VERSION ""

NS_ :

BS_:

BU_: Turbocharger OnBoardDataLogger OffBoardDiagnosticTool2 OffBoardDiagnosticTool1 FileServer ParkingBrakeController SeatControl2 FanDriveController SteeringColumnUnit CommunicationUnitRadio CommunicationUnitSatellite CommunicationUnitCellular PropulsionBatteryCharger ChassisController2 ChassisController1 EngineValveControl AuxiliaryHeater2 AuxiliaryHeater1 ClutchUnit RampControl InformationSystem1 SuspensionSystemController2 OilSensor VehicleDynamicStability ExhaustEmissionController TransmissionDisplay2 TransmissionDisplay1 ClimateControl2 WaterPumpController RearAxleSteeringController LightingOperatorControl SeatController1 IgnitionController2 IgnitionController1 TirePressureController CabController2 CabController1 PneumaticSystemController SuspensionSystemController1 HydraulicPumpController EnduranceBrakingSystem RetarderExhaustEngine2 OnBoardDiagnosticUnit HeadwayController RetarderExhaustEngine1 CabDisplay1 ManagementComputer VirtualTerminal OffVehicleGateway PowerTakeOffFront HitchControl AuxiliaryValveControl BodyController TractorTrailerBridge1 StarterSystem ElectricalSystem VehicleSecurity VehicleNavigation AerodynamicControl ElectricalChargingSystem ClimateControl1 TripRecorder InstrumentCluster SuspensionDriveAxle2 SuspensionDriveAxle1 SuspensionSteerAxle SteeringController FuelSystem CruiseControl RetarderDriveline RetarderEngine BrakesDriveAxle2 BrakesDriveAxle1 BrakesSystemController BrakesSteerAxle AxleDrive2 AxleDrive1 AxleSteering PowerTakeOff ShiftConsoleSecondary ShiftConsolePrimary Transmission2 Transmission1 Engine2 Engine1

BO_ 3221225472 VECTOR__INDEPENDENT_SIG_MSG: 0 Vector__XXX
 SG_ AuxI_O62 : 0|2@1+ (1,0) [0|3] "" Vector__XXX
 SG_ AuxI_O63 : 0|2@1+ (1,0) [0|3] "" Vector__XXX
 SG_ AuxI_O64 : 0|2@1+ (1,0) [0|3] "" Vector__XXX
 SG_ AuxI_O57 : 0|2@1+ (1,0) [0|3] "" Vector__XXX
 SG_ AuxI_O58 : 0|2@1+ (1,0) [0|3] "" Vector__XXX
 SG_ AuxI_O59 : 0|2@1+ (1,0) [0|3] "" Vector__XXX
 SG_ AuxI_O60 : 0|2@1+ (1,0) [0|3] "" Vector__XXX
 SG_ AuxI_O53 : 0|2@1+ (1,0) [0|3] "" Vector__XXX
 SG_ AuxI_O54 : 0|2@1+ (1,0) [0|3] "" Vector__XXX
 SG_ AuxI_O55 : 0|2@1+ (1,0) [0|3] "" Vector__XXX
 SG_ AuxI_O56 : 0|2@1+ (1,0) [0|3] "" Vector__XXX
 SG_ AuxI_O49 : 0|2@1+ (1,0) [0|3] "" Vector__XXX
 SG_ AuxI_O50 : 0|2@1+ (1,0) [0|3] "" Vector__XXX
 SG_ AuxI_O51 : 0|2@1+ (1,0) [0|3] "" Vector__XXX
 SG_ AuxI_O52 : 0|2@1+ (1,0) [0|3] "" Vector__XXX
 SG_ AuxI_O109 : 0|2@1+ (1,0) [0|3] "" Vector__XXX
 SG_ AuxI_O110 : 0|2@1+ (1,0) [0|3] "" Vector__XXX
 SG_ AuxI_O111 : 0|2@1+ (1,0) [0|3] "" Vector__XXX
 SG_ AuxI_O112 : 0|2@1+ (1,0) [0|3] "" Vector__XXX
 SG_ AuxI_O105 : 0|2@1+ (1,0) [0|3] "" Vector__XXX
 SG_ AuxI_O106 : 0|2@1+ (1,0) [0|3] "" Vector__XXX
 SG_ AuxI_O107 : 0|2@1+ (1,0) [0|3] "" Vector__XXX
 SG_ AuxI_O108 : 0|2@1+ (1,0) [0|3] "" Vector__XXX
 SG_ AuxI_O101 : 0|2@1+ (1,0) [0|3] "" Vector__XXX
 SG_ AuxI_O102 : 0|2@1+ (1,0) [0|3] "" Vector__XXX
 SG_ AuxI_O103 : 0|2@1+ (1,0) [0|3] "" Vector__XXX
 SG_ AuxI_O104 : 0|2@1+ (1,0) [0|3] "" Vector__XXX
 SG_ AuxI_O97 : 0|2@1+ (1,0) [0|3] "" Vector__XXX
 SG_ AuxI_O98 : 0|2@1+ (1,0) [0|3] "" Vector__XXX
 SG_ AuxI_O99 : 0|2@1+ (1,0) [0|3] "" Vector__XXX
 SG_ AuxI_O100 : 0|2@1+ (1,0) [0|3] "" Vector__XXX
 SG_ AuxI_O93 : 0|2@1+ (1,0) [0|3] "" Vector__XXX
 SG_ AuxI_O94 : 0|2@1+ (1,0) [0|3] "" Vector__XXX
 SG_ AuxI_O95 : 0|2@1+ (1,0) [0|3] "" Vector__XXX
 SG_ AuxI_O96 : 0|2@1+ (1,0) [0|3] "" Vector__XXX
 SG_ AuxI_O89 : 0|2@1+ (1,0) [0|3] "" Vector__XXX
 SG_ AuxI_O90 : 0|2@1+ (1,0) [0|3] "" Vector__XXX
 SG_ AuxI_O91 : 0|2@1+ (1,0) [0|3] "" Vector__XXX
 SG_ AuxI_O92 : 0|2@1+ (1,0) [0|3] "" Vector__XXX
 SG_ AuxI_O85 : 0|2@1+ (1,0) [0|3] "" Vector__XXX
 SG_ AuxI_O86 : 0|2@1+ (1,0) [0|3] "" Vector__XXX
 SG_ AuxI_O87 : 0|2@1+ (1,0) [0|3] "" Vector__XXX
 SG_ AuxI_O88 : 0|2@1+ (1,0) [0|3] "" Vector__XXX
 SG_ AuxI_O81 : 0|2@1+ (1,0) [0|3] "" Vector__XXX
 SG_ AuxI_O82 : 0|2@1+ (1,0) [0|3] "" Vector__XXX
 SG_ AuxI_O83 : 0|2@1+ (1,0) [0|3] "" Vector__XXX
 SG_ AuxI_O84 : 0|2@1+ (1,0) [0|3] "" Vector__XXX
 SG_ TrailerBrakeStrokeAxle5Right : 0|3@1+ (1,0) [0|7] "" Vector__XXX
 SG_ TrailerBrakeStrokeAxle5Left : 0|3@1+ (1,0) [0|7] "" Vector__XXX
 SG_ TrailerBrakeStrokeAxle4Right : 0|3@1+ (1,0) [0|7] "" Vector__XXX
 SG_ TrailerBrakeStrokeAxle4Left : 0|3@1+ (1,0) [0|7] "" Vector__XXX
 SG_ TrailerBrakeStrokeAxle3Right : 0|3@1+ (1,0) [0|7] "" Vector__XXX
 SG_ TrailerBrakeStrokeAxle3Left : 0|3@1+ (1,0) [0|7] "" Vector__XXX
 SG_ TrailerBrakeStrokeAxle2Right : 0|3@1+ (1,0) [0|7] "" Vector__XXX
 SG_ TrailerBrakeStrokeAxle2Left : 0|3@1+ (1,0) [0|7] "" Vector__XXX
 SG_ TrailerBrakeStrokeAxle1Right : 0|3@1+ (1,0) [0|7] "" Vector__XXX
 SG_ TrailerBrakeStrokeAxle1Left : 0|3@1+ (1,0) [0|7] "" Vector__XXX
 SG_ TractorBrakeStrokeAxle5Right : 0|3@1+ (1,0) [0|7] "" Vector__XXX
 SG_ TractorBrakeStrokeAxle5Left : 0|3@1+ (1,0) [0|7] "" Vector__XXX
 SG_ TractorBrakeStrokeAxle4Right : 0|3@1+ (1,0) [0|7] "" Vector__XXX
 SG_ TractorBrakeStrokeAxle4Left : 0|3@1+ (1,0) [0|7] "" Vector__XXX
 SG_ TractorBrakeStrokeAxle3Right : 0|3@1+ (1,0) [0|7] "" Vector__XXX
 SG_ TractorBrakeStrokeAxle3Left : 0|3@1+ (1,0) [0|7] "" Vector__XXX
 SG_ TractorBrakeStrokeAxle2Right : 0|3@1+ (1,0) [0|7] "" Vector__XXX
 SG_ TractorBrakeStrokeAxle2Left : 0|3@1+ (1,0) [0|7] "" Vector__XXX
 SG_ TractorBrakeStrokeAxle1Right : 0|3@1+ (1,0) [0|7] "" Vector__XXX
 SG_ TractorBrakeStrokeAxle1Left : 0|3@1+ (1,0) [0|7] "" Vector__XXX
 SG_ RoadSurfaceTemp : 0|16@1+ (0.03125,-273) [-273|1734.96875] "deg C" Vector__XXX
 SG_ EngAirIntakeTemp : 0|8@1+ (1,-40) [-40|210] "deg C" Vector__XXX
 SG_ AmbientAirTemp : 0|16@1+ (0.03125,-273) [-273|1734.96875] "deg C" Vector__XXX
 SG_ CabInteriorTemp : 0|16@1+ (0.03125,-273) [-273|1734.96875] "deg C" Vector__XXX
 SG_ BarometricPress : 0|8@1+ (0.5,0) [0|125] "kPa" Vector__XXX
 SG_ EngAirStartPress : 0|8@1+ (4,0) [0|1000] "kPa" Vector__XXX
 SG_ AirCompressorStatus : 0|2@1+ (1,0) [0|3] "" Vector__XXX
 SG_ AirSuspensionSupplyPress : 0|8@1+ (8,0) [0|2000] "kPa" Vector__XXX
 SG_ AuxEquipmentSupplyPress : 0|8@1+ (8,0) [0|2000] "kPa" Vector__XXX
 SG_ ServiceBrakeCircuit2AirPress : 0|8@1+ (8,0) [0|2000] "kPa" Vector__XXX
 SG_ ServiceBrakeCircuit1AirPress : 0|8@1+ (8,0) [0|2000] "kPa" Vector__XXX
 SG_ ParkingAnd_orTrailerAirPress : 0|8@1+ (8,0) [0|2000] "kPa" Vector__XXX
 SG_ PneumaticSupplyPress : 0|8@1+ (8,0) [0|2000] "kPa" Vector__XXX
 SG_ SteerAxleLubePress : 0|8@1+ (4,0) [0|1000] "kPa" Vector__XXX
 SG_ SteerAxleTemp : 0|8@1+ (1,-40) [-40|210] "deg C" Vector__XXX
 SG_ DriveAxleLubePress : 0|8@1+ (4,0) [0|1000] "kPa" Vector__XXX
 SG_ DriveAxleTemp : 0|8@1+ (1,-40) [-40|210] "deg C" Vector__XXX
 SG_ DriveAxleLiftAirPress : 0|8@1+ (4,0) [0|1000] "kPa" Vector__XXX
 SG_ DriveAxleLocation : 0|8@1+ (1.02,0) [0|255] "" Vector__XXX
 SG_ EngGsMssFlwSnsrFuelingCorrection : 0|8@1+ (1,-125) [-125|125] "%" Vector__XXX
 SG_ EngTurboWastegateValvePos : 0|8@1+ (0.4,0) [0|100] "%" Vector__XXX
 SG_ EngDesiredAbsIntakeManifoldPress : 0|16@1+ (1,0) [0|6425.5] "kPa" Vector__XXX
 SG_ EngGasFuelCorrectionFactor : 0|8@1+ (1,0) [0|250] "%" Vector__XXX
 SG_ RequestedACCDistanceMode : 0|3@1+ (1,0) [0|7] "" Vector__XXX
 SG_ ACCUsageDemand : 0|2@1+ (1,0) [0|3] "" Vector__XXX
 SG_ ForwardCollisionWarning : 0|2@1+ (1,0) [0|3] "" Vector__XXX
 SG_ ACCDistanceAlertSignal : 0|2@1+ (1,0) [0|3] "" Vector__XXX
 SG_ ACCSystemShutoffWarning : 0|2@1+ (1,0) [0|3] "" Vector__XXX
 SG_ ACCTargetDetected : 0|2@1+ (1,0) [0|3] "" Vector__XXX
 SG_ AdptiveCruiseCtrlSetDistanceMode : 0|3@1+ (1,0) [0|7] "" Vector__XXX
 SG_ AdaptiveCruiseCtrlMode : 0|3@1+ (1,0) [0|7] "" Vector__XXX
 SG_ AdaptiveCruiseCtrlSetSpeed : 0|8@1+ (1,0) [0|250] "km/h" Vector__XXX
 SG_ DistanceToForwardVehicle : 0|8@1+ (1,0) [0|250] "m" Vector__XXX
 SG_ SpeedOfForwardVehicle : 0|8@1+ (1,0) [0|250] "km/h" Vector__XXX
 SG_ ArticulationAngle : 0|8@1+ (1,-125) [-125|125] "deg" Vector__XXX
 SG_ RelativeHumidity : 0|8@1+ (0.4,0) [0|100] "%" Vector__XXX
 SG_ AuxLevel : 0|16@1+ (0.1,0) [0|6425.5] "mm" Vector__XXX
 SG_ AuxPress2 : 0|8@1+ (16,0) [0|4000] "kPa" Vector__XXX
 SG_ AuxPress1 : 0|8@1+ (16,0) [0|4000] "kPa" Vector__XXX
 SG_ AuxTemp2 : 0|8@1+ (1,-40) [-40|210] "deg C" Vector__XXX
 SG_ AuxTemp1 : 0|8@1+ (1,-40) [-40|210] "deg C" Vector__XXX
 SG_ EngBlowerBypassValvePos : 0|8@1+ (0.4,0) [0|100] "%" Vector__XXX
 SG_ EngGasSupplyPress : 0|16@1+ (0.5,0) [0|32127.5] "kPa" Vector__XXX
 SG_ AddressBusy : 0|8@1+ (1,0) [0|255] "" Vector__XXX
 SG_ GroupFunctionValue : 0|8@1+ (1,0) [0|255] "" Vector__XXX
 SG_ AddressAccessDenied : 0|8@1+ (1,0) [0|255] "" Vector__XXX
 SG_ AddressNegativeAcknowledgement : 0|8@1+ (1,0) [0|255] "" Vector__XXX
 SG_ AddressAcknowledged : 0|8@1+ (1,0) [0|255] "" Vector__XXX
 SG_ Status2OfDoors : 0|2@1+ (1,0) [0|3] "" Vector__XXX
 SG_ Ramp_WheelChairLiftPos : 0|2@1+ (1,0) [0|3] "" Vector__XXX
 SG_ PosOfDoors : 0|4@1+ (1,0) [0|15] "" Vector__XXX
 SG_ FifthWheelRollWarningIndicator : 0|2@1+ (1,0) [0|3] "" Vector__XXX
 SG_ FifthWheelRollMoment : 0|16@1+ (10,-320000) [-320000|322550] "N" Vector__XXX
 SG_ FifthWheelDrawbarForce : 0|16@1+ (10,-320000) [-320000|322550] "N" Vector__XXX
 SG_ FifthWheelVerticalForce : 0|16@1+ (5,0) [0|321275] "N" Vector__XXX
 SG_ FifthWheelSliderLockIndicator : 0|2@1+ (1,0) [0|3] "" Vector__XXX
 SG_ FifthWheelSliderPos : 0|8@1+ (10,0) [0|2500] "mm" Vector__XXX
 SG_ FfthWhlLockCoupleStatusIndicator : 0|2@1+ (1,0) [0|3] "" Vector__XXX
 SG_ FfthWhlLckReadyToCoupleIndicator : 0|2@1+ (1,0) [0|3] "" Vector__XXX
 SG_ FifthWheelErrorStatus : 0|4@1+ (1,0) [0|15] "" Vector__XXX
 SG_ RollAndPitchMeasurementLatency : 0|8@1+ (0.5,0) [0|125] "ms" Vector__XXX
 SG_ PitchAndRollCompensated : 0|2@1+ (1,0) [0|3] "" Vector__XXX
 SG_ PitchRateFigureOfMerit : 0|2@1+ (1,0) [0|3] "" Vector__XXX
 SG_ RollAngleFigureOfMerit : 0|2@1+ (1,0) [0|3] "" Vector__XXX
 SG_ PitchAngleFigureOfMerit : 0|2@1+ (1,0) [0|3] "" Vector__XXX
 SG_ PitchRate : 0|16@1+ (0.002,-64) [-64|64.51] "deg/sec" Vector__XXX
 SG_ RollAngle : 0|16@1+ (0.002,-64) [-64|64.51] "deg" Vector__XXX
 SG_ PitchAngle : 0|16@1+ (0.002,-64) [-64|64.51] "deg" Vector__XXX
 SG_ TransOilLevelMeasurementStatus : 0|4@1+ (1,0) [0|15] "" Vector__XXX
 SG_ TransOilLevelCountdownTimer : 0|4@1+ (1,0) [0|15] "" Vector__XXX
 SG_ TransOilLevelHigh_Low : 0|8@1+ (0.5,-62.5) [-62.5|62.5] "L" Vector__XXX
 SG_ TransOilTemp : 0|16@1+ (0.03125,-273) [-273|1734.96875] "deg C" Vector__XXX
 SG_ TransOilPress : 0|8@1+ (16,0) [0|4000] "kPa" Vector__XXX
 SG_ TransFilterDiffPress : 0|8@1+ (2,0) [0|500] "kPa" Vector__XXX
 SG_ TransOilLevel : 0|8@1+ (0.4,0) [0|100] "%" Vector__XXX
 SG_ ClutchPress : 0|8@1+ (16,0) [0|4000] "kPa" Vector__XXX
 SG_ ChargingSystemPotential : 0|16@1+ (0.05,0) [0|3212.75] "V" Vector__XXX
 SG_ KeyswitchBatteryPotential : 0|16@1+ (0.05,0) [0|3212.75] "V" Vector__XXX
 SG_ BatteryPotential_PowerInput1 : 0|16@1+ (0.05,0) [0|3212.75] "V" Vector__XXX
 SG_ WrelessCommunicationNetworkType2 : 0|8@1+ (1,0) [0|255] "" Vector__XXX
 SG_ NetworkSignalStrength2 : 0|8@1+ (1,0) [0|100] "%" Vector__XXX
 SG_ NetworkAntennaStatus2 : 0|8@1+ (1,0) [0|255] "" Vector__XXX
 SG_ NetworkServiceStatus2 : 0|8@1+ (1,0) [0|255] "" Vector__XXX
 SG_ NetworkTransceiverStatus2 : 0|8@1+ (1,0) [0|255] "" Vector__XXX
 SG_ WrelessCommunicationNetworkType1 : 0|8@1+ (1,0) [0|255] "" Vector__XXX
 SG_ NetworkSignalStrength1 : 0|8@1+ (1,0) [0|100] "%" Vector__XXX
 SG_ NetworkAntennaStatus1 : 0|8@1+ (1,0) [0|255] "" Vector__XXX
 SG_ NetworkServiceStatus1 : 0|8@1+ (1,0) [0|255] "" Vector__XXX
 SG_ NetworkTransceiverStatus1 : 0|8@1+ (1,0) [0|255] "" Vector__XXX
 SG_ VoltageRegulatorEnabled : 0|2@1+ (1,0) [0|3] "" Vector__XXX
 SG_ VoltageRegulatorSoftStartState : 0|2@1+ (1,0) [0|3] "" Vector__XXX
 SG_ VltgRgltrUndrfrqncyCmpnstnEnbld : 0|2@1+ (1,0) [0|3] "" Vector__XXX
 SG_ VltgRgltrVAr_PwrFctrOprtingMode : 0|3@1+ (1,0) [0|7] "" Vector__XXX
 SG_ VltgRglatorLoadCompensationMode : 0|3@1+ (1,0) [0|7] "" Vector__XXX
 SG_ GnrtrOtputVoltageBiasPercentage : 0|16@1+ (0.1,-100) [-100|100] "%" Vector__XXX
 SG_ GeneratorExcitationFieldCurrent : 0|16@1+ (0.05,0) [0|3217.5] "A" Vector__XXX
 SG_ GeneratorExcitationFieldVoltage : 0|16@1+ (0.05,-1605.625) [-1605.625|1606.375] "V" Vector__XXX
 SG_ RunningLightCmd : 0|2@1+ (1,0) [0|3] "" Vector__XXX
 SG_ AltBeamHeadLightCmd : 0|2@1+ (1,0) [0|3] "" Vector__XXX
 SG_ LowBeamHeadLightCmd : 0|2@1+ (1,0) [0|3] "" Vector__XXX
 SG_ HighBeamHeadLightCmd : 0|2@1+ (1,0) [0|3] "" Vector__XXX
 SG_ TractorFrontFogLightsCmd : 0|2@1+ (1,0) [0|3] "" Vector__XXX
 SG_ RotatingBeaconLightCmd : 0|2@1+ (1,0) [0|3] "" Vector__XXX
 SG_ RightTurnSignalLightsCmd : 0|2@1+ (1,0) [0|3] "" Vector__XXX
 SG_ LeftTurnSignalLightsCmd : 0|2@1+ (1,0) [0|3] "" Vector__XXX
 SG_ BackUpLightAndAlarmHornCmd : 0|2@1+ (1,0) [0|3] "" Vector__XXX
 SG_ CenterStopLightCmd : 0|2@1+ (1,0) [0|3] "" Vector__XXX
 SG_ RightStopLightCmd : 0|2@1+ (1,0) [0|3] "" Vector__XXX
 SG_ LeftStopLightCmd : 0|2@1+ (1,0) [0|3] "" Vector__XXX
 SG_ ImplementClearanceLightCmd : 0|2@1+ (1,0) [0|3] "" Vector__XXX
 SG_ TractorClearanceLightCmd : 0|2@1+ (1,0) [0|3] "" Vector__XXX
 SG_ ImplementMarkerLightCmd : 0|2@1+ (1,0) [0|3] "" Vector__XXX
 SG_ TractorMarkerLightCmd : 0|2@1+ (1,0) [0|3] "" Vector__XXX
 SG_ RearFogLightCmd : 0|2@1+ (1,0) [0|3] "" Vector__XXX
 SG_ TrctrUndrsdeMountedWorkLightsCmd : 0|2@1+ (1,0) [0|3] "" Vector__XXX
 SG_ TrctrRearLowMountedWorkLightsCmd : 0|2@1+ (1,0) [0|3] "" Vector__XXX
 SG_ TrctrRarHighMountedWorkLightsCmd : 0|2@1+ (1,0) [0|3] "" Vector__XXX
 SG_ TrctrSideLowMountedWorkLightsCmd : 0|2@1+ (1,0) [0|3] "" Vector__XXX
 SG_ TrctrSdeHighMountedWorkLightsCmd : 0|2@1+ (1,0) [0|3] "" Vector__XXX
 SG_ TrctrFrntLowMountedWorkLightsCmd : 0|2@1+ (1,0) [0|3] "" Vector__XXX
 SG_ TrctrFrntHghMountedWorkLightsCmd : 0|2@1+ (1,0) [0|3] "" Vector__XXX
 SG_ ImplementOEMOption2LightCmd : 0|2@1+ (1,0) [0|3] "" Vector__XXX
 SG_ ImplementOEMOption1LightCmd : 0|2@1+ (1,0) [0|3] "" Vector__XXX
 SG_ ImplementRightFacingWorkLightCmd : 0|2@1+ (1,0) [0|3] "" Vector__XXX
 SG_ ImplementLeftFacingWorkLightCmd : 0|2@1+ (1,0) [0|3] "" Vector__XXX
 SG_ LightingDataRqCmd : 0|2@1+ (1,0) [0|3] "" Vector__XXX
 SG_ ImplmentRightForwardWorkLightCmd : 0|2@1+ (1,0) [0|3] "" Vector__XXX
 SG_ ImplementLeftForwardWorkLightCmd : 0|2@1+ (1,0) [0|3] "" Vector__XXX
 SG_ ImplementRearWorkLightCmd : 0|2@1+ (1,0) [0|3] "" Vector__XXX
 SG_ ActualInnerWheelSteerAngle : 0|16@1+ (0.0038907478017275,-125) [-125|125] "deg" Vector__XXX
 SG_ StatusOfSteerAxle : 0|4@1+ (1,0) [0|15] "" Vector__XXX
 SG_ SteerableLiftAxleLoweringInhibit : 0|2@1+ (1,0) [0|3] "" Vector__XXX
 SG_ SteerType : 0|4@1+ (1,0) [0|15] "" Vector__XXX
 SG_ TypeOfSteerForces : 0|4@1+ (1,0) [0|15] "" Vector__XXX
 SG_ TypeOfSteerTrans : 0|4@1+ (1,0) [0|15] "" Vector__XXX
 SG_ ASREngCtrlActive : 0|2@1+ (1,0) [0|3] "" Vector__XXX
 SG_ ASRBrakeCtrlActive : 0|2@1+ (1,0) [0|3] "" Vector__XXX
 SG_ AntiLockBrakingActive : 0|2@1+ (1,0) [0|3] "" Vector__XXX
 SG_ ABSOffroadSwitch : 0|2@1+ (1,0) [0|3] "" Vector__XXX
 SG_ ASROffroadSwitch : 0|2@1+ (1,0) [0|3] "" Vector__XXX
 SG_ ASRHillHolderSwitch : 0|2@1+ (1,0) [0|3] "" Vector__XXX
 SG_ TractionCtrlOverrideSwitch : 0|2@1+ (1,0) [0|3] "" Vector__XXX
 SG_ AccelInterlockSwitch : 0|2@1+ (1,0) [0|3] "" Vector__XXX
 SG_ EngDerateSwitch : 0|2@1+ (1,0) [0|3] "" Vector__XXX
 SG_ EngAuxShutdownSwitch : 0|2@1+ (1,0) [0|3] "" Vector__XXX
 SG_ RemoteAccelEnableSwitch : 0|2@1+ (1,0) [0|3] "" Vector__XXX
 SG_ EngRetarderSelection : 0|8@1+ (0.4,0) [0|100] "%" Vector__XXX
 SG_ ABSFullyOperational : 0|2@1+ (1,0) [0|3] "" Vector__XXX
 SG_ EBSRedWarningSignal : 0|2@1+ (1,0) [0|3] "" Vector__XXX
 SG_ ABS_EBSAmberWarningSignal : 0|2@1+ (1,0) [0|3] "" Vector__XXX
 SG_ ATC_ASRInformationSignal : 0|2@1+ (1,0) [0|3] "" Vector__XXX
 SG_ SrcAddrssOfCntrllngDvcFrBrkeCtrl : 0|8@1+ (1,0) [0|255] "" Vector__XXX
 SG_ HaltBrakeSwitch : 0|2@1+ (1,0) [0|3] "" Vector__XXX
 SG_ TrailerABSStatus : 0|2@1+ (1,0) [0|3] "" Vector__XXX
 SG_ TrctrMntdTrailerABSWarningSignal : 0|2@1+ (1,0) [0|3] "" Vector__XXX
 SG_ RelativeSpeedFrontAxleLeftWheel : 0|8@1+ (0.0625,-7.8125) [-7.8125|7.8125] "km/h" Vector__XXX
 SG_ RelativeSpeedFrontAxleRightWheel : 0|8@1+ (0.0625,-7.8125) [-7.8125|7.8125] "km/h" Vector__XXX
 SG_ RelativeSpeedRearAxle1LeftWheel : 0|8@1+ (0.0625,-7.8125) [-7.8125|7.8125] "km/h" Vector__XXX
 SG_ RelativeSpeedRearAxle1RightWheel : 0|8@1+ (0.0625,-7.8125) [-7.8125|7.8125] "km/h" Vector__XXX
 SG_ RelativeSpeedRearAxle2LeftWheel : 0|8@1+ (0.0625,-7.8125) [-7.8125|7.8125] "km/h" Vector__XXX
 SG_ RelativeSpeedRearAxle2RightWheel : 0|8@1+ (0.0625,-7.8125) [-7.8125|7.8125] "km/h" Vector__XXX
 SG_ ImplementRearWorkLight : 0|2@1+ (1,0) [0|3] "" Vector__XXX
 SG_ ImplementLeftForwardWorkLight : 0|2@1+ (1,0) [0|3] "" Vector__XXX
 SG_ ImplementRightForwardWorkLight : 0|2@1+ (1,0) [0|3] "" Vector__XXX
 SG_ ImplementLeftFacingWorkLight : 0|2@1+ (1,0) [0|3] "" Vector__XXX
 SG_ ImplementRightFacingWorkLight : 0|2@1+ (1,0) [0|3] "" Vector__XXX
 SG_ ImplementOEMOption1Light : 0|2@1+ (1,0) [0|3] "" Vector__XXX
 SG_ ImplementOEMOption2Light : 0|2@1+ (1,0) [0|3] "" Vector__XXX
 SG_ TrctorFrontHighMountedWorkLights : 0|2@1+ (1,0) [0|3] "" Vector__XXX
 SG_ TractorFrontLowMountedWorkLights : 0|2@1+ (1,0) [0|3] "" Vector__XXX
 SG_ TractorSideHighMountedWorkLights : 0|2@1+ (1,0) [0|3] "" Vector__XXX
 SG_ TractorSideLowMountedWorkLights : 0|2@1+ (1,0) [0|3] "" Vector__XXX
 SG_ TractorRearHighMountedWorkLights : 0|2@1+ (1,0) [0|3] "" Vector__XXX
 SG_ TractorRearLowMountedWorkLights : 0|2@1+ (1,0) [0|3] "" Vector__XXX
 SG_ TrctorUndersideMountedWorkLights : 0|2@1+ (1,0) [0|3] "" Vector__XXX
 SG_ RearFogLights : 0|2@1+ (1,0) [0|3] "" Vector__XXX
 SG_ TractorMarkerLight : 0|2@1+ (1,0) [0|3] "" Vector__XXX
 SG_ ImplementMarkerLight : 0|2@1+ (1,0) [0|3] "" Vector__XXX
 SG_ TractorClearanceLight : 0|2@1+ (1,0) [0|3] "" Vector__XXX
 SG_ ImplementClearanceLight : 0|2@1+ (1,0) [0|3] "" Vector__XXX
 SG_ LeftStopLight : 0|2@1+ (1,0) [0|3] "" Vector__XXX
 SG_ RightStopLight : 0|2@1+ (1,0) [0|3] "" Vector__XXX
 SG_ CenterStopLight : 0|2@1+ (1,0) [0|3] "" Vector__XXX
 SG_ BackUpLightAndAlarmHorn : 0|2@1+ (1,0) [0|3] "" Vector__XXX
 SG_ RotatingBeaconLight : 0|2@1+ (1,0) [0|3] "" Vector__XXX
 SG_ TractorFrontFogLights : 0|2@1+ (1,0) [0|3] "" Vector__XXX
 SG_ HighBeamHeadLightData : 0|2@1+ (1,0) [0|3] "" Vector__XXX
 SG_ LowBeamHeadLightData : 0|2@1+ (1,0) [0|3] "" Vector__XXX
 SG_ AltBeamHeadLightData : 0|2@1+ (1,0) [0|3] "" Vector__XXX
 SG_ RunningLight : 0|2@1+ (1,0) [0|3] "" Vector__XXX
 SG_ VehicleOverspeed : 0|2@1+ (1,0) [0|3] "" Vector__XXX
 SG_ VehicleMotion : 0|2@1+ (1,0) [0|3] "" Vector__XXX
 SG_ TachographOutputShaftSpeed : 0|16@1+ (0.125,0) [0|8031.875] "rpm" Vector__XXX
 SG_ DirectionIndicator : 0|2@1+ (1,0) [0|3] "" Vector__XXX
 SG_ TachographPerformance : 0|2@1+ (1,0) [0|3] "" Vector__XXX
 SG_ HandlingInformation : 0|2@1+ (1,0) [0|3] "" Vector__XXX
 SG_ SystemEvent : 0|2@1+ (1,0) [0|3] "" Vector__XXX
 SG_ DriverCardDriver2 : 0|2@1+ (1,0) [0|3] "" Vector__XXX
 SG_ Driver2TimeRelatedStates : 0|4@1+ (1,0) [0|15] "" Vector__XXX
 SG_ DriverCardDriver1 : 0|2@1+ (1,0) [0|3] "" Vector__XXX
 SG_ Driver1TimeRelatedStates : 0|4@1+ (1,0) [0|15] "" Vector__XXX
 SG_ Driver2WorkingState : 0|3@1+ (1,0) [0|7] "" Vector__XXX
 SG_ Driver1WorkingState : 0|3@1+ (1,0) [0|7] "" Vector__XXX
 SG_ RearWasherFunction : 0|3@1+ (1,0) [0|7] "" Vector__XXX
 SG_ FrontOperatorWasherSwitch : 0|3@1+ (1,0) [0|7] "" Vector__XXX
 SG_ FrontNonoperatorWasherSwitch : 0|3@1+ (1,0) [0|7] "" Vector__XXX
 SG_ RearWiperDelayCtrl : 0|8@1+ (0.4,0) [0|100] "%" Vector__XXX
 SG_ FrontNonoperatorWiperDelayCtrl : 0|8@1+ (0.4,0) [0|100] "%" Vector__XXX
 SG_ FrontOperatorWiperDelayCtrl : 0|8@1+ (0.4,0) [0|100] "%" Vector__XXX
 SG_ RearWiperSwitch : 0|4@1+ (1,0) [0|15] "" Vector__XXX
 SG_ FrontOperatorWiperSwitch : 0|4@1+ (1,0) [0|15] "" Vector__XXX
 SG_ FrontNonoperatorWiperSwitch : 0|4@1+ (1,0) [0|15] "" Vector__XXX
 SG_ OprtorsDesiredDelayedLampOffTime : 0|16@1+ (1,0) [0|64255] "s" Vector__XXX
 SG_ OperatorsDesiredBacklight : 0|8@1+ (0.4,0) [0|100] "%" Vector__XXX
 SG_ HighLowBeamSwitch : 0|2@1+ (1,0) [0|3] "" Vector__XXX
 SG_ HazardLightSwitch : 0|2@1+ (1,0) [0|3] "" Vector__XXX
 SG_ TurnSignalSwitch : 0|4@1+ (1,0) [0|15] "" Vector__XXX
 SG_ MainLightSwitch : 0|4@1+ (1,0) [0|15] "" Vector__XXX
 SG_ WorkLightSwitch : 0|4@1+ (1,0) [0|15] "" Vector__XXX
 SG_ LaneDepartureImminentLeftSide : 0|2@1+ (1,0) [0|3] "" Vector__XXX
 SG_ LaneDepartureImminentRightSide : 0|2@1+ (1,0) [0|3] "" Vector__XXX
 SG_ LaneDepartureRight : 0|2@1+ (1,0) [0|3] "" Vector__XXX
 SG_ LaneDepartureLeft : 0|2@1+ (1,0) [0|3] "" Vector__XXX
 SG_ TransCurrentRange : 0|16@1+ (1,0) [0|255] "per byte" Vector__XXX
 SG_ TransRequestedRange : 0|16@1+ (1,0) [0|255] "per byte" Vector__XXX
 SG_ TransCurrentGear : 0|8@1+ (1,-125) [-125|125] "" Vector__XXX
 SG_ TransActualGearRatio : 0|16@1+ (0.001,0) [0|64.255] "" Vector__XXX
 SG_ TransSelectedGear : 0|8@1+ (1,-125) [-125|125] "" Vector__XXX
 SG_ ActlMxAvlblRetarderPercentTorque : 0|8@1+ (1,-125) [-125|125] "%" Vector__XXX
 SG_ RetarderSelectionNonengine : 0|8@1+ (0.4,0) [0|100] "%" Vector__XXX
 SG_ DrvrsDemandRetarderPercentTorque : 0|8@1+ (1,-125) [-125|125] "%" Vector__XXX
 SG_ SrcAddrssOfCntrllngDvcFrRtrdrCtr : 0|8@1+ (1,0) [0|255] "" Vector__XXX
 SG_ RetarderRoadSpeedExceededStatus : 0|2@1+ (1,0) [0|3] "" Vector__XXX
 SG_ RetarderRoadSpeedLimitSwitch : 0|2@1+ (1,0) [0|3] "" Vector__XXX
 SG_ RetarderRequestingBrakeLight : 0|2@1+ (1,0) [0|3] "" Vector__XXX
 SG_ EngCoolantLoadIncrease : 0|2@1+ (1,0) [0|3] "" Vector__XXX
 SG_ IntendedRetarderPercentTorque : 0|8@1+ (1,-125) [-125|125] "%" Vector__XXX
 SG_ ActualRetarderPercentTorque : 0|8@1+ (1,-125) [-125|125] "%" Vector__XXX
 SG_ RetarderEnableShiftAssistSwitch : 0|2@1+ (1,0) [0|3] "" Vector__XXX
 SG_ RetarderEnableBrakeAssistSwitch : 0|2@1+ (1,0) [0|3] "" Vector__XXX
 SG_ RetarderTorqueMode : 0|4@1+ (1,0) [0|15] "" Vector__XXX
 SG_ EstPumpingPercentTorque : 0|8@1+ (1,-125) [-125|125] "%" Vector__XXX
 SG_ ActlMaxAvailableEngPercentTorque : 0|8@1+ (0.4,0) [0|100] "%" Vector__XXX
 SG_ SCRThermalManagementActive : 0|2@1+ (1,0) [0|3] "" Vector__XXX
 SG_ DPFThermalManagementActive : 0|2@1+ (1,0) [0|3] "" Vector__XXX
 SG_ MmntaryEngMaxPowerEnableFeedback : 0|2@1+ (1,0) [0|3] "" Vector__XXX
 SG_ VhcleAccelerationRateLimitStatus : 0|2@1+ (1,0) [0|3] "" Vector__XXX
 SG_ AccelPedalPos2 : 0|8@1+ (0.4,0) [0|100] "%" Vector__XXX
 SG_ RemoteAccelPedalPos : 0|8@1+ (0.4,0) [0|100] "%" Vector__XXX
 SG_ AccelPedal2LowIdleSwitch : 0|2@1+ (1,0) [0|3] "" Vector__XXX
 SG_ RoadSpeedLimitStatus : 0|2@1+ (1,0) [0|3] "" Vector__XXX
 SG_ AccelPedalKickdownSwitch : 0|2@1+ (1,0) [0|3] "" Vector__XXX
 SG_ AccelPedal1LowIdleSwitch : 0|2@1+ (1,0) [0|3] "" Vector__XXX
 SG_ EngShutdownOverrideSwitch : 0|2@1+ (1,0) [0|3] "" Vector__XXX
 SG_ EngTestModeSwitch : 0|2@1+ (1,0) [0|3] "" Vector__XXX
 SG_ EngIdleDecrementSwitch : 0|2@1+ (1,0) [0|3] "" Vector__XXX
 SG_ EngIdleIncrementSwitch : 0|2@1+ (1,0) [0|3] "" Vector__XXX
 SG_ CruiseCtrlStates : 0|3@1+ (1,0) [0|7] "" Vector__XXX
 SG_ PTOGovernorState : 0|5@1+ (1,0) [0|31] "" Vector__XXX
 SG_ CruiseCtrlSetSpeed : 0|8@1+ (1,0) [0|250] "km/h" Vector__XXX
 SG_ CruiseCtrlAccelerateSwitch : 0|2@1+ (1,0) [0|3] "" Vector__XXX
 SG_ CruiseCtrlResumeSwitch : 0|2@1+ (1,0) [0|3] "" Vector__XXX
 SG_ CruiseCtrlCoastSwitch : 0|2@1+ (1,0) [0|3] "" Vector__XXX
 SG_ CruiseCtrlSetSwitch : 0|2@1+ (1,0) [0|3] "" Vector__XXX
 SG_ ClutchSwitch : 0|2@1+ (1,0) [0|3] "" Vector__XXX
 SG_ BrakeSwitch : 0|2@1+ (1,0) [0|3] "" Vector__XXX
 SG_ CruiseCtrlEnableSwitch : 0|2@1+ (1,0) [0|3] "" Vector__XXX
 SG_ CruiseCtrlActive : 0|2@1+ (1,0) [0|3] "" Vector__XXX
 SG_ ParkBrakeReleaseInhibitRq : 0|2@1+ (1,0) [0|3] "" Vector__XXX
 SG_ CruiseCtrlPauseSwitch : 0|2@1+ (1,0) [0|3] "" Vector__XXX
 SG_ ParkingBrakeSwitch : 0|2@1+ (1,0) [0|3] "" Vector__XXX
 SG_ TwoSpeedAxleSwitch : 0|2@1+ (1,0) [0|3] "" Vector__XXX

BO_ 2566799614 LD: 8 Vector__XXX
 SG_ LeftTurnSignalLights : 14|2@1+ (1,0) [0|3] "" Vector__XXX
 SG_ RightTurnSignalLights : 12|2@1+ (1,0) [0|3] "" Vector__XXX

BO_ 2566844926 CCVS: 8 Vector__XXX
 SG_ WheelBasedVehicleSpeed : 8|16@1+ (0.0039062485409696,0) [0|250.996] "km/h" Vector__XXX

BO_ 2565865739 EBC1: 2 Vector__XXX
 SG_ BrakePedalPos : 8|8@1+ (0.4,0) [0|100] "%" Vector__XXX
 SG_ EBSBrakeSwitch : 6|2@1+ (1,0) [0|3] "" Vector__XXX

BO_ 2364539687 EEC2: 8 Vector__XXX
 SG_ AccelPedalPos1 : 8|8@1+ (0.4,0) [0|100] "%" Vector__XXX

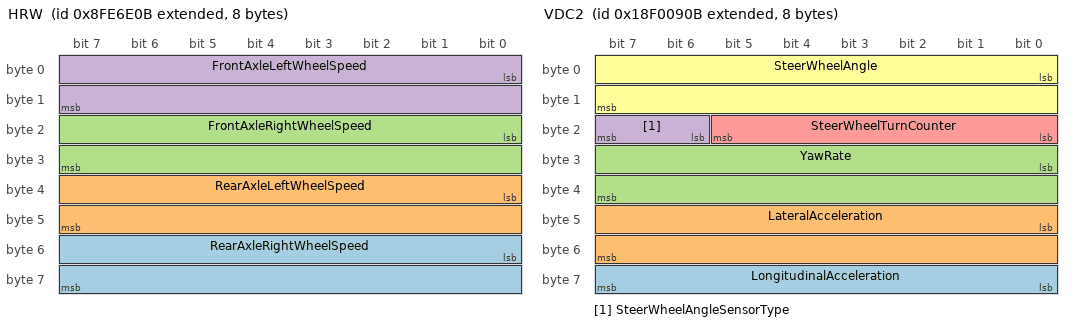
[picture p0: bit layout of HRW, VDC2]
BO_ 2298375691 HRW: 8 Vector__XXX
 SG_ RearAxleRightWheelSpeed : 48|16@1+ (0.0039062485409696,0) [0|250.996] "km/h" Vector__XXX
 SG_ RearAxleLeftWheelSpeed : 32|16@1+ (0.0039062485409696,0) [0|250.996] "km/h" Vector__XXX
 SG_ FrontAxleRightWheelSpeed : 16|16@1+ (0.0039062485409696,0) [0|250.996] "km/h" Vector__XXX
 SG_ FrontAxleLeftWheelSpeed : 0|16@1+ (0.0039062485409696,0) [0|250.996] "km/h" Vector__XXX

BO_ 2566831883 EBC2: 2 Vector__XXX
 SG_ FrontAxleSpeed : 0|16@1+ (0.0039062485409696,0) [0|250.996] "km/h" Vector__XXX

BO_ 2565867787 VDC2: 8 Vector__XXX
 SG_ LongitudinalAcceleration : 56|8@1+ (0.1,-12.5) [-12.5|12.5] "m/s²" Vector__XXX
 SG_ LateralAcceleration : 40|16@1+ (0.00048827328612559,-15.687) [-15.687|15.687] "m/s²" Vector__XXX
 SG_ YawRate : 24|16@1+ (0.00012201385106217,-3.92) [-3.92|3.92] "rad/s" Vector__XXX
 SG_ SteerWheelAngleSensorType : 22|2@1+ (1,0) [0|3] "" Vector__XXX
 SG_ SteerWheelTurnCounter : 16|6@1+ (1,-32) [-32|29] "turns" Vector__XXX
 SG_ SteerWheelAngle : 0|16@1+ (0.00097654657225119,-31.374) [-31.374|31.374] "rad" Vector__XXX

BO_ 2365484055 TCO1: 8 Vector__XXX
 SG_ TachographVehicleSpeed : 48|16@1+ (0.0039062485409696,0) [0|250.996] "km/h" Vector__XXX

CM_ SG_ 3221225472 AuxI_O62 "Identifies the current status of auxiliary input/output functions that are configured uniquely per application.";
CM_ SG_ 3221225472 AuxI_O63 "Identifies the current status of auxiliary input/output functions that are configured uniquely per application.";
CM_ SG_ 3221225472 AuxI_O64 "Identifies the current status of auxiliary input/output functions that are configured uniquely per application.";
CM_ SG_ 3221225472 AuxI_O57 "Identifies the current status of auxiliary input/output functions that are configured uniquely per application.";
CM_ SG_ 3221225472 AuxI_O58 "Identifies the current status of auxiliary input/output functions that are configured uniquely per application.";
CM_ SG_ 3221225472 AuxI_O59 "Identifies the current status of auxiliary input/output functions that are configured uniquely per application.";
CM_ SG_ 3221225472 AuxI_O60 "Identifies the current status of auxiliary input/output functions that are configured uniquely per application.";
CM_ SG_ 3221225472 AuxI_O53 "Identifies the current status of auxiliary input/output functions that are configured uniquely per application.";
CM_ SG_ 3221225472 AuxI_O54 "Identifies the current status of auxiliary input/output functions that are configured uniquely per application.";
CM_ SG_ 3221225472 AuxI_O55 "Identifies the current status of auxiliary input/output functions that are configured uniquely per application.";
CM_ SG_ 3221225472 AuxI_O56 "Identifies the current status of auxiliary input/output functions that are configured uniquely per application.";
CM_ SG_ 3221225472 AuxI_O49 "Identifies the current status of auxiliary input/output functions that are configured uniquely per application.";
CM_ SG_ 3221225472 AuxI_O50 "Identifies the current status of auxiliary input/output functions that are configured uniquely per application.";
CM_ SG_ 3221225472 AuxI_O51 "Identifies the current status of auxiliary input/output functions that are configured uniquely per application.";
CM_ SG_ 3221225472 AuxI_O52 "Identifies the current status of auxiliary input/output functions that are configured uniquely per application.";
CM_ SG_ 3221225472 AuxI_O109 "Identifies the current status of auxiliary input/output functions that are configured uniquely per application.";
CM_ SG_ 3221225472 AuxI_O110 "Identifies the current status of auxiliary input/output functions that are configured uniquely per application.";
CM_ SG_ 3221225472 AuxI_O111 "Identifies the current status of auxiliary input/output functions that are configured uniquely per application.";
CM_ SG_ 3221225472 AuxI_O112 "Identifies the current status of auxiliary input/output functions that are configured uniquely per application.";
CM_ SG_ 3221225472 AuxI_O105 "Identifies the current status of auxiliary input/output functions that are configured uniquely per application.";
CM_ SG_ 3221225472 AuxI_O106 "Identifies the current status of auxiliary input/output functions that are configured uniquely per application.";
CM_ SG_ 3221225472 AuxI_O107 "Identifies the current status of auxiliary input/output functions that are configured uniquely per application.";
CM_ SG_ 3221225472 AuxI_O108 "Identifies the current status of auxiliary input/output functions that are configured uniquely per application.";
CM_ SG_ 3221225472 AuxI_O101 "Identifies the current status of auxiliary input/output functions that are configured uniquely per application.";
CM_ SG_ 3221225472 AuxI_O102 "Identifies the current status of auxiliary input/output functions that are configured uniquely per application.";
CM_ SG_ 3221225472 AuxI_O103 "Identifies the current status of auxiliary input/output functions that are configured uniquely per application.";
CM_ SG_ 3221225472 AuxI_O104 "Identifies the current status of auxiliary input/output functions that are configured uniquely per application.";
CM_ SG_ 3221225472 AuxI_O97 "Identifies the current status of auxiliary input/output functions that are configured uniquely per application.";
CM_ SG_ 3221225472 AuxI_O98 "Identifies the current status of auxiliary input/output functions that are configured uniquely per application.";
CM_ SG_ 3221225472 AuxI_O99 "Identifies the current status of auxiliary input/output functions that are configured uniquely per application.";
CM_ SG_ 3221225472 AuxI_O100 "Identifies the current status of auxiliary input/output functions that are configured uniquely per application.";
CM_ SG_ 3221225472 AuxI_O93 "Identifies the current status of auxiliary input/output functions that are configured uniquely per application.";
CM_ SG_ 3221225472 AuxI_O94 "Identifies the current status of auxiliary input/output functions that are configured uniquely per application.";
CM_ SG_ 3221225472 AuxI_O95 "Identifies the current status of auxiliary input/output functions that are configured uniquely per application.";
CM_ SG_ 3221225472 AuxI_O96 "Identifies the current status of auxiliary input/output functions that are configured uniquely per application.";
CM_ SG_ 3221225472 AuxI_O89 "Identifies the current status of auxiliary input/output functions that are configured uniquely per application.";
CM_ SG_ 3221225472 AuxI_O90 "Identifies the current status of auxiliary input/output functions that are configured uniquely per application.";
CM_ SG_ 3221225472 AuxI_O91 "Identifies the current status of auxiliary input/output functions that are configured uniquely per application.";
CM_ SG_ 3221225472 AuxI_O92 "Identifies the current status of auxiliary input/output functions that are configured uniquely per application.";
CM_ SG_ 3221225472 AuxI_O85 "Identifies the current status of auxiliary input/output functions that are configured uniquely per application.";
CM_ SG_ 3221225472 AuxI_O86 "Identifies the current status of auxiliary input/output functions that are configured uniquely per application.";
CM_ SG_ 3221225472 AuxI_O87 "Identifies the current status of auxiliary input/output functions that are configured uniquely per application.";
CM_ SG_ 3221225472 AuxI_O88 "Identifies the current status of auxiliary input/output functions that are configured uniquely per application.";
CM_ SG_ 3221225472 AuxI_O81 "Identifies the current status of auxiliary input/output functions that are configured uniquely per application.";
CM_ SG_ 3221225472 AuxI_O82 "Identifies the current status of auxiliary input/output functions that are configured uniquely per application.";
CM_ SG_ 3221225472 AuxI_O83 "Identifies the current status of auxiliary input/output functions that are configured uniquely per application.";
CM_ SG_ 3221225472 AuxI_O84 "Identifies the current status of auxiliary input/output functions that are configured uniquely per application.";
CM_ SG_ 3221225472 TrailerBrakeStrokeAxle5Right "Brake stroke status for right brake actuator on trailer axle 5.";
CM_ SG_ 3221225472 TrailerBrakeStrokeAxle5Left "Brake stroke status for left brake actuator on trailer axle 5.";
CM_ SG_ 3221225472 TrailerBrakeStrokeAxle4Right "Brake stroke status for right brake actuator on trailer axle 4.";
CM_ SG_ 3221225472 TrailerBrakeStrokeAxle4Left "Brake stroke status for left brake actuator on trailer axle 4.";
CM_ SG_ 3221225472 TrailerBrakeStrokeAxle3Right "Brake stroke status for right brake actuator on trailer axle 3.";
CM_ SG_ 3221225472 TrailerBrakeStrokeAxle3Left "Brake stroke status for left brake actuator on trailer axle 3.";
CM_ SG_ 3221225472 TrailerBrakeStrokeAxle2Right "Brake stroke status for right brake actuator on trailer axle 2.";
CM_ SG_ 3221225472 TrailerBrakeStrokeAxle2Left "Brake stroke status for left brake actuator on trailer axle 2.";
CM_ SG_ 3221225472 TrailerBrakeStrokeAxle1Right "Brake stroke status for right brake actuator on trailer axle 1.";
CM_ SG_ 3221225472 TrailerBrakeStrokeAxle1Left "Brake stroke status for left brake actuator on trailerr axle 1.";
CM_ SG_ 3221225472 TractorBrakeStrokeAxle5Right "Brake stroke status for right brake actuator on tractor axle 5.";
CM_ SG_ 3221225472 TractorBrakeStrokeAxle5Left "Brake stroke status for left brake actuator on tractor axle 5.";
CM_ SG_ 3221225472 TractorBrakeStrokeAxle4Right "Brake stroke status for right brake actuator on tractor axle 4.";
CM_ SG_ 3221225472 TractorBrakeStrokeAxle4Left "Brake stroke status for left brake actuator on tractor axle 4.";
CM_ SG_ 3221225472 TractorBrakeStrokeAxle3Right "Brake stroke status for right brake actuator on tractor axle 3.";
CM_ SG_ 3221225472 TractorBrakeStrokeAxle3Left "Brake stroke status for left brake actuator on tractor axle 3.";
CM_ SG_ 3221225472 TractorBrakeStrokeAxle2Right "Brake stroke status for right brake actuator on tractor axle 2.";
CM_ SG_ 3221225472 TractorBrakeStrokeAxle2Left "Brake stroke status for left brake actuator on tractor axle 2.";
CM_ SG_ 3221225472 TractorBrakeStrokeAxle1Right "Brake stroke status for right brake actuator on tractor axle 1.";
CM_ SG_ 3221225472 TractorBrakeStrokeAxle1Left "Brake stroke status for left brake actuator on tractor axle 1.";
CM_ SG_ 3221225472 RoadSurfaceTemp "Indicated temperature of road surface over which vehicle is operating.";
CM_ SG_ 3221225472 EngAirIntakeTemp "Temperature of air entering vehicle air induction system.";
CM_ SG_ 3221225472 AmbientAirTemp "Temperature of air surrounding vehicle.";
CM_ SG_ 3221225472 CabInteriorTemp "Temperature of air inside the part of the vehicle that encloses the driver and vehicle operating controls.";
CM_ SG_ 3221225472 BarometricPress "Absolute air pressure of the atmosphere. See Figures SPN16_A & SPN16_B.";
CM_ SG_ 3221225472 EngAirStartPress "Gage pressure of air in an engine starting system that utilizes compressed air to provide the force required to rotate the";
CM_ SG_ 3221225472 AirCompressorStatus "Indicates whether the air compressor is actively compressing air.";
CM_ SG_ 3221225472 AirSuspensionSupplyPress "The pneumatic pressure in the circuit for the electronically controlled air suspension system.";
CM_ SG_ 3221225472 AuxEquipmentSupplyPress "The pneumatic pressure in the auxiliary circuit.";
CM_ SG_ 3221225472 ServiceBrakeCircuit2AirPress "The pneumatic pressure in the secondary service brake circuit or reservoir, supplying the front axle.";
CM_ SG_ 3221225472 ServiceBrakeCircuit1AirPress "The pneumatic pressure in the primary service brake circuit or reservoir, supplying the rear axle.";
CM_ SG_ 3221225472 ParkingAnd_orTrailerAirPress "The pneumatic pressure in the circuit or reservoir for the parking brake and/or the trailer supply.";
CM_ SG_ 3221225472 PneumaticSupplyPress "The pneumatic pressure in the main reservoir, sometimes referred to as the wet tank.";
CM_ SG_ 3221225472 SteerAxleLubePress "The steering axle lubricant pressure.";
CM_ SG_ 3221225472 SteerAxleTemp "Temperature of lubricant in steering axle.";
CM_ SG_ 3221225472 DriveAxleLubePress "The drive axle lubricant pressure with location determined by Drive Axle Location (SPN 930).";
CM_ SG_ 3221225472 DriveAxleTemp "Temperature of axle lubricant in drive axle.";
CM_ SG_ 3221225472 DriveAxleLiftAirPress "Gage pressure of air in system that utilizes compressed air to provide force between axle and frame.";
CM_ SG_ 3221225472 DriveAxleLocation "To identify to which of several similar devices (such as tires or fuel tanks) the information applies.";
CM_ SG_ 3221225472 EngGsMssFlwSnsrFuelingCorrection "The amount of fuel the Gas Mass Flow Sensor is sensing should be added or subtracted compared to the maximum";
CM_ SG_ 3221225472 EngTurboWastegateValvePos "The position of the turbocharger wastegate valve (not the electronic wastegate control valve).";
CM_ SG_ 3221225472 EngDesiredAbsIntakeManifoldPress "The desired absolute intake manifold pressure of the engine.";
CM_ SG_ 3221225472 EngGasFuelCorrectionFactor "A correction to a predefined gaseous fuel energy (expressed in energy per unit volume) represented as a percentage.";
CM_ SG_ 3221225472 RequestedACCDistanceMode "The Requested Distance Control Mode to the ACC system from the operators interface.";
CM_ SG_ 3221225472 ACCUsageDemand "This parameter indicates the drivers demand to activate or deactivate ACC keeping distance control.";
CM_ SG_ 3221225472 ForwardCollisionWarning "This parameter indicates if a collision is imminent and strong driver reaction either by braking hard or by an avoidance";
CM_ SG_ 3221225472 ACCDistanceAlertSignal "Signal to indicate to the operator that the ACC system is not able to maintain the distance to the target. Example: Target";
CM_ SG_ 3221225472 ACCSystemShutoffWarning "Signal to warn the driver of system deactivation due to non-driver actions. Example: Attempting to control vehicle speed";
CM_ SG_ 3221225472 ACCTargetDetected "Signal to indicate to the driver that the ACC system has detected a target.";
CM_ SG_ 3221225472 AdptiveCruiseCtrlSetDistanceMode "Selected distance mode for adaptive cruise control.";
CM_ SG_ 3221225472 AdaptiveCruiseCtrlMode "This parameter is used to indicate the current state, or mode, of operation by the Adaptive Cruise Control (ACC) device.";
CM_ SG_ 3221225472 AdaptiveCruiseCtrlSetSpeed "Value of the desired (chosen) velocity of the adaptive cruise control system.";
CM_ SG_ 3221225472 DistanceToForwardVehicle "Distance to the preceding vehicle situated within 250 m in the same lane and moving in the same direction.";
CM_ SG_ 3221225472 SpeedOfForwardVehicle "Absolute velocity of the preceding vehicle situated within 250 m in the same lane and moving in the same direction.";
CM_ SG_ 3221225472 ArticulationAngle "Angle of deflection of an articulated transit vehicle. A right turn is indicated with a positive angle and a left turn is";
CM_ SG_ 3221225472 RelativeHumidity "Measures humidity of combustion air prior to entry into turbocharger";
CM_ SG_ 3221225472 AuxLevel "Level measured by a sensor.";
CM_ SG_ 3221225472 AuxPress2 "Pressure measured by auxiliary pressure sensor #2. Not to be used in place of existing SPNs.";
CM_ SG_ 3221225472 AuxPress1 "Pressure measured by auxiliary pressure sensor #1. Not to be used in place of existing SPNs.";
CM_ SG_ 3221225472 AuxTemp2 "Temperature measured by auxiliary temperature sensor #2. Not to be used in place of existing SPNs.";
CM_ SG_ 3221225472 AuxTemp1 "Temperature measured by auxiliary temperature sensor #1. Not to be used in place of existing SPNs.";
CM_ SG_ 3221225472 EngBlowerBypassValvePos "Relative position of the blower bypass valve.";
CM_ SG_ 3221225472 EngGasSupplyPress "Gage pressure of gas supply to fuel metering device.";
CM_ SG_ 3221225472 GroupFunctionValue "Group Function of PGN being acknowledged. This field identifies for a device the specific group function of a PGN being acknowledged or declined.  This field is not used if the PGN being acknowledged or declined is not a group function PGN.";
CM_ SG_ 3221225472 Status2OfDoors "Composite indication of all bus door statuses. Enabled means the bus doors are able to be automatically opened or";
CM_ SG_ 3221225472 Ramp_WheelChairLiftPos "Signal which indicates the actual position of the ramp / wheel chair lift.";
CM_ SG_ 3221225472 PosOfDoors "Signal which indicates the actual position of the doors.";
CM_ SG_ 3221225472 FifthWheelRollWarningIndicator "Indicates to the vehicle operator that the roll moment has exceeded a preset limit.";
CM_ SG_ 3221225472 FifthWheelRollMoment "Fifth wheel roll moment force - If the moment is positive, the trailer is rolling clockwise relative to the normal vehicle";
CM_ SG_ 3221225472 FifthWheelDrawbarForce "Fifth wheel drawbar force, with the trailer held stationary a positive force is generated by the vehicle pulling forward.";
CM_ SG_ 3221225472 FifthWheelVerticalForce "The amount of load being applied to the fifth wheel by the trailer. Zero load is indicated without a trailer.";
CM_ SG_ 3221225472 FifthWheelSliderLockIndicator "Indicates to vehicle operator that the fifth wheel slider is in position and locked.";
CM_ SG_ 3221225472 FifthWheelSliderPos "Slider position measurement. Zero equals fully back position, that is, the farthest to the rear of the vehicle.";
CM_ SG_ 3221225472 FfthWhlLockCoupleStatusIndicator "Indicates results of coupling operation to the vehicle operator. For incomplete couples further information can be obtained";
CM_ SG_ 3221225472 FfthWhlLckReadyToCoupleIndicator "Indicates to the vehicle operator that the fifth wheel lock is open and ready to couple.";
CM_ SG_ 3221225472 FifthWheelErrorStatus "Fifth wheel error state which conveys information when coupling status is incomplete or bad.";
CM_ SG_ 3221225472 RollAndPitchMeasurementLatency "The estimated measurement latency of the measurement. NOTE: This is only the sensor latency and does not include";
CM_ SG_ 3221225472 PitchAndRollCompensated "Compensated mode for the pitch and roll measurements. Compensation is the use of multiple sensors together to";
CM_ SG_ 3221225472 PitchRateFigureOfMerit "Figure of merit for the pitch rate measurement.";
CM_ SG_ 3221225472 RollAngleFigureOfMerit "Figure of merit for roll angle measurement.";
CM_ SG_ 3221225472 PitchAngleFigureOfMerit "Figure of merit for pitch angle measurement.";
CM_ SG_ 3221225472 PitchRate "Pitch rate is the rate-of-change of the pitch angle over time, where the pitch angle vector is in the direction of travel of the";
CM_ SG_ 3221225472 RollAngle "The angle between the vehicle y-axis and the ground plane.";
CM_ SG_ 3221225472 PitchAngle "The angle between the vehicle x-axis and the ground plane.";
CM_ SG_ 3221225472 TransOilLevelMeasurementStatus "Indicates if conditions are acceptable to obtain a valid transmission oil level measurement as conveyed in SPN 124";
CM_ SG_ 3221225472 TransOilLevelCountdownTimer "Once all vehicle conditions (such as vehicle stopped, etc) are met, some transmissions may require a ‘settling time’ to";
CM_ SG_ 3221225472 TransOilLevelHigh_Low "Amount of current volume of transmission sump oil compared to recommended volume. Positive values indicate overfill.";
CM_ SG_ 3221225472 TransOilTemp "Temperature of the transmission lubricant.";
CM_ SG_ 3221225472 TransOilPress "Gage pressure of lubrication fluid in transmission, measured after pump.";
CM_ SG_ 3221225472 TransFilterDiffPress "Change in transmission fluid pressure, measured after the filter, due to accumulation of solid or semisolid material on or in";
CM_ SG_ 3221225472 TransOilLevel "Ratio of volume of transmission sump oil to recommended volume.";
CM_ SG_ 3221225472 ClutchPress "Gage pressure of oil within a wet clutch.";
CM_ SG_ 3221225472 ChargingSystemPotential "Electrical potential measured at the charging system output. The charging system may be any device charging the";
CM_ SG_ 3221225472 KeyswitchBatteryPotential "Battery potential measured at the input of the electronic control unit supplied through a keyswitch or similar switching";
CM_ SG_ 3221225472 BatteryPotential_PowerInput1 "This parameter measures the first source of battery potential as measured at the input of the ECM/actuator etc. coming";
CM_ SG_ 3221225472 WrelessCommunicationNetworkType2 "Type of Wireless Communication Network";
CM_ SG_ 3221225472 NetworkSignalStrength2 "Indicates the signal strength for the wireless communications network type.";
CM_ SG_ 3221225472 NetworkAntennaStatus2 "Indicates the status of the antenna for the wireless communications network type";
CM_ SG_ 3221225472 NetworkServiceStatus2 "Indicates the status of the Service for the wireless communications network type";
CM_ SG_ 3221225472 NetworkTransceiverStatus2 "Indicates the status of the transceiver for the wireless communications network type";
CM_ SG_ 3221225472 WrelessCommunicationNetworkType1 "Type of Wireless Communication Network";
CM_ SG_ 3221225472 NetworkSignalStrength1 "Indicates the signal strength for the wireless communications network type.";
CM_ SG_ 3221225472 NetworkAntennaStatus1 "Indicates the status of the antenna for the wireless communications network type";
CM_ SG_ 3221225472 NetworkServiceStatus1 "Indicates the status of the Service for the wireless communications network type";
CM_ SG_ 3221225472 NetworkTransceiverStatus1 "Indicates the status of the transceiver for the wireless communications network type";
CM_ SG_ 3221225472 VoltageRegulatorEnabled "State signal indicating the Voltage regulator enabled.";
CM_ SG_ 3221225472 VoltageRegulatorSoftStartState "State signal indicating the mode of the Voltage regulator soft start function.";
CM_ SG_ 3221225472 VltgRgltrUndrfrqncyCmpnstnEnbld "State signal indicating the operating mode for underfrequency compensation.";
CM_ SG_ 3221225472 VltgRglatorLoadCompensationMode "State signal indicating the voltage regulator load compensation mode.";
CM_ SG_ 3221225472 GeneratorExcitationFieldCurrent "Measured signal that represents the generator excitation field current.";
CM_ SG_ 3221225472 GeneratorExcitationFieldVoltage "Measured signal that represents the generator excitation field voltage.";
CM_ SG_ 3221225472 RunningLightCmd "Command to activate or de-activate the tractor or powered vehicle running lights. Usually only used for on road vehicles.";
CM_ SG_ 3221225472 AltBeamHeadLightCmd "Command to activate or de-activate the tractor alternate head lights (only low beam is available on alternate head lights).";
CM_ SG_ 3221225472 LowBeamHeadLightCmd "Command to activate or de-activate the tractor low beam head light lamps.";
CM_ SG_ 3221225472 HighBeamHeadLightCmd "Command to activate or de-activate the tractor high beam head light lamps.";
CM_ SG_ 3221225472 TractorFrontFogLightsCmd "Command to activate or de-activate tractor front fog lights.";
CM_ SG_ 3221225472 RotatingBeaconLightCmd "Command to activate or de-activate slow moving vehicle indicator lights on tractor and/or implements. Activation of the";
CM_ SG_ 3221225472 RightTurnSignalLightsCmd "Command to activate or de-activate right turn signal lights on the tractor and all connected implements";
CM_ SG_ 3221225472 LeftTurnSignalLightsCmd "Command to activate or de-activate left turn signal lights on the tractor and all connected implements";
CM_ SG_ 3221225472 BackUpLightAndAlarmHornCmd "Command to activate or de-activate the back up lights and/ or associated alarm if required";
CM_ SG_ 3221225472 CenterStopLightCmd "Command to activate or de-activate the tractor and implement center stop light";
CM_ SG_ 3221225472 RightStopLightCmd "Command to activate or de-activate the tractor and implement right stop light";
CM_ SG_ 3221225472 LeftStopLightCmd "Command to activate or de-activate the tractor and implement left stop lights";
CM_ SG_ 3221225472 ImplementClearanceLightCmd "Command to activate or de-activate the implement high mounted clearance and lights.";
CM_ SG_ 3221225472 TractorClearanceLightCmd "Command to activate or de-activate the tractor high mounted clearance and center ID lights";
CM_ SG_ 3221225472 ImplementMarkerLightCmd "Command to activate or de-activate implement front position lights, rear red tail lights, side amber running lights, license";
CM_ SG_ 3221225472 TractorMarkerLightCmd "Command to activate or de-activate tractor and implement front position lights, rear red tail lights, side amber running";
CM_ SG_ 3221225472 RearFogLightCmd "Command to activate or de-activate tractor or implement rear fog lights.";
CM_ SG_ 3221225472 TrctrUndrsdeMountedWorkLightsCmd "Command to activate or de-activate the tractor underside mounted work lights.";
CM_ SG_ 3221225472 TrctrRearLowMountedWorkLightsCmd "Command to activate or de-activate the tractor rear low mounted work lights.";
CM_ SG_ 3221225472 TrctrRarHighMountedWorkLightsCmd "Command to activate or de-activate the tractor rear high mounted work lights.";
CM_ SG_ 3221225472 TrctrSideLowMountedWorkLightsCmd "Command to activate or de-activate the tractor side low mounted work lights.";
CM_ SG_ 3221225472 TrctrSdeHighMountedWorkLightsCmd "Command to activate or de-activate the tractor side high mounted work lights.";
CM_ SG_ 3221225472 TrctrFrntLowMountedWorkLightsCmd "Command to activate or de-activate the tractor front low mounted work lights.";
CM_ SG_ 3221225472 TrctrFrntHghMountedWorkLightsCmd "Command to activate or de-activate the tractor front high mounted work lights.";
CM_ SG_ 3221225472 ImplementOEMOption2LightCmd "Command to activate or de-activate an implement OEM option 2 light. This is provided to meet special needs on";
CM_ SG_ 3221225472 ImplementOEMOption1LightCmd "Command to activate or de-activate an implement OEM option 1 light. This is provided to meet special needs on";
CM_ SG_ 3221225472 ImplementRightFacingWorkLightCmd "Command to activate or de-activate work lights mounted on an implement to illuminate beyond right end of the implement.";
CM_ SG_ 3221225472 ImplementLeftFacingWorkLightCmd "Command to activate or de-activate work lights mounted on an implement to illuminate beyond left end of the implement.";
CM_ SG_ 3221225472 LightingDataRqCmd "Command to provide a response of the light state";
CM_ SG_ 3221225472 ImplmentRightForwardWorkLightCmd "Command to activate or de-activate the forward facing work lights toward the right end of the implement.";
CM_ SG_ 3221225472 ImplementLeftForwardWorkLightCmd "Command to activate or de-activate the forward facing work lights toward the left end of the implement.";
CM_ SG_ 3221225472 ImplementRearWorkLightCmd "Command to activate or de-activate implement rear work lights. (This is also the same as Reversing Lights for truck";
CM_ SG_ 3221225472 ActualInnerWheelSteerAngle "Signal which indicates the actual inner wheel steering angle. See Figure SPN2927_A for explanation of positive and";
CM_ SG_ 3221225472 StatusOfSteerAxle "A signal which indicates different states of the steering axle";
CM_ SG_ 3221225472 SteerableLiftAxleLoweringInhibit "A signal which indicates if lowering of lifted axle is allowed or inhibited.";
CM_ SG_ 3221225472 SteerType "Indicates the different types of steering systems (ref. ECE Regulation 79 paragraph 2.5)";
CM_ SG_ 3221225472 TypeOfSteerForces "Type of Steering Forces (Ref. ECE Regulation 79 paragraph 2.5)";
CM_ SG_ 3221225472 TypeOfSteerTrans "Type of Steering Transmission (Ref. ECE Regulation 79 paragraph 2.6)";
CM_ SG_ 3221225472 ASREngCtrlActive "State signal which indicates that ASR engine control has been commanded to be active. Active means that ASR actually";
CM_ SG_ 3221225472 ASRBrakeCtrlActive "State signal which indicates that ASR brake control is active. Active means that ASR actually controls wheel brake";
CM_ SG_ 3221225472 AntiLockBrakingActive "State signal which indicates that the ABS is active. The signal is set active when wheel brake pressure actually starts to";
CM_ SG_ 3221225472 ABSOffroadSwitch "Switch signal which indicates the position of the ABS off-road switch.";
CM_ SG_ 3221225472 ASROffroadSwitch "Switch signal which indicates the position of the ASR off-road switch.";
CM_ SG_ 3221225472 ASRHillHolderSwitch "Switch signal which indicates the position of the ASR “hill holder” switch.";
CM_ SG_ 3221225472 TractionCtrlOverrideSwitch "Switch signal which indicates the position of the traction control override switch. The traction control override signal";
CM_ SG_ 3221225472 AccelInterlockSwitch "Switch signal used to disable the accelerator and remote accelerator inputs, causing the engine to return to idle.";
CM_ SG_ 3221225472 EngDerateSwitch "Switch signal used to activate the torque limiting feature of the engine. The specific nature of torque limiting should be";
CM_ SG_ 3221225472 EngAuxShutdownSwitch "Switch signal which requests that all engine fueling stop.";
CM_ SG_ 3221225472 RemoteAccelEnableSwitch "Switch signal which indicates that the remote accelerator has been enabled and controls the engine.";
CM_ SG_ 3221225472 EngRetarderSelection "The position of the operator controlled selector, expressed as a percentage and determined by the ratio of the current";
CM_ SG_ 3221225472 ABSFullyOperational "Signal which indicates whether an ABS system is fully operational or whether its functionality is reduced by a defect or by";
CM_ SG_ 3221225472 EBSRedWarningSignal "This parameter commands the EBS red optical warning signal";
CM_ SG_ 3221225472 ABS_EBSAmberWarningSignal "This parameter commands the ABS/EBS amber/yellow optical warning signal";
CM_ SG_ 3221225472 ATC_ASRInformationSignal "This parameter commands the ATC/ASR driver information signal, for example a dash lamp.";
CM_ SG_ 3221225472 SrcAddrssOfCntrllngDvcFrBrkeCtrl "The source address of the SAE J1939 device currently controlling the brake system. Its value may be the source address";
CM_ SG_ 3221225472 HaltBrakeSwitch "Switch signal which indicates the position of the halt brake switch.";
CM_ SG_ 3221225472 TrailerABSStatus "State signal which indicates that ABS in the trailer is actively controlling the brakes. A message is sent to the tractor from";
CM_ SG_ 3221225472 TrctrMntdTrailerABSWarningSignal "This parameter commands the tractor-mounted trailer ABS optical warning signal.";
CM_ SG_ 3221225472 RelativeSpeedFrontAxleLeftWheel "The speed of the front axle, left wheel relative to the front axle speed, SPN 904.";
CM_ SG_ 3221225472 RelativeSpeedFrontAxleRightWheel "The speed of the front axle, right wheel relative to the front axle speed, SPN 904.";
CM_ SG_ 3221225472 RelativeSpeedRearAxle1LeftWheel "The speed of the rear axle #1, left wheel relative to the front axle speed, SPN 904.";
CM_ SG_ 3221225472 RelativeSpeedRearAxle1RightWheel "The speed of the rear axle #1, right wheel relative to the front axle speed, SPN 904.";
CM_ SG_ 3221225472 RelativeSpeedRearAxle2LeftWheel "The speed of the rear axle #2, left wheel relative to the front axle speed, SPN 904.";
CM_ SG_ 3221225472 RelativeSpeedRearAxle2RightWheel "The speed of the rear axle #2, right wheel relative to the front axle speed, SPN 904.";
CM_ SG_ 3221225472 ImplementRearWorkLight "This parameter provides measured data from the implement rear work lamps.";
CM_ SG_ 3221225472 ImplementLeftForwardWorkLight "This parameter provides measured data from the forward facing work lights toward the left end of the implement.";
CM_ SG_ 3221225472 ImplementRightForwardWorkLight "This parameter provides measured data from the forward facing work lights toward the right end of the implement.";
CM_ SG_ 3221225472 ImplementLeftFacingWorkLight "This parameter provides measured data from the work lights mounted on an implement to illuminate beyond left end of";
CM_ SG_ 3221225472 ImplementRightFacingWorkLight "This parameter provides measured data from the work lights mounted on an implement to illuminate beyond right end of";
CM_ SG_ 3221225472 ImplementOEMOption1Light "This parameter provides measured data from the implement OEM option 1 light.";
CM_ SG_ 3221225472 ImplementOEMOption2Light "This parameter provides measured data from the implement OEM option 2 light.";
CM_ SG_ 3221225472 TrctorFrontHighMountedWorkLights "This parameter provides measured data from the tractor front high mounted work lights.";
CM_ SG_ 3221225472 TractorFrontLowMountedWorkLights "This parameter provides measured data from the tractor front low mounted work lights.";
CM_ SG_ 3221225472 TractorSideHighMountedWorkLights "This parameter provides measured data from the tractor side high mounted work lights.";
CM_ SG_ 3221225472 TractorSideLowMountedWorkLights "This parameter provides measured data from the tractor side low mounted work lights.";
CM_ SG_ 3221225472 TractorRearHighMountedWorkLights "This parameter provides measured data from the tractor rear high mounted work lights.";
CM_ SG_ 3221225472 TractorRearLowMountedWorkLights "This parameter provides measured data from the tractor rear low mounted work lights.";
CM_ SG_ 3221225472 TrctorUndersideMountedWorkLights "This parameter provides measured data from the tractor underside mounted work lights.";
CM_ SG_ 3221225472 RearFogLights "This parameter provides measured data from the tractor and/or implement rear fog lights.";
CM_ SG_ 3221225472 TractorMarkerLight "This parameter provides measured data from the tractor and attached implement marker lights, including front position";
CM_ SG_ 3221225472 ImplementMarkerLight "This parameter provides measured data from an attached implement marker lights, including front position lights, rear tail";
CM_ SG_ 3221225472 TractorClearanceLight "This parameter provides measured data from the tractor high mounted clearance and center ID lights.";
CM_ SG_ 3221225472 ImplementClearanceLight "This parameter provides measured data from an attached implement high mounted clearance lights.";
CM_ SG_ 3221225472 LeftStopLight "This parameter provides measured data from the tractor and attached implement left stop lights.";
CM_ SG_ 3221225472 RightStopLight "This parameter provides measured data from the tractor and attached implement right stop lights.";
CM_ SG_ 3221225472 CenterStopLight "This parameter provides measured data from the tractor and attached implement center stop lights.";
CM_ SG_ 3221225472 BackUpLightAndAlarmHorn "This parameter provides measured data from the back up lights and/ or associated alarm.";
CM_ SG_ 3221225472 RotatingBeaconLight "This parameter provides measured data from the beacon light on tractor or attached implements.";
CM_ SG_ 3221225472 TractorFrontFogLights "This parameter provides measured data from the tractor front fog lights.";
CM_ SG_ 3221225472 HighBeamHeadLightData "This parameter provides measured data from the tractor high beam head light lamps.";
CM_ SG_ 3221225472 LowBeamHeadLightData "This parameter provides measured data from the tractor low beam head light lamps.";
CM_ SG_ 3221225472 AltBeamHeadLightData "This parameter provides measured data from the tractor alternate beam head light lamps.";
CM_ SG_ 3221225472 RunningLight "This parameter provides measured data from the vehicle’s running lights.";
CM_ SG_ 3221225472 VehicleOverspeed "Indicates whether the vehicle is exceeding the legal speed limit set in the tachograph.";
CM_ SG_ 3221225472 VehicleMotion "Indicates whether motion of the vehicle is detected or not.";
CM_ SG_ 3221225472 TachographOutputShaftSpeed "Calculated speed of the transmission output shaft.";
CM_ SG_ 3221225472 DirectionIndicator "Indicates the direction of the vehicle.";
CM_ SG_ 3221225472 TachographPerformance "Indicates the tachograph performance; including electronic or mechanical analysis, instrument analysis, speed sensor";
CM_ SG_ 3221225472 HandlingInformation "Indicates that handling information is present. Information could include “no printer paper”, “no driver card”, etc.";
CM_ SG_ 3221225472 SystemEvent "Indicates that a tachograph event has occurred. This may include power supply interruption, interruption of the speed";
CM_ SG_ 3221225472 DriverCardDriver2 "Indicates the presence of a driver card";
CM_ SG_ 3221225472 Driver2TimeRelatedStates "Indicates if the driver approaches or exceeds working time limits (or other limits).";
CM_ SG_ 3221225472 DriverCardDriver1 "Indicates the presence of a driver card";
CM_ SG_ 3221225472 Driver1TimeRelatedStates "Indicates if the driver approaches or exceeds working time limits (or other limits).";
CM_ SG_ 3221225472 Driver2WorkingState "State of work of the driver.";
CM_ SG_ 3221225472 Driver1WorkingState "State of work of the driver.";
CM_ SG_ 3221225472 RearWasherFunction "State of operation selected by operator switch for the rear washer. The parameter, 'Front Operator Washer Switch’";
CM_ SG_ 3221225472 FrontOperatorWasherSwitch "State of operation selected by operator switch for the washer in front of the operator position. This parameter, 'Front";
CM_ SG_ 3221225472 FrontNonoperatorWasherSwitch "State of operation selected by operator switch for the front washer not in front of the operator position. The parameter,";
CM_ SG_ 3221225472 RearWiperDelayCtrl "Time between cycles of the rear wiper (i.e. from end of cycle 'n' to start of cycle 'n+1') as selected by the operator control";
CM_ SG_ 3221225472 FrontNonoperatorWiperDelayCtrl "Time between cycles of the front non-operator side wiper (i.e. from end of cycle 'n' to start of cycle 'n+1') as selected by";
CM_ SG_ 3221225472 FrontOperatorWiperDelayCtrl "Time between cycles of the front operator side wiper (i.e. from end of cycle 'n' to start of cycle 'n+1') as selected by the";
CM_ SG_ 3221225472 RearWiperSwitch "State of operation selected by operator switch for the rear wiper. The parameter, 'Front Operator Washer Switch' should";
CM_ SG_ 3221225472 FrontOperatorWiperSwitch "State of operation selected by operator switch for the Wiper in front of the operator position. This parameter, 'Front";
CM_ SG_ 3221225472 FrontNonoperatorWiperSwitch "State of operation selected by operator switch for the front wiper not in front of the operator position. The parameter,";
CM_ SG_ 3221225472 OprtorsDesiredDelayedLampOffTime "A 16 bit parameter to be associated with Delayed Off position (1000 binary) of the Main Light Switch. This parameter";
CM_ SG_ 3221225472 OperatorsDesiredBacklight "A 8 bit parameter to indicate the level of back lighting the operator has selected for displays. This is to be differentiated";
CM_ SG_ 3221225472 HighLowBeamSwitch "A 2 bit parameter to indicate the selected position of the operator's high/low beam select switch.";
CM_ SG_ 3221225472 HazardLightSwitch "A 2 bit parameter to indicate the selected position of the operator's hazard light switch.";
CM_ SG_ 3221225472 TurnSignalSwitch "A 4 bit parameter to indicate the selected position of the operator's turn signal switch.";
CM_ SG_ 3221225472 MainLightSwitch "A 4 bit parameter to indicate the selected position of the operator's main light switch.";
CM_ SG_ 3221225472 WorkLightSwitch "A 4 bit parameter to indicate the selected position of the operator's work light switch. In Ag applications the work lights are";
CM_ SG_ 3221225472 LaneDepartureImminentLeftSide "Indicates departure imminent on left side of lane.";
CM_ SG_ 3221225472 LaneDepartureImminentRightSide "Indicates departure imminent on right side of lane.";
CM_ SG_ 3221225472 LaneDepartureRight "Indicates that the middle of vehicle departs the lane on the right side. The parameter indicates that the vehicle is changing";
CM_ SG_ 3221225472 LaneDepartureLeft "Indicates that the middle of vehicle departs the lane on the left side. The parameter indicates that the vehicle is changing";
CM_ SG_ 3221225472 TransCurrentRange "Range currently being commanded by the transmission control system. Characters may include P, Rx, Rx-1...R2, R1, R,";
CM_ SG_ 3221225472 TransRequestedRange "Range selected by the operator. Characters may include P, Rx, Rx-1...R2, R1, R, Nx, Nx-1...N2, N1, N, D, D1, D2..., Dx,";
CM_ SG_ 3221225472 TransCurrentGear "The gear currently engaged in the transmission or the last gear engaged while the transmission is in the process of";
CM_ SG_ 3221225472 TransActualGearRatio "Actual ratio of input shaft speed to output shaft speed.";
CM_ SG_ 3221225472 TransSelectedGear "The gear that the transmission will attempt to achieve during the current shift if a shift is in progress, or the next shift if one";
CM_ SG_ 3221225472 ActlMxAvlblRetarderPercentTorque "This is the maximum amount of torque that the retarder can immediately deliver. It is the same as the maximum torque";
CM_ SG_ 3221225472 RetarderSelectionNonengine "The “Retarder Selection, non-engine” is the position of the driver’s selector for retarders that are not part of the engine";
CM_ SG_ 3221225472 DrvrsDemandRetarderPercentTorque "The Drivers demand retarder – percent torque is the maximum torque selected by the driver when one or more modes";
CM_ SG_ 3221225472 SrcAddrssOfCntrllngDvcFrRtrdrCtr "The source address of the SAE J1939 device currently controlling the retarder. It is used to expand the torque mode";
CM_ SG_ 3221225472 RetarderRoadSpeedExceededStatus "Retarder Road Speed Exceeded Status:";
CM_ SG_ 3221225472 RetarderRoadSpeedLimitSwitch "Retarder road speed limit switch states:";
CM_ SG_ 3221225472 RetarderRequestingBrakeLight "Indicates that whether the retarder is requesting that the brake lights are illuminated.";
CM_ SG_ 3221225472 EngCoolantLoadIncrease "Status of an event, external to the engine, that may increase the nominal temperature of the engine coolant liquid.";
CM_ SG_ 3221225472 IntendedRetarderPercentTorque "Braking torque of retarder that the retarder is currently trying to achieve. This value takes into account all static";
CM_ SG_ 3221225472 ActualRetarderPercentTorque "Actual braking torque of the retarder as a percent of retarder configuration reference torque SPN 556.";
CM_ SG_ 3221225472 RetarderEnableShiftAssistSwitch "Switch signal which indicates whether the operator wishes the retarder to be enabled for transmission shift assist. The";
CM_ SG_ 3221225472 RetarderEnableBrakeAssistSwitch "Switch signal which indicates whether the operator wishes the retarder to be enabled for vehicle braking assist. The";
CM_ SG_ 3221225472 RetarderTorqueMode "State signal which indicates which retarder torque mode is currently generating, limiting, or controlling the torque. Note";
CM_ SG_ 3221225472 EstPumpingPercentTorque "The calculated torque that indicates the estimated amount of torque loss due to the engine air handling system. The value";
CM_ SG_ 3221225472 ActlMaxAvailableEngPercentTorque "This is the maximum amount of torque that the engine can immediately deliver as a percentage of the reference engine";
CM_ SG_ 3221225472 SCRThermalManagementActive "Indicates that the exhaust temperatures have been elevated for regeneration of the SCR aftertreatment system or in";
CM_ SG_ 3221225472 DPFThermalManagementActive "Indicates that the exhaust temperatures have been elevated for regeneration of the diesel particulate filter aftertreatment";
CM_ SG_ 3221225472 MmntaryEngMaxPowerEnableFeedback "Momentarily requesting Engine Maximum Power Enable - feature support feedback";
CM_ SG_ 3221225472 VhcleAccelerationRateLimitStatus "Status (active or not active) of the system used to limit maximum forward vehicle acceleration.";
CM_ SG_ 3221225472 AccelPedalPos2 "The ratio of actual position of the second analog engine speed/torque request input device (such as an accelerator pedal";
CM_ SG_ 3221225472 RemoteAccelPedalPos "The ratio of actual position of the remote analog engine speed/torque request input device (such as an accelerator pedal";
CM_ SG_ 3221225472 AccelPedal2LowIdleSwitch "Switch signal which indicates the state of the accelerator pedal 2 low idle switch. The low idle switch is defined in SAE";
CM_ SG_ 3221225472 RoadSpeedLimitStatus "Status (active or not active) of the system used to limit maximum vehicle velocity.";
CM_ SG_ 3221225472 AccelPedalKickdownSwitch "Switch signal which indicates whether the accelerator pedal kickdown switch is opened or closed. The kickdown switch is";
CM_ SG_ 3221225472 AccelPedal1LowIdleSwitch "Switch signal which indicates the state of the accelerator pedal 1 low idle switch. The low idle switch is defined in SAE";
CM_ SG_ 3221225472 EngShutdownOverrideSwitch "Switch signal which indicates the position of the engine shutdown override switch. This switch function allows the";
CM_ SG_ 3221225472 EngTestModeSwitch "Switch signal which indicates the position of the engine test mode switch.";
CM_ SG_ 3221225472 EngIdleDecrementSwitch "Switch signal which indicates the position of the idle decrement switch.";
CM_ SG_ 3221225472 EngIdleIncrementSwitch "Switch signal which indicates the position of the idle increment switch.";
CM_ SG_ 3221225472 CruiseCtrlStates "This parameter is used to indicate the current state, or mode, of operation by the cruise control device. This is a status";
CM_ SG_ 3221225472 PTOGovernorState "This parameter is used to indicate the current state or mode of operation by the power takeoff (PTO) governor. In lieu of";
CM_ SG_ 3221225472 CruiseCtrlSetSpeed "Value of set (chosen) velocity of velocity control system.";
CM_ SG_ 3221225472 CruiseCtrlAccelerateSwitch "Switch signal of the cruise control activator which indicates that the activator is in the position “accelerate.”";
CM_ SG_ 3221225472 CruiseCtrlResumeSwitch "Switch signal of the cruise control activator which indicates that the activator is in the position “resume.”";
CM_ SG_ 3221225472 CruiseCtrlCoastSwitch "Switch signal of the cruise control activator which indicates that the activator is in the position “coast (decelerate).”";
CM_ SG_ 3221225472 CruiseCtrlSetSwitch "Switch signal of the cruise control activator which indicates that the activator is in the position “set.”";
CM_ SG_ 3221225472 ClutchSwitch "Switch signal which indicates that the clutch pedal is being pressed. It is necessary for a safe drivetrain behavior that the";
CM_ SG_ 3221225472 BrakeSwitch "Switch signal which indicates that the driver operated brake foot pedal is being pressed. This brake foot pedal is";
CM_ SG_ 3221225472 CruiseCtrlEnableSwitch "Switch signal which indicates that it is possible to manage the cruise control function.";
CM_ SG_ 3221225472 CruiseCtrlActive "Cruise control is switched on. It is not ensured that the engine is controlled by cruise control, as in the case of a large";
CM_ SG_ 3221225472 ParkBrakeReleaseInhibitRq "Park Brake Release Inhibit Request signals the desire that an applied park brake remain applied and limit the ability of the";
CM_ SG_ 3221225472 CruiseCtrlPauseSwitch "Switch signal which indicates the position of the Cruise Control Pause Switch used on Remote Cruise Control";
CM_ SG_ 3221225472 ParkingBrakeSwitch "Switch signal which indicates when the parking brake is set. In general the switch actuated by the operator's park brake";
CM_ SG_ 3221225472 TwoSpeedAxleSwitch "Switch signal which indicates the current axle range.";
CM_ BO_ 2566799614 "This lighting message is a response to the request for lighting data in the lighting command message. Each lighting";
CM_ SG_ 2566799614 LeftTurnSignalLights "This parameter provides measured data from the tractor and attached implement left turn signal lights.";
CM_ SG_ 2566799614 RightTurnSignalLights "This parameter provides measured data from the tractor and attached implement right turn signal lights.";
CM_ SG_ 2565865739 BrakePedalPos "Ratio of brake pedal position to maximum pedal position. Used for electric brake applications. 0% means no braking.";
CM_ SG_ 2565865739 EBSBrakeSwitch "Switch signal which indicates that the brake pedal is being pressed. The EBS brake switch is independent of the brake";
CM_ SG_ 2364539687 AccelPedalPos1 "The ratio of actual position of the analog engine speed/torque request input device (such as an accelerator pedal or";
CM_ SG_ 2298375691 RearAxleRightWheelSpeed "High resolution measurement of the speed of the right wheel on the rear axle.";
CM_ SG_ 2298375691 RearAxleLeftWheelSpeed "High resolution measurement of the speed of the left wheel on the rear axle.";
CM_ SG_ 2298375691 FrontAxleRightWheelSpeed "High resolution measurement of the speed of the right wheel on the front axle.";
CM_ SG_ 2298375691 FrontAxleLeftWheelSpeed "High resolution measurement of the speed of the left wheel on the front axle.";
CM_ SG_ 2566831883 FrontAxleSpeed "The average speed of the two front wheels.";
CM_ BO_ 2565867787 "Contains information which relates to the vehicle's movement.";
CM_ SG_ 2565867787 LongitudinalAcceleration "Indicates the longitudinal acceleration of the vehicle. A positive longitudinal acceleration signal results when the vehicle";
CM_ SG_ 2565867787 LateralAcceleration "Indicates a lateral acceleration of the vehicle. A positive lateral acceleration signal results when the vehicle is accelerated";
CM_ SG_ 2565867787 YawRate "Indicates the rotation about the vertical axis. A positive yaw rate signal results when the vehicle turns counter-clockwise.";
CM_ SG_ 2565867787 SteerWheelAngleSensorType "Indicates whether the steering wheel angle sensor is capable of absolute measuring of the number of steering wheel";
CM_ SG_ 2565867787 SteerWheelTurnCounter "Indicates number of steering wheel turns, absolute position or relative position at ignition on. Positive values indicate left";
CM_ SG_ 2565867787 SteerWheelAngle "The main operator`s steering wheel angle (on the steering column, not the actual wheel angle). The vehicle being steered";
CM_ BO_ 2365484055 "Tachograph";
CM_ SG_ 2365484055 TachographVehicleSpeed "Speed of the vehicle registered by the tachograph.";
BA_DEF_ SG_  "SigType" ENUM  "Default","Range","RangeSigned","ASCII","Discrete","Control","ReferencePGN","DTC","StringDelimiter","StringLength","StringLengthControl";
BA_DEF_ SG_  "GenSigStartValue" INT 0 10000;
BA_DEF_ SG_  "GenSigSendType" ENUM  "Cyclic","OnWrite","reserved","OnChange","reserved","reserved","reserved","NoSigSendType";
BA_DEF_ SG_  "GenSigILSupport" ENUM  "Yes","No";
BA_DEF_ SG_  "GenSigEVName" STRING ;
BA_DEF_ SG_  "SPN" INT 0 524287;
BA_DEF_ SG_  "SAEDocument" STRING ;
BA_DEF_ BO_  "GenMsgILSupport" ENUM  "Yes","No";
BA_DEF_ BO_  "GenMsgRequestable" INT 0 1;
BA_DEF_ BO_  "GenMsgSendType" ENUM  "cyclic","reserved","cyclicIfActive","reserved","reserved","reserved","reserved","reserved","noMsgSendType";
BA_DEF_ BO_  "VFrameFormat" ENUM  "StandardCAN","ExtendedCAN","reserved","J1939PG";
BA_DEF_ BO_  "SingleFrame" INT 0 1;
BA_DEF_ BO_  "GenMsgCycleTime" INT 0 3600000;
BA_DEF_ BO_  "SAE_Document" STRING ;
BA_DEF_ SG_  "SystemSignalLongSymbol" STRING ;
BA_DEF_DEF_  "SigType" "Default";
BA_DEF_DEF_  "GenSigStartValue" 0;
BA_DEF_DEF_  "GenSigSendType" "NoSigSendType";
BA_DEF_DEF_  "GenSigILSupport" "Yes";
BA_DEF_DEF_  "GenSigEVName" "Env@Nodename_@Signame";
BA_DEF_DEF_  "SPN" 0;
BA_DEF_DEF_  "SAEDocument" "";
BA_DEF_DEF_  "GenMsgILSupport" "Yes";
BA_DEF_DEF_  "GenMsgRequestable" 1;
BA_DEF_DEF_  "GenMsgSendType" "noMsgSendType";
BA_DEF_DEF_  "VFrameFormat" "J1939PG";
BA_DEF_DEF_  "SingleFrame" 1;
BA_DEF_DEF_  "GenMsgCycleTime" 0;
BA_DEF_DEF_  "SAE_Document" "";
BA_DEF_DEF_  "SystemSignalLongSymbol" "";
BA_ "VFrameFormat" BO_ 2566799614 1;
BA_ "GenMsgSendType" BO_ 2566844926 0;
BA_ "VFrameFormat" BO_ 2566844926 1;
BA_ "GenMsgCycleTime" BO_ 2566844926 100;
BA_ "VFrameFormat" BO_ 2565865739 1;
BA_ "SAE_Document" BO_ 2566831883 "J1939-71";
BA_ "GenMsgCycleTime" BO_ 2566831883 100;
BA_ "GenMsgSendType" BO_ 2566831883 0;
BA_ "SAE_Document" BO_ 2565867787 "J1939-71";
BA_ "GenMsgCycleTime" BO_ 2565867787 10;
BA_ "GenMsgSendType" BO_ 2565867787 0;
BA_ "SAE_Document" BO_ 2365484055 "J1939-71";
BA_ "GenMsgCycleTime" BO_ 2365484055 50;
BA_ "GenMsgSendType" BO_ 2365484055 0;
BA_ "SAEDocument" SG_ 3221225472 AuxI_O62 "J1939-71";
BA_ "SPN" SG_ 3221225472 AuxI_O62 3885;
BA_ "SAEDocument" SG_ 3221225472 AuxI_O63 "J1939-71";
BA_ "SPN" SG_ 3221225472 AuxI_O63 3886;
BA_ "SAEDocument" SG_ 3221225472 AuxI_O64 "J1939-71";
BA_ "SPN" SG_ 3221225472 AuxI_O64 3887;
BA_ "SAEDocument" SG_ 3221225472 AuxI_O57 "J1939-71";
BA_ "SPN" SG_ 3221225472 AuxI_O57 3880;
BA_ "SAEDocument" SG_ 3221225472 AuxI_O58 "J1939-71";
BA_ "SPN" SG_ 3221225472 AuxI_O58 3881;
BA_ "SAEDocument" SG_ 3221225472 AuxI_O59 "J1939-71";
BA_ "SPN" SG_ 3221225472 AuxI_O59 3882;
BA_ "SAEDocument" SG_ 3221225472 AuxI_O60 "J1939-71";
BA_ "SPN" SG_ 3221225472 AuxI_O60 3883;
BA_ "SAEDocument" SG_ 3221225472 AuxI_O53 "J1939-71";
BA_ "SPN" SG_ 3221225472 AuxI_O53 3876;
BA_ "SAEDocument" SG_ 3221225472 AuxI_O54 "J1939-71";
BA_ "SPN" SG_ 3221225472 AuxI_O54 3877;
BA_ "SAEDocument" SG_ 3221225472 AuxI_O55 "J1939-71";
BA_ "SPN" SG_ 3221225472 AuxI_O55 3878;
BA_ "SAEDocument" SG_ 3221225472 AuxI_O56 "J1939-71";
BA_ "SPN" SG_ 3221225472 AuxI_O56 3879;
BA_ "SAEDocument" SG_ 3221225472 AuxI_O49 "J1939-71";
BA_ "SPN" SG_ 3221225472 AuxI_O49 3872;
BA_ "SAEDocument" SG_ 3221225472 AuxI_O50 "J1939-71";
BA_ "SPN" SG_ 3221225472 AuxI_O50 3873;
BA_ "SAEDocument" SG_ 3221225472 AuxI_O51 "J1939-71";
BA_ "SPN" SG_ 3221225472 AuxI_O51 3874;
BA_ "SAEDocument" SG_ 3221225472 AuxI_O52 "J1939-71";
BA_ "SPN" SG_ 3221225472 AuxI_O52 3875;
BA_ "SAEDocument" SG_ 3221225472 AuxI_O109 "J1939-71";
BA_ "SPN" SG_ 3221225472 AuxI_O109 3932;
BA_ "SAEDocument" SG_ 3221225472 AuxI_O110 "J1939-71";
BA_ "SPN" SG_ 3221225472 AuxI_O110 3933;
BA_ "SAEDocument" SG_ 3221225472 AuxI_O111 "J1939-71";
BA_ "SPN" SG_ 3221225472 AuxI_O111 3934;
BA_ "SAEDocument" SG_ 3221225472 AuxI_O112 "J1939-71";
BA_ "SPN" SG_ 3221225472 AuxI_O112 3935;
BA_ "SAEDocument" SG_ 3221225472 AuxI_O105 "J1939-71";
BA_ "SPN" SG_ 3221225472 AuxI_O105 3928;
BA_ "SAEDocument" SG_ 3221225472 AuxI_O106 "J1939-71";
BA_ "SPN" SG_ 3221225472 AuxI_O106 3929;
BA_ "SAEDocument" SG_ 3221225472 AuxI_O107 "J1939-71";
BA_ "SPN" SG_ 3221225472 AuxI_O107 3930;
BA_ "SAEDocument" SG_ 3221225472 AuxI_O108 "J1939-71";
BA_ "SPN" SG_ 3221225472 AuxI_O108 3931;
BA_ "SAEDocument" SG_ 3221225472 AuxI_O101 "J1939-71";
BA_ "SPN" SG_ 3221225472 AuxI_O101 3924;
BA_ "SAEDocument" SG_ 3221225472 AuxI_O102 "J1939-71";
BA_ "SPN" SG_ 3221225472 AuxI_O102 3925;
BA_ "SAEDocument" SG_ 3221225472 AuxI_O103 "J1939-71";
BA_ "SPN" SG_ 3221225472 AuxI_O103 3926;
BA_ "SAEDocument" SG_ 3221225472 AuxI_O104 "J1939-71";
BA_ "SPN" SG_ 3221225472 AuxI_O104 3927;
BA_ "SAEDocument" SG_ 3221225472 AuxI_O97 "J1939-71";
BA_ "SPN" SG_ 3221225472 AuxI_O97 3920;
BA_ "SAEDocument" SG_ 3221225472 AuxI_O98 "J1939-71";
BA_ "SPN" SG_ 3221225472 AuxI_O98 3921;
BA_ "SAEDocument" SG_ 3221225472 AuxI_O99 "J1939-71";
BA_ "SPN" SG_ 3221225472 AuxI_O99 3922;
BA_ "SAEDocument" SG_ 3221225472 AuxI_O100 "J1939-71";
BA_ "SPN" SG_ 3221225472 AuxI_O100 3923;
BA_ "SAEDocument" SG_ 3221225472 AuxI_O93 "J1939-71";
BA_ "SPN" SG_ 3221225472 AuxI_O93 3916;
BA_ "SAEDocument" SG_ 3221225472 AuxI_O94 "J1939-71";
BA_ "SPN" SG_ 3221225472 AuxI_O94 3917;
BA_ "SAEDocument" SG_ 3221225472 AuxI_O95 "J1939-71";
BA_ "SPN" SG_ 3221225472 AuxI_O95 3918;
BA_ "SAEDocument" SG_ 3221225472 AuxI_O96 "J1939-71";
BA_ "SPN" SG_ 3221225472 AuxI_O96 3919;
BA_ "SAEDocument" SG_ 3221225472 AuxI_O89 "J1939-71";
BA_ "SPN" SG_ 3221225472 AuxI_O89 3912;
BA_ "SAEDocument" SG_ 3221225472 AuxI_O90 "J1939-71";
BA_ "SPN" SG_ 3221225472 AuxI_O90 3913;
BA_ "SAEDocument" SG_ 3221225472 AuxI_O91 "J1939-71";
BA_ "SPN" SG_ 3221225472 AuxI_O91 3914;
BA_ "SAEDocument" SG_ 3221225472 AuxI_O92 "J1939-71";
BA_ "SPN" SG_ 3221225472 AuxI_O92 3915;
BA_ "SAEDocument" SG_ 3221225472 AuxI_O85 "J1939-71";
BA_ "SPN" SG_ 3221225472 AuxI_O85 3908;
BA_ "SAEDocument" SG_ 3221225472 AuxI_O86 "J1939-71";
BA_ "SPN" SG_ 3221225472 AuxI_O86 3909;
BA_ "SAEDocument" SG_ 3221225472 AuxI_O87 "J1939-71";
BA_ "SPN" SG_ 3221225472 AuxI_O87 3910;
BA_ "SAEDocument" SG_ 3221225472 AuxI_O88 "J1939-71";
BA_ "SPN" SG_ 3221225472 AuxI_O88 3911;
BA_ "SAEDocument" SG_ 3221225472 AuxI_O81 "J1939-71";
BA_ "SPN" SG_ 3221225472 AuxI_O81 3904;
BA_ "SAEDocument" SG_ 3221225472 AuxI_O82 "J1939-71";
BA_ "SPN" SG_ 3221225472 AuxI_O82 3905;
BA_ "SAEDocument" SG_ 3221225472 AuxI_O83 "J1939-71";
BA_ "SPN" SG_ 3221225472 AuxI_O83 3906;
BA_ "SAEDocument" SG_ 3221225472 AuxI_O84 "J1939-71";
BA_ "SPN" SG_ 3221225472 AuxI_O84 3907;
BA_ "SAEDocument" SG_ 3221225472 TrailerBrakeStrokeAxle5Right "J1939-71";
BA_ "SPN" SG_ 3221225472 TrailerBrakeStrokeAxle5Right 3804;
BA_ "SAEDocument" SG_ 3221225472 TrailerBrakeStrokeAxle5Left "J1939-71";
BA_ "SPN" SG_ 3221225472 TrailerBrakeStrokeAxle5Left 3803;
BA_ "SAEDocument" SG_ 3221225472 TrailerBrakeStrokeAxle4Right "J1939-71";
BA_ "SPN" SG_ 3221225472 TrailerBrakeStrokeAxle4Right 3802;
BA_ "SAEDocument" SG_ 3221225472 TrailerBrakeStrokeAxle4Left "J1939-71";
BA_ "SPN" SG_ 3221225472 TrailerBrakeStrokeAxle4Left 3801;
BA_ "SAEDocument" SG_ 3221225472 TrailerBrakeStrokeAxle3Right "J1939-71";
BA_ "SPN" SG_ 3221225472 TrailerBrakeStrokeAxle3Right 3800;
BA_ "SAEDocument" SG_ 3221225472 TrailerBrakeStrokeAxle3Left "J1939-71";
BA_ "SPN" SG_ 3221225472 TrailerBrakeStrokeAxle3Left 3799;
BA_ "SAEDocument" SG_ 3221225472 TrailerBrakeStrokeAxle2Right "J1939-71";
BA_ "SPN" SG_ 3221225472 TrailerBrakeStrokeAxle2Right 3798;
BA_ "SAEDocument" SG_ 3221225472 TrailerBrakeStrokeAxle2Left "J1939-71";
BA_ "SPN" SG_ 3221225472 TrailerBrakeStrokeAxle2Left 3797;
BA_ "SAEDocument" SG_ 3221225472 TrailerBrakeStrokeAxle1Right "J1939-71";
BA_ "SPN" SG_ 3221225472 TrailerBrakeStrokeAxle1Right 3796;
BA_ "SAEDocument" SG_ 3221225472 TrailerBrakeStrokeAxle1Left "J1939-71";
BA_ "SPN" SG_ 3221225472 TrailerBrakeStrokeAxle1Left 3795;
BA_ "SAEDocument" SG_ 3221225472 TractorBrakeStrokeAxle5Right "J1939-71";
BA_ "SPN" SG_ 3221225472 TractorBrakeStrokeAxle5Right 3794;
BA_ "SAEDocument" SG_ 3221225472 TractorBrakeStrokeAxle5Left "J1939-71";
BA_ "SPN" SG_ 3221225472 TractorBrakeStrokeAxle5Left 3793;
BA_ "SAEDocument" SG_ 3221225472 TractorBrakeStrokeAxle4Right "J1939-71";
BA_ "SPN" SG_ 3221225472 TractorBrakeStrokeAxle4Right 3792;
BA_ "SAEDocument" SG_ 3221225472 TractorBrakeStrokeAxle4Left "J1939-71";
BA_ "SPN" SG_ 3221225472 TractorBrakeStrokeAxle4Left 3791;
BA_ "SAEDocument" SG_ 3221225472 TractorBrakeStrokeAxle3Right "J1939-71";
BA_ "SPN" SG_ 3221225472 TractorBrakeStrokeAxle3Right 3790;
BA_ "SAEDocument" SG_ 3221225472 TractorBrakeStrokeAxle3Left "J1939-71";
BA_ "SPN" SG_ 3221225472 TractorBrakeStrokeAxle3Left 3789;
BA_ "SAEDocument" SG_ 3221225472 TractorBrakeStrokeAxle2Right "J1939-71";
BA_ "SPN" SG_ 3221225472 TractorBrakeStrokeAxle2Right 3788;
BA_ "SAEDocument" SG_ 3221225472 TractorBrakeStrokeAxle2Left "J1939-71";
BA_ "SPN" SG_ 3221225472 TractorBrakeStrokeAxle2Left 3787;
BA_ "SAEDocument" SG_ 3221225472 TractorBrakeStrokeAxle1Right "J1939-71";
BA_ "SPN" SG_ 3221225472 TractorBrakeStrokeAxle1Right 3786;
BA_ "SAEDocument" SG_ 3221225472 TractorBrakeStrokeAxle1Left "J1939-71";
BA_ "SPN" SG_ 3221225472 TractorBrakeStrokeAxle1Left 3785;
BA_ "SAEDocument" SG_ 3221225472 RoadSurfaceTemp "J1939-71";
BA_ "SPN" SG_ 3221225472 RoadSurfaceTemp 79;
BA_ "SigType" SG_ 3221225472 RoadSurfaceTemp 1;
BA_ "SAEDocument" SG_ 3221225472 EngAirIntakeTemp "J1939-71";
BA_ "SPN" SG_ 3221225472 EngAirIntakeTemp 172;
BA_ "SigType" SG_ 3221225472 EngAirIntakeTemp 1;
BA_ "SAEDocument" SG_ 3221225472 AmbientAirTemp "J1939-71";
BA_ "SPN" SG_ 3221225472 AmbientAirTemp 171;
BA_ "SigType" SG_ 3221225472 AmbientAirTemp 1;
BA_ "SAEDocument" SG_ 3221225472 CabInteriorTemp "J1939-71";
BA_ "SPN" SG_ 3221225472 CabInteriorTemp 170;
BA_ "SigType" SG_ 3221225472 CabInteriorTemp 1;
BA_ "SAEDocument" SG_ 3221225472 BarometricPress "J1939-71";
BA_ "SPN" SG_ 3221225472 BarometricPress 108;
BA_ "SigType" SG_ 3221225472 BarometricPress 1;
BA_ "SAEDocument" SG_ 3221225472 EngAirStartPress "J1939-71";
BA_ "SPN" SG_ 3221225472 EngAirStartPress 82;
BA_ "SigType" SG_ 3221225472 EngAirStartPress 1;
BA_ "SAEDocument" SG_ 3221225472 AirCompressorStatus "J1939-71";
BA_ "SPN" SG_ 3221225472 AirCompressorStatus 1351;
BA_ "SigType" SG_ 3221225472 AirCompressorStatus 4;
BA_ "SAEDocument" SG_ 3221225472 AirSuspensionSupplyPress "J1939-71";
BA_ "SPN" SG_ 3221225472 AirSuspensionSupplyPress 1090;
BA_ "SigType" SG_ 3221225472 AirSuspensionSupplyPress 1;
BA_ "SAEDocument" SG_ 3221225472 AuxEquipmentSupplyPress "J1939-71";
BA_ "SPN" SG_ 3221225472 AuxEquipmentSupplyPress 1089;
BA_ "SigType" SG_ 3221225472 AuxEquipmentSupplyPress 1;
BA_ "SAEDocument" SG_ 3221225472 ServiceBrakeCircuit2AirPress "J1939-71";
BA_ "SPN" SG_ 3221225472 ServiceBrakeCircuit2AirPress 1088;
BA_ "SigType" SG_ 3221225472 ServiceBrakeCircuit2AirPress 1;
BA_ "SAEDocument" SG_ 3221225472 ServiceBrakeCircuit1AirPress "J1939-71";
BA_ "SPN" SG_ 3221225472 ServiceBrakeCircuit1AirPress 1087;
BA_ "SigType" SG_ 3221225472 ServiceBrakeCircuit1AirPress 1;
BA_ "SAEDocument" SG_ 3221225472 ParkingAnd_orTrailerAirPress "J1939-71";
BA_ "SPN" SG_ 3221225472 ParkingAnd_orTrailerAirPress 1086;
BA_ "SigType" SG_ 3221225472 ParkingAnd_orTrailerAirPress 1;
BA_ "SAEDocument" SG_ 3221225472 PneumaticSupplyPress "J1939-71";
BA_ "SPN" SG_ 3221225472 PneumaticSupplyPress 46;
BA_ "SigType" SG_ 3221225472 PneumaticSupplyPress 1;
BA_ "SAEDocument" SG_ 3221225472 SteerAxleLubePress "J1939-71";
BA_ "SPN" SG_ 3221225472 SteerAxleLubePress 2614;
BA_ "SigType" SG_ 3221225472 SteerAxleLubePress 1;
BA_ "SAEDocument" SG_ 3221225472 SteerAxleTemp "J1939-71";
BA_ "SPN" SG_ 3221225472 SteerAxleTemp 75;
BA_ "SigType" SG_ 3221225472 SteerAxleTemp 1;
BA_ "SAEDocument" SG_ 3221225472 DriveAxleLubePress "J1939-71";
BA_ "SPN" SG_ 3221225472 DriveAxleLubePress 2613;
BA_ "SigType" SG_ 3221225472 DriveAxleLubePress 1;
BA_ "SAEDocument" SG_ 3221225472 DriveAxleTemp "J1939-71";
BA_ "SPN" SG_ 3221225472 DriveAxleTemp 578;
BA_ "SigType" SG_ 3221225472 DriveAxleTemp 1;
BA_ "SAEDocument" SG_ 3221225472 DriveAxleLiftAirPress "J1939-71";
BA_ "SPN" SG_ 3221225472 DriveAxleLiftAirPress 579;
BA_ "SigType" SG_ 3221225472 DriveAxleLiftAirPress 1;
BA_ "SAEDocument" SG_ 3221225472 DriveAxleLocation "J1939-71";
BA_ "SPN" SG_ 3221225472 DriveAxleLocation 930;
BA_ "SigType" SG_ 3221225472 DriveAxleLocation 1;
BA_ "SAEDocument" SG_ 3221225472 EngGsMssFlwSnsrFuelingCorrection "J1939-71";
BA_ "SPN" SG_ 3221225472 EngGsMssFlwSnsrFuelingCorrection 1694;
BA_ "SigType" SG_ 3221225472 EngGsMssFlwSnsrFuelingCorrection 1;
BA_ "SAEDocument" SG_ 3221225472 EngTurboWastegateValvePos "J1939-71";
BA_ "SPN" SG_ 3221225472 EngTurboWastegateValvePos 1693;
BA_ "SigType" SG_ 3221225472 EngTurboWastegateValvePos 1;
BA_ "SAEDocument" SG_ 3221225472 EngDesiredAbsIntakeManifoldPress "J1939-71";
BA_ "SPN" SG_ 3221225472 EngDesiredAbsIntakeManifoldPress 1692;
BA_ "SAEDocument" SG_ 3221225472 EngGasFuelCorrectionFactor "J1939-71";
BA_ "SPN" SG_ 3221225472 EngGasFuelCorrectionFactor 1116;
BA_ "SigType" SG_ 3221225472 EngGasFuelCorrectionFactor 1;
BA_ "SAEDocument" SG_ 3221225472 RequestedACCDistanceMode "J1939-71";
BA_ "SPN" SG_ 3221225472 RequestedACCDistanceMode 1799;
BA_ "SAEDocument" SG_ 3221225472 ACCUsageDemand "J1939-71";
BA_ "SPN" SG_ 3221225472 ACCUsageDemand 5023;
BA_ "SigType" SG_ 3221225472 ACCUsageDemand 5;
BA_ "SAEDocument" SG_ 3221225472 ForwardCollisionWarning "J1939-71";
BA_ "SPN" SG_ 3221225472 ForwardCollisionWarning 5022;
BA_ "SigType" SG_ 3221225472 ForwardCollisionWarning 5;
BA_ "SAEDocument" SG_ 3221225472 ACCDistanceAlertSignal "J1939-71";
BA_ "SPN" SG_ 3221225472 ACCDistanceAlertSignal 1796;
BA_ "SigType" SG_ 3221225472 ACCDistanceAlertSignal 5;
BA_ "SAEDocument" SG_ 3221225472 ACCSystemShutoffWarning "J1939-71";
BA_ "SPN" SG_ 3221225472 ACCSystemShutoffWarning 1797;
BA_ "SigType" SG_ 3221225472 ACCSystemShutoffWarning 5;
BA_ "SAEDocument" SG_ 3221225472 ACCTargetDetected "J1939-71";
BA_ "SPN" SG_ 3221225472 ACCTargetDetected 1798;
BA_ "SigType" SG_ 3221225472 ACCTargetDetected 5;
BA_ "SAEDocument" SG_ 3221225472 AdptiveCruiseCtrlSetDistanceMode "J1939-71";
BA_ "SPN" SG_ 3221225472 AdptiveCruiseCtrlSetDistanceMode 1589;
BA_ "SAEDocument" SG_ 3221225472 AdaptiveCruiseCtrlMode "J1939-71";
BA_ "SPN" SG_ 3221225472 AdaptiveCruiseCtrlMode 1590;
BA_ "SAEDocument" SG_ 3221225472 AdaptiveCruiseCtrlSetSpeed "J1939-71";
BA_ "SPN" SG_ 3221225472 AdaptiveCruiseCtrlSetSpeed 1588;
BA_ "SAEDocument" SG_ 3221225472 DistanceToForwardVehicle "J1939-71";
BA_ "SPN" SG_ 3221225472 DistanceToForwardVehicle 1587;
BA_ "SigType" SG_ 3221225472 DistanceToForwardVehicle 1;
BA_ "SAEDocument" SG_ 3221225472 SpeedOfForwardVehicle "J1939-71";
BA_ "SPN" SG_ 3221225472 SpeedOfForwardVehicle 1586;
BA_ "SigType" SG_ 3221225472 SpeedOfForwardVehicle 1;
BA_ "SAEDocument" SG_ 3221225472 ArticulationAngle "J1939-71";
BA_ "SPN" SG_ 3221225472 ArticulationAngle 1120;
BA_ "SigType" SG_ 3221225472 ArticulationAngle 1;
BA_ "SAEDocument" SG_ 3221225472 RelativeHumidity "J1939-71";
BA_ "SPN" SG_ 3221225472 RelativeHumidity 354;
BA_ "SigType" SG_ 3221225472 RelativeHumidity 1;
BA_ "SAEDocument" SG_ 3221225472 AuxLevel "J1939-71";
BA_ "SPN" SG_ 3221225472 AuxLevel 3087;
BA_ "SigType" SG_ 3221225472 AuxLevel 1;
BA_ "SAEDocument" SG_ 3221225472 AuxPress2 "J1939-71";
BA_ "SPN" SG_ 3221225472 AuxPress2 1388;
BA_ "SigType" SG_ 3221225472 AuxPress2 1;
BA_ "SAEDocument" SG_ 3221225472 AuxPress1 "J1939-71";
BA_ "SPN" SG_ 3221225472 AuxPress1 1387;
BA_ "SigType" SG_ 3221225472 AuxPress1 1;
BA_ "SAEDocument" SG_ 3221225472 AuxTemp2 "J1939-71";
BA_ "SPN" SG_ 3221225472 AuxTemp2 442;
BA_ "SigType" SG_ 3221225472 AuxTemp2 1;
BA_ "SAEDocument" SG_ 3221225472 AuxTemp1 "J1939-71";
BA_ "SPN" SG_ 3221225472 AuxTemp1 441;
BA_ "SigType" SG_ 3221225472 AuxTemp1 1;
BA_ "SAEDocument" SG_ 3221225472 EngBlowerBypassValvePos "J1939-71";
BA_ "SPN" SG_ 3221225472 EngBlowerBypassValvePos 72;
BA_ "SigType" SG_ 3221225472 EngBlowerBypassValvePos 1;
BA_ "SAEDocument" SG_ 3221225472 EngGasSupplyPress "J1939-71";
BA_ "SPN" SG_ 3221225472 EngGasSupplyPress 159;
BA_ "SigType" SG_ 3221225472 EngGasSupplyPress 1;
BA_ "SAEDocument" SG_ 3221225472 AddressBusy "J1939-21";
BA_ "SAEDocument" SG_ 3221225472 GroupFunctionValue "NMEA2000";
BA_ "SPN" SG_ 3221225472 GroupFunctionValue 2542;
BA_ "SigType" SG_ 3221225472 GroupFunctionValue 1;
BA_ "SAEDocument" SG_ 3221225472 AddressAccessDenied "J1939-21";
BA_ "SAEDocument" SG_ 3221225472 AddressNegativeAcknowledgement "J1939-21";
BA_ "SAEDocument" SG_ 3221225472 AddressAcknowledged "J1939-21";
BA_ "SAEDocument" SG_ 3221225472 Status2OfDoors "J1939-71";
BA_ "SPN" SG_ 3221225472 Status2OfDoors 3411;
BA_ "SigType" SG_ 3221225472 Status2OfDoors 4;
BA_ "SAEDocument" SG_ 3221225472 Ramp_WheelChairLiftPos "J1939-71";
BA_ "SPN" SG_ 3221225472 Ramp_WheelChairLiftPos 1820;
BA_ "SigType" SG_ 3221225472 Ramp_WheelChairLiftPos 4;
BA_ "SAEDocument" SG_ 3221225472 PosOfDoors "J1939-71";
BA_ "SPN" SG_ 3221225472 PosOfDoors 1821;
BA_ "SAEDocument" SG_ 3221225472 FifthWheelRollWarningIndicator "J1939-71";
BA_ "SPN" SG_ 3221225472 FifthWheelRollWarningIndicator 3317;
BA_ "SigType" SG_ 3221225472 FifthWheelRollWarningIndicator 5;
BA_ "SAEDocument" SG_ 3221225472 FifthWheelRollMoment "J1939-71";
BA_ "SPN" SG_ 3221225472 FifthWheelRollMoment 3310;
BA_ "SigType" SG_ 3221225472 FifthWheelRollMoment 1;
BA_ "SAEDocument" SG_ 3221225472 FifthWheelDrawbarForce "J1939-71";
BA_ "SPN" SG_ 3221225472 FifthWheelDrawbarForce 3309;
BA_ "SigType" SG_ 3221225472 FifthWheelDrawbarForce 1;
BA_ "SAEDocument" SG_ 3221225472 FifthWheelVerticalForce "J1939-71";
BA_ "SPN" SG_ 3221225472 FifthWheelVerticalForce 3308;
BA_ "SigType" SG_ 3221225472 FifthWheelVerticalForce 1;
BA_ "SAEDocument" SG_ 3221225472 FifthWheelSliderLockIndicator "J1939-71";
BA_ "SPN" SG_ 3221225472 FifthWheelSliderLockIndicator 3316;
BA_ "SigType" SG_ 3221225472 FifthWheelSliderLockIndicator 4;
BA_ "SAEDocument" SG_ 3221225472 FifthWheelSliderPos "J1939-71";
BA_ "SPN" SG_ 3221225472 FifthWheelSliderPos 3311;
BA_ "SigType" SG_ 3221225472 FifthWheelSliderPos 1;
BA_ "SAEDocument" SG_ 3221225472 FfthWhlLockCoupleStatusIndicator "J1939-71";
BA_ "SPN" SG_ 3221225472 FfthWhlLockCoupleStatusIndicator 3313;
BA_ "SigType" SG_ 3221225472 FfthWhlLockCoupleStatusIndicator 5;
BA_ "SAEDocument" SG_ 3221225472 FfthWhlLckReadyToCoupleIndicator "J1939-71";
BA_ "SPN" SG_ 3221225472 FfthWhlLckReadyToCoupleIndicator 3312;
BA_ "SigType" SG_ 3221225472 FfthWhlLckReadyToCoupleIndicator 5;
BA_ "SAEDocument" SG_ 3221225472 FifthWheelErrorStatus "J1939-71";
BA_ "SPN" SG_ 3221225472 FifthWheelErrorStatus 3307;
BA_ "SAEDocument" SG_ 3221225472 RollAndPitchMeasurementLatency "J1939-71";
BA_ "SPN" SG_ 3221225472 RollAndPitchMeasurementLatency 3327;
BA_ "SigType" SG_ 3221225472 RollAndPitchMeasurementLatency 1;
BA_ "SAEDocument" SG_ 3221225472 PitchAndRollCompensated "J1939-71";
BA_ "SPN" SG_ 3221225472 PitchAndRollCompensated 3326;
BA_ "SigType" SG_ 3221225472 PitchAndRollCompensated 5;
BA_ "SAEDocument" SG_ 3221225472 PitchRateFigureOfMerit "J1939-71";
BA_ "SPN" SG_ 3221225472 PitchRateFigureOfMerit 3325;
BA_ "SigType" SG_ 3221225472 PitchRateFigureOfMerit 5;
BA_ "SAEDocument" SG_ 3221225472 RollAngleFigureOfMerit "J1939-71";
BA_ "SPN" SG_ 3221225472 RollAngleFigureOfMerit 3324;
BA_ "SigType" SG_ 3221225472 RollAngleFigureOfMerit 5;
BA_ "SAEDocument" SG_ 3221225472 PitchAngleFigureOfMerit "J1939-71";
BA_ "SPN" SG_ 3221225472 PitchAngleFigureOfMerit 3323;
BA_ "SigType" SG_ 3221225472 PitchAngleFigureOfMerit 5;
BA_ "SAEDocument" SG_ 3221225472 PitchRate "J1939-71";
BA_ "SPN" SG_ 3221225472 PitchRate 3322;
BA_ "SigType" SG_ 3221225472 PitchRate 1;
BA_ "SAEDocument" SG_ 3221225472 RollAngle "J1939-71";
BA_ "SPN" SG_ 3221225472 RollAngle 3319;
BA_ "SigType" SG_ 3221225472 RollAngle 1;
BA_ "SAEDocument" SG_ 3221225472 PitchAngle "J1939-71";
BA_ "SPN" SG_ 3221225472 PitchAngle 3318;
BA_ "SigType" SG_ 3221225472 PitchAngle 1;
BA_ "SAEDocument" SG_ 3221225472 TransOilLevelMeasurementStatus "J1939-71";
BA_ "SPN" SG_ 3221225472 TransOilLevelMeasurementStatus 3026;
BA_ "SAEDocument" SG_ 3221225472 TransOilLevelCountdownTimer "J1939-71";
BA_ "SPN" SG_ 3221225472 TransOilLevelCountdownTimer 3028;
BA_ "SAEDocument" SG_ 3221225472 TransOilLevelHigh_Low "J1939-71";
BA_ "SPN" SG_ 3221225472 TransOilLevelHigh_Low 3027;
BA_ "SigType" SG_ 3221225472 TransOilLevelHigh_Low 1;
BA_ "SAEDocument" SG_ 3221225472 TransOilTemp "J1939-71";
BA_ "SPN" SG_ 3221225472 TransOilTemp 177;
BA_ "SigType" SG_ 3221225472 TransOilTemp 1;
BA_ "SAEDocument" SG_ 3221225472 TransOilPress "J1939-71";
BA_ "SPN" SG_ 3221225472 TransOilPress 127;
BA_ "SigType" SG_ 3221225472 TransOilPress 1;
BA_ "SAEDocument" SG_ 3221225472 TransFilterDiffPress "J1939-71";
BA_ "SPN" SG_ 3221225472 TransFilterDiffPress 126;
BA_ "SigType" SG_ 3221225472 TransFilterDiffPress 1;
BA_ "SAEDocument" SG_ 3221225472 TransOilLevel "J1939-71";
BA_ "SPN" SG_ 3221225472 TransOilLevel 124;
BA_ "SigType" SG_ 3221225472 TransOilLevel 1;
BA_ "SAEDocument" SG_ 3221225472 ClutchPress "J1939-71";
BA_ "SPN" SG_ 3221225472 ClutchPress 123;
BA_ "SigType" SG_ 3221225472 ClutchPress 1;
BA_ "SAEDocument" SG_ 3221225472 ChargingSystemPotential "J1939-71";
BA_ "SPN" SG_ 3221225472 ChargingSystemPotential 167;
BA_ "SigType" SG_ 3221225472 ChargingSystemPotential 1;
BA_ "SAEDocument" SG_ 3221225472 KeyswitchBatteryPotential "J1939-71";
BA_ "SPN" SG_ 3221225472 KeyswitchBatteryPotential 158;
BA_ "SigType" SG_ 3221225472 KeyswitchBatteryPotential 1;
BA_ "SAEDocument" SG_ 3221225472 BatteryPotential_PowerInput1 "J1939-71";
BA_ "SPN" SG_ 3221225472 BatteryPotential_PowerInput1 168;
BA_ "SigType" SG_ 3221225472 BatteryPotential_PowerInput1 1;
BA_ "SAEDocument" SG_ 3221225472 WrelessCommunicationNetworkType2 "J1939-71";
BA_ "SPN" SG_ 3221225472 WrelessCommunicationNetworkType2 3446;
BA_ "SAEDocument" SG_ 3221225472 NetworkSignalStrength2 "J1939-71";
BA_ "SPN" SG_ 3221225472 NetworkSignalStrength2 3445;
BA_ "SAEDocument" SG_ 3221225472 NetworkAntennaStatus2 "J1939-71";
BA_ "SPN" SG_ 3221225472 NetworkAntennaStatus2 3444;
BA_ "SAEDocument" SG_ 3221225472 NetworkServiceStatus2 "J1939-71";
BA_ "SPN" SG_ 3221225472 NetworkServiceStatus2 3443;
BA_ "SAEDocument" SG_ 3221225472 NetworkTransceiverStatus2 "J1939-71";
BA_ "SPN" SG_ 3221225472 NetworkTransceiverStatus2 3442;
BA_ "SAEDocument" SG_ 3221225472 WrelessCommunicationNetworkType1 "J1939-71";
BA_ "SPN" SG_ 3221225472 WrelessCommunicationNetworkType1 3372;
BA_ "SAEDocument" SG_ 3221225472 NetworkSignalStrength1 "J1939-71";
BA_ "SPN" SG_ 3221225472 NetworkSignalStrength1 3371;
BA_ "SAEDocument" SG_ 3221225472 NetworkAntennaStatus1 "J1939-71";
BA_ "SPN" SG_ 3221225472 NetworkAntennaStatus1 3370;
BA_ "SAEDocument" SG_ 3221225472 NetworkServiceStatus1 "J1939-71";
BA_ "SPN" SG_ 3221225472 NetworkServiceStatus1 3369;
BA_ "SAEDocument" SG_ 3221225472 NetworkTransceiverStatus1 "J1939-71";
BA_ "SPN" SG_ 3221225472 NetworkTransceiverStatus1 3368;
BA_ "SAEDocument" SG_ 3221225472 VoltageRegulatorEnabled "J1939-75";
BA_ "SPN" SG_ 3221225472 VoltageRegulatorEnabled 3379;
BA_ "SigType" SG_ 3221225472 VoltageRegulatorEnabled 4;
BA_ "SAEDocument" SG_ 3221225472 VoltageRegulatorSoftStartState "J1939-75";
BA_ "SPN" SG_ 3221225472 VoltageRegulatorSoftStartState 3378;
BA_ "SigType" SG_ 3221225472 VoltageRegulatorSoftStartState 4;
BA_ "SAEDocument" SG_ 3221225472 VltgRgltrUndrfrqncyCmpnstnEnbld "J1939-75";
BA_ "SPN" SG_ 3221225472 VltgRgltrUndrfrqncyCmpnstnEnbld 3377;
BA_ "SigType" SG_ 3221225472 VltgRgltrUndrfrqncyCmpnstnEnbld 4;
BA_ "SAEDocument" SG_ 3221225472 VltgRgltrVAr_PwrFctrOprtingMode "J1939-75";
BA_ "SPN" SG_ 3221225472 VltgRgltrVAr_PwrFctrOprtingMode 3376;
BA_ "SAEDocument" SG_ 3221225472 VltgRglatorLoadCompensationMode "J1939-75";
BA_ "SPN" SG_ 3221225472 VltgRglatorLoadCompensationMode 3375;
BA_ "SAEDocument" SG_ 3221225472 GnrtrOtputVoltageBiasPercentage "J1939-75";
BA_ "SPN" SG_ 3221225472 GnrtrOtputVoltageBiasPercentage 3382;
BA_ "SigType" SG_ 3221225472 GnrtrOtputVoltageBiasPercentage 1;
BA_ "SAEDocument" SG_ 3221225472 GeneratorExcitationFieldCurrent "J1939-75";
BA_ "SPN" SG_ 3221225472 GeneratorExcitationFieldCurrent 3381;
BA_ "SigType" SG_ 3221225472 GeneratorExcitationFieldCurrent 1;
BA_ "SAEDocument" SG_ 3221225472 GeneratorExcitationFieldVoltage "J1939-75";
BA_ "SPN" SG_ 3221225472 GeneratorExcitationFieldVoltage 3380;
BA_ "SigType" SG_ 3221225472 GeneratorExcitationFieldVoltage 1;
BA_ "SAEDocument" SG_ 3221225472 RunningLightCmd "J1939-71";
BA_ "SPN" SG_ 3221225472 RunningLightCmd 2403;
BA_ "SigType" SG_ 3221225472 RunningLightCmd 5;
BA_ "SAEDocument" SG_ 3221225472 AltBeamHeadLightCmd "J1939-71";
BA_ "SPN" SG_ 3221225472 AltBeamHeadLightCmd 2351;
BA_ "SigType" SG_ 3221225472 AltBeamHeadLightCmd 5;
BA_ "SAEDocument" SG_ 3221225472 LowBeamHeadLightCmd "J1939-71";
BA_ "SPN" SG_ 3221225472 LowBeamHeadLightCmd 2349;
BA_ "SigType" SG_ 3221225472 LowBeamHeadLightCmd 5;
BA_ "SAEDocument" SG_ 3221225472 HighBeamHeadLightCmd "J1939-71";
BA_ "SPN" SG_ 3221225472 HighBeamHeadLightCmd 2347;
BA_ "SigType" SG_ 3221225472 HighBeamHeadLightCmd 5;
BA_ "SAEDocument" SG_ 3221225472 TractorFrontFogLightsCmd "J1939-71";
BA_ "SPN" SG_ 3221225472 TractorFrontFogLightsCmd 2387;
BA_ "SigType" SG_ 3221225472 TractorFrontFogLightsCmd 5;
BA_ "SAEDocument" SG_ 3221225472 RotatingBeaconLightCmd "J1939-71";
BA_ "SPN" SG_ 3221225472 RotatingBeaconLightCmd 2385;
BA_ "SigType" SG_ 3221225472 RotatingBeaconLightCmd 5;
BA_ "SAEDocument" SG_ 3221225472 RightTurnSignalLightsCmd "J1939-71";
BA_ "SPN" SG_ 3221225472 RightTurnSignalLightsCmd 2369;
BA_ "SigType" SG_ 3221225472 RightTurnSignalLightsCmd 5;
BA_ "SAEDocument" SG_ 3221225472 LeftTurnSignalLightsCmd "J1939-71";
BA_ "SPN" SG_ 3221225472 LeftTurnSignalLightsCmd 2367;
BA_ "SigType" SG_ 3221225472 LeftTurnSignalLightsCmd 5;
BA_ "SAEDocument" SG_ 3221225472 BackUpLightAndAlarmHornCmd "J1939-71";
BA_ "SPN" SG_ 3221225472 BackUpLightAndAlarmHornCmd 2391;
BA_ "SigType" SG_ 3221225472 BackUpLightAndAlarmHornCmd 5;
BA_ "SAEDocument" SG_ 3221225472 CenterStopLightCmd "J1939-71";
BA_ "SPN" SG_ 3221225472 CenterStopLightCmd 2375;
BA_ "SigType" SG_ 3221225472 CenterStopLightCmd 5;
BA_ "SAEDocument" SG_ 3221225472 RightStopLightCmd "J1939-71";
BA_ "SPN" SG_ 3221225472 RightStopLightCmd 2373;
BA_ "SigType" SG_ 3221225472 RightStopLightCmd 5;
BA_ "SAEDocument" SG_ 3221225472 LeftStopLightCmd "J1939-71";
BA_ "SPN" SG_ 3221225472 LeftStopLightCmd 2371;
BA_ "SigType" SG_ 3221225472 LeftStopLightCmd 5;
BA_ "SAEDocument" SG_ 3221225472 ImplementClearanceLightCmd "J1939-71";
BA_ "SPN" SG_ 3221225472 ImplementClearanceLightCmd 2383;
BA_ "SigType" SG_ 3221225472 ImplementClearanceLightCmd 5;
BA_ "SAEDocument" SG_ 3221225472 TractorClearanceLightCmd "J1939-71";
BA_ "SPN" SG_ 3221225472 TractorClearanceLightCmd 2381;
BA_ "SigType" SG_ 3221225472 TractorClearanceLightCmd 5;
BA_ "SAEDocument" SG_ 3221225472 ImplementMarkerLightCmd "J1939-71";
BA_ "SPN" SG_ 3221225472 ImplementMarkerLightCmd 2379;
BA_ "SigType" SG_ 3221225472 ImplementMarkerLightCmd 5;
BA_ "SAEDocument" SG_ 3221225472 TractorMarkerLightCmd "J1939-71";
BA_ "SPN" SG_ 3221225472 TractorMarkerLightCmd 2377;
BA_ "SigType" SG_ 3221225472 TractorMarkerLightCmd 5;
BA_ "SAEDocument" SG_ 3221225472 RearFogLightCmd "J1939-71";
BA_ "SPN" SG_ 3221225472 RearFogLightCmd 2389;
BA_ "SigType" SG_ 3221225472 RearFogLightCmd 5;
BA_ "SAEDocument" SG_ 3221225472 TrctrUndrsdeMountedWorkLightsCmd "J1939-71";
BA_ "SPN" SG_ 3221225472 TrctrUndrsdeMountedWorkLightsCmd 2357;
BA_ "SigType" SG_ 3221225472 TrctrUndrsdeMountedWorkLightsCmd 5;
BA_ "SAEDocument" SG_ 3221225472 TrctrRearLowMountedWorkLightsCmd "J1939-71";
BA_ "SPN" SG_ 3221225472 TrctrRearLowMountedWorkLightsCmd 2359;
BA_ "SigType" SG_ 3221225472 TrctrRearLowMountedWorkLightsCmd 5;
BA_ "SAEDocument" SG_ 3221225472 TrctrRarHighMountedWorkLightsCmd "J1939-71";
BA_ "SPN" SG_ 3221225472 TrctrRarHighMountedWorkLightsCmd 2361;
BA_ "SigType" SG_ 3221225472 TrctrRarHighMountedWorkLightsCmd 5;
BA_ "SAEDocument" SG_ 3221225472 TrctrSideLowMountedWorkLightsCmd "J1939-71";
BA_ "SPN" SG_ 3221225472 TrctrSideLowMountedWorkLightsCmd 2363;
BA_ "SigType" SG_ 3221225472 TrctrSideLowMountedWorkLightsCmd 5;
BA_ "SAEDocument" SG_ 3221225472 TrctrSdeHighMountedWorkLightsCmd "J1939-71";
BA_ "SPN" SG_ 3221225472 TrctrSdeHighMountedWorkLightsCmd 2365;
BA_ "SigType" SG_ 3221225472 TrctrSdeHighMountedWorkLightsCmd 5;
BA_ "SAEDocument" SG_ 3221225472 TrctrFrntLowMountedWorkLightsCmd "J1939-71";
BA_ "SPN" SG_ 3221225472 TrctrFrntLowMountedWorkLightsCmd 2353;
BA_ "SigType" SG_ 3221225472 TrctrFrntLowMountedWorkLightsCmd 5;
BA_ "SAEDocument" SG_ 3221225472 TrctrFrntHghMountedWorkLightsCmd "J1939-71";
BA_ "SPN" SG_ 3221225472 TrctrFrntHghMountedWorkLightsCmd 2355;
BA_ "SigType" SG_ 3221225472 TrctrFrntHghMountedWorkLightsCmd 5;
BA_ "SAEDocument" SG_ 3221225472 ImplementOEMOption2LightCmd "J1939-71";
BA_ "SPN" SG_ 3221225472 ImplementOEMOption2LightCmd 2397;
BA_ "SigType" SG_ 3221225472 ImplementOEMOption2LightCmd 5;
BA_ "SAEDocument" SG_ 3221225472 ImplementOEMOption1LightCmd "J1939-71";
BA_ "SPN" SG_ 3221225472 ImplementOEMOption1LightCmd 2395;
BA_ "SigType" SG_ 3221225472 ImplementOEMOption1LightCmd 5;
BA_ "SAEDocument" SG_ 3221225472 ImplementRightFacingWorkLightCmd "J1939-71";
BA_ "SPN" SG_ 3221225472 ImplementRightFacingWorkLightCmd 2406;
BA_ "SigType" SG_ 3221225472 ImplementRightFacingWorkLightCmd 5;
BA_ "SAEDocument" SG_ 3221225472 ImplementLeftFacingWorkLightCmd "J1939-71";
BA_ "SPN" SG_ 3221225472 ImplementLeftFacingWorkLightCmd 2597;
BA_ "SigType" SG_ 3221225472 ImplementLeftFacingWorkLightCmd 5;
BA_ "SAEDocument" SG_ 3221225472 LightingDataRqCmd "J1939-71";
BA_ "SPN" SG_ 3221225472 LightingDataRqCmd 2393;
BA_ "SigType" SG_ 3221225472 LightingDataRqCmd 5;
BA_ "SAEDocument" SG_ 3221225472 ImplmentRightForwardWorkLightCmd "J1939-71";
BA_ "SPN" SG_ 3221225472 ImplmentRightForwardWorkLightCmd 2401;
BA_ "SigType" SG_ 3221225472 ImplmentRightForwardWorkLightCmd 5;
BA_ "SAEDocument" SG_ 3221225472 ImplementLeftForwardWorkLightCmd "J1939-71";
BA_ "SPN" SG_ 3221225472 ImplementLeftForwardWorkLightCmd 2399;
BA_ "SigType" SG_ 3221225472 ImplementLeftForwardWorkLightCmd 5;
BA_ "SAEDocument" SG_ 3221225472 ImplementRearWorkLightCmd "J1939-71";
BA_ "SPN" SG_ 3221225472 ImplementRearWorkLightCmd 2405;
BA_ "SigType" SG_ 3221225472 ImplementRearWorkLightCmd 5;
BA_ "SAEDocument" SG_ 3221225472 ActualInnerWheelSteerAngle "J1939-71";
BA_ "SPN" SG_ 3221225472 ActualInnerWheelSteerAngle 2927;
BA_ "SigType" SG_ 3221225472 ActualInnerWheelSteerAngle 1;
BA_ "SAEDocument" SG_ 3221225472 StatusOfSteerAxle "J1939-71";
BA_ "SPN" SG_ 3221225472 StatusOfSteerAxle 2923;
BA_ "SAEDocument" SG_ 3221225472 SteerableLiftAxleLoweringInhibit "J1939-71";
BA_ "SPN" SG_ 3221225472 SteerableLiftAxleLoweringInhibit 2922;
BA_ "SigType" SG_ 3221225472 SteerableLiftAxleLoweringInhibit 5;
BA_ "SAEDocument" SG_ 3221225472 SteerType "J1939-71";
BA_ "SPN" SG_ 3221225472 SteerType 2924;
BA_ "SAEDocument" SG_ 3221225472 TypeOfSteerForces "J1939-71";
BA_ "SPN" SG_ 3221225472 TypeOfSteerForces 2925;
BA_ "SAEDocument" SG_ 3221225472 TypeOfSteerTrans "J1939-71";
BA_ "SPN" SG_ 3221225472 TypeOfSteerTrans 2926;
BA_ "SAEDocument" SG_ 3221225472 ASREngCtrlActive "J1939-71";
BA_ "SPN" SG_ 3221225472 ASREngCtrlActive 561;
BA_ "SigType" SG_ 3221225472 ASREngCtrlActive 5;
BA_ "SAEDocument" SG_ 3221225472 ASRBrakeCtrlActive "J1939-71";
BA_ "SPN" SG_ 3221225472 ASRBrakeCtrlActive 562;
BA_ "SigType" SG_ 3221225472 ASRBrakeCtrlActive 5;
BA_ "SAEDocument" SG_ 3221225472 AntiLockBrakingActive "J1939-71";
BA_ "SPN" SG_ 3221225472 AntiLockBrakingActive 563;
BA_ "SigType" SG_ 3221225472 AntiLockBrakingActive 5;
BA_ "SAEDocument" SG_ 3221225472 ABSOffroadSwitch "J1939-71";
BA_ "SPN" SG_ 3221225472 ABSOffroadSwitch 575;
BA_ "SigType" SG_ 3221225472 ABSOffroadSwitch 4;
BA_ "SAEDocument" SG_ 3221225472 ASROffroadSwitch "J1939-71";
BA_ "SPN" SG_ 3221225472 ASROffroadSwitch 576;
BA_ "SigType" SG_ 3221225472 ASROffroadSwitch 4;
BA_ "SAEDocument" SG_ 3221225472 ASRHillHolderSwitch "J1939-71";
BA_ "SPN" SG_ 3221225472 ASRHillHolderSwitch 577;
BA_ "SigType" SG_ 3221225472 ASRHillHolderSwitch 4;
BA_ "SAEDocument" SG_ 3221225472 TractionCtrlOverrideSwitch "J1939-71";
BA_ "SPN" SG_ 3221225472 TractionCtrlOverrideSwitch 1238;
BA_ "SigType" SG_ 3221225472 TractionCtrlOverrideSwitch 4;
BA_ "SAEDocument" SG_ 3221225472 AccelInterlockSwitch "J1939-71";
BA_ "SPN" SG_ 3221225472 AccelInterlockSwitch 972;
BA_ "SigType" SG_ 3221225472 AccelInterlockSwitch 4;
BA_ "SAEDocument" SG_ 3221225472 EngDerateSwitch "J1939-71";
BA_ "SPN" SG_ 3221225472 EngDerateSwitch 971;
BA_ "SigType" SG_ 3221225472 EngDerateSwitch 4;
BA_ "SAEDocument" SG_ 3221225472 EngAuxShutdownSwitch "J1939-71";
BA_ "SPN" SG_ 3221225472 EngAuxShutdownSwitch 970;
BA_ "SigType" SG_ 3221225472 EngAuxShutdownSwitch 4;
BA_ "SAEDocument" SG_ 3221225472 RemoteAccelEnableSwitch "J1939-71";
BA_ "SPN" SG_ 3221225472 RemoteAccelEnableSwitch 969;
BA_ "SigType" SG_ 3221225472 RemoteAccelEnableSwitch 4;
BA_ "SAEDocument" SG_ 3221225472 EngRetarderSelection "J1939-71";
BA_ "SPN" SG_ 3221225472 EngRetarderSelection 973;
BA_ "SigType" SG_ 3221225472 EngRetarderSelection 1;
BA_ "SAEDocument" SG_ 3221225472 ABSFullyOperational "J1939-71";
BA_ "SPN" SG_ 3221225472 ABSFullyOperational 1243;
BA_ "SigType" SG_ 3221225472 ABSFullyOperational 5;
BA_ "SAEDocument" SG_ 3221225472 EBSRedWarningSignal "J1939-71";
BA_ "SPN" SG_ 3221225472 EBSRedWarningSignal 1439;
BA_ "SigType" SG_ 3221225472 EBSRedWarningSignal 5;
BA_ "SAEDocument" SG_ 3221225472 ABS_EBSAmberWarningSignal "J1939-71";
BA_ "SPN" SG_ 3221225472 ABS_EBSAmberWarningSignal 1438;
BA_ "SigType" SG_ 3221225472 ABS_EBSAmberWarningSignal 5;
BA_ "SAEDocument" SG_ 3221225472 ATC_ASRInformationSignal "J1939-71";
BA_ "SPN" SG_ 3221225472 ATC_ASRInformationSignal 1793;
BA_ "SigType" SG_ 3221225472 ATC_ASRInformationSignal 5;
BA_ "SAEDocument" SG_ 3221225472 SrcAddrssOfCntrllngDvcFrBrkeCtrl "J1939-71";
BA_ "SPN" SG_ 3221225472 SrcAddrssOfCntrllngDvcFrBrkeCtrl 1481;
BA_ "SAEDocument" SG_ 3221225472 HaltBrakeSwitch "J1939-71";
BA_ "SPN" SG_ 3221225472 HaltBrakeSwitch 2911;
BA_ "SigType" SG_ 3221225472 HaltBrakeSwitch 4;
BA_ "SAEDocument" SG_ 3221225472 TrailerABSStatus "J1939-71";
BA_ "SPN" SG_ 3221225472 TrailerABSStatus 1836;
BA_ "SigType" SG_ 3221225472 TrailerABSStatus 5;
BA_ "SAEDocument" SG_ 3221225472 TrctrMntdTrailerABSWarningSignal "J1939-71";
BA_ "SPN" SG_ 3221225472 TrctrMntdTrailerABSWarningSignal 1792;
BA_ "SigType" SG_ 3221225472 TrctrMntdTrailerABSWarningSignal 5;
BA_ "SAEDocument" SG_ 3221225472 RelativeSpeedFrontAxleLeftWheel "J1939-71";
BA_ "SPN" SG_ 3221225472 RelativeSpeedFrontAxleLeftWheel 905;
BA_ "SigType" SG_ 3221225472 RelativeSpeedFrontAxleLeftWheel 1;
BA_ "SAEDocument" SG_ 3221225472 RelativeSpeedFrontAxleRightWheel "J1939-71";
BA_ "SPN" SG_ 3221225472 RelativeSpeedFrontAxleRightWheel 906;
BA_ "SigType" SG_ 3221225472 RelativeSpeedFrontAxleRightWheel 1;
BA_ "SAEDocument" SG_ 3221225472 RelativeSpeedRearAxle1LeftWheel "J1939-71";
BA_ "SPN" SG_ 3221225472 RelativeSpeedRearAxle1LeftWheel 907;
BA_ "SigType" SG_ 3221225472 RelativeSpeedRearAxle1LeftWheel 1;
BA_ "SAEDocument" SG_ 3221225472 RelativeSpeedRearAxle1RightWheel "J1939-71";
BA_ "SPN" SG_ 3221225472 RelativeSpeedRearAxle1RightWheel 908;
BA_ "SigType" SG_ 3221225472 RelativeSpeedRearAxle1RightWheel 1;
BA_ "SAEDocument" SG_ 3221225472 RelativeSpeedRearAxle2LeftWheel "J1939-71";
BA_ "SPN" SG_ 3221225472 RelativeSpeedRearAxle2LeftWheel 909;
BA_ "SigType" SG_ 3221225472 RelativeSpeedRearAxle2LeftWheel 1;
BA_ "SAEDocument" SG_ 3221225472 RelativeSpeedRearAxle2RightWheel "J1939-71";
BA_ "SPN" SG_ 3221225472 RelativeSpeedRearAxle2RightWheel 910;
BA_ "SigType" SG_ 3221225472 RelativeSpeedRearAxle2RightWheel 1;
BA_ "SAEDocument" SG_ 3221225472 ImplementRearWorkLight "J1939-71";
BA_ "SPN" SG_ 3221225472 ImplementRearWorkLight 2394;
BA_ "SigType" SG_ 3221225472 ImplementRearWorkLight 4;
BA_ "SAEDocument" SG_ 3221225472 ImplementLeftForwardWorkLight "J1939-71";
BA_ "SPN" SG_ 3221225472 ImplementLeftForwardWorkLight 2400;
BA_ "SigType" SG_ 3221225472 ImplementLeftForwardWorkLight 4;
BA_ "SAEDocument" SG_ 3221225472 ImplementRightForwardWorkLight "J1939-71";
BA_ "SPN" SG_ 3221225472 ImplementRightForwardWorkLight 2402;
BA_ "SigType" SG_ 3221225472 ImplementRightForwardWorkLight 4;
BA_ "SAEDocument" SG_ 3221225472 ImplementLeftFacingWorkLight "J1939-71";
BA_ "SPN" SG_ 3221225472 ImplementLeftFacingWorkLight 2598;
BA_ "SigType" SG_ 3221225472 ImplementLeftFacingWorkLight 4;
BA_ "SAEDocument" SG_ 3221225472 ImplementRightFacingWorkLight "J1939-71";
BA_ "SPN" SG_ 3221225472 ImplementRightFacingWorkLight 2407;
BA_ "SigType" SG_ 3221225472 ImplementRightFacingWorkLight 4;
BA_ "SAEDocument" SG_ 3221225472 ImplementOEMOption1Light "J1939-71";
BA_ "SPN" SG_ 3221225472 ImplementOEMOption1Light 2396;
BA_ "SigType" SG_ 3221225472 ImplementOEMOption1Light 4;
BA_ "SAEDocument" SG_ 3221225472 ImplementOEMOption2Light "J1939-71";
BA_ "SPN" SG_ 3221225472 ImplementOEMOption2Light 2398;
BA_ "SigType" SG_ 3221225472 ImplementOEMOption2Light 4;
BA_ "SAEDocument" SG_ 3221225472 TrctorFrontHighMountedWorkLights "J1939-71";
BA_ "SPN" SG_ 3221225472 TrctorFrontHighMountedWorkLights 2356;
BA_ "SigType" SG_ 3221225472 TrctorFrontHighMountedWorkLights 4;
BA_ "SAEDocument" SG_ 3221225472 TractorFrontLowMountedWorkLights "J1939-71";
BA_ "SPN" SG_ 3221225472 TractorFrontLowMountedWorkLights 2354;
BA_ "SigType" SG_ 3221225472 TractorFrontLowMountedWorkLights 4;
BA_ "SAEDocument" SG_ 3221225472 TractorSideHighMountedWorkLights "J1939-71";
BA_ "SPN" SG_ 3221225472 TractorSideHighMountedWorkLights 2366;
BA_ "SigType" SG_ 3221225472 TractorSideHighMountedWorkLights 4;
BA_ "SAEDocument" SG_ 3221225472 TractorSideLowMountedWorkLights "J1939-71";
BA_ "SPN" SG_ 3221225472 TractorSideLowMountedWorkLights 2364;
BA_ "SigType" SG_ 3221225472 TractorSideLowMountedWorkLights 4;
BA_ "SAEDocument" SG_ 3221225472 TractorRearHighMountedWorkLights "J1939-71";
BA_ "SPN" SG_ 3221225472 TractorRearHighMountedWorkLights 2362;
BA_ "SigType" SG_ 3221225472 TractorRearHighMountedWorkLights 4;
BA_ "SAEDocument" SG_ 3221225472 TractorRearLowMountedWorkLights "J1939-71";
BA_ "SPN" SG_ 3221225472 TractorRearLowMountedWorkLights 2360;
BA_ "SigType" SG_ 3221225472 TractorRearLowMountedWorkLights 4;
BA_ "SAEDocument" SG_ 3221225472 TrctorUndersideMountedWorkLights "J1939-71";
BA_ "SPN" SG_ 3221225472 TrctorUndersideMountedWorkLights 2358;
BA_ "SigType" SG_ 3221225472 TrctorUndersideMountedWorkLights 4;
BA_ "SAEDocument" SG_ 3221225472 RearFogLights "J1939-71";
BA_ "SPN" SG_ 3221225472 RearFogLights 2390;
BA_ "SigType" SG_ 3221225472 RearFogLights 4;
BA_ "SAEDocument" SG_ 3221225472 TractorMarkerLight "J1939-71";
BA_ "SPN" SG_ 3221225472 TractorMarkerLight 2378;
BA_ "SigType" SG_ 3221225472 TractorMarkerLight 4;
BA_ "SAEDocument" SG_ 3221225472 ImplementMarkerLight "J1939-71";
BA_ "SPN" SG_ 3221225472 ImplementMarkerLight 2380;
BA_ "SigType" SG_ 3221225472 ImplementMarkerLight 4;
BA_ "SAEDocument" SG_ 3221225472 TractorClearanceLight "J1939-71";
BA_ "SPN" SG_ 3221225472 TractorClearanceLight 2382;
BA_ "SigType" SG_ 3221225472 TractorClearanceLight 4;
BA_ "SAEDocument" SG_ 3221225472 ImplementClearanceLight "J1939-71";
BA_ "SPN" SG_ 3221225472 ImplementClearanceLight 2384;
BA_ "SigType" SG_ 3221225472 ImplementClearanceLight 4;
BA_ "SAEDocument" SG_ 3221225472 LeftStopLight "J1939-71";
BA_ "SPN" SG_ 3221225472 LeftStopLight 2372;
BA_ "SigType" SG_ 3221225472 LeftStopLight 4;
BA_ "SAEDocument" SG_ 3221225472 RightStopLight "J1939-71";
BA_ "SPN" SG_ 3221225472 RightStopLight 2374;
BA_ "SigType" SG_ 3221225472 RightStopLight 4;
BA_ "SAEDocument" SG_ 3221225472 CenterStopLight "J1939-71";
BA_ "SPN" SG_ 3221225472 CenterStopLight 2376;
BA_ "SigType" SG_ 3221225472 CenterStopLight 4;
BA_ "SAEDocument" SG_ 3221225472 BackUpLightAndAlarmHorn "J1939-71";
BA_ "SPN" SG_ 3221225472 BackUpLightAndAlarmHorn 2392;
BA_ "SigType" SG_ 3221225472 BackUpLightAndAlarmHorn 4;
BA_ "SAEDocument" SG_ 3221225472 RotatingBeaconLight "J1939-71";
BA_ "SPN" SG_ 3221225472 RotatingBeaconLight 2386;
BA_ "SigType" SG_ 3221225472 RotatingBeaconLight 4;
BA_ "SAEDocument" SG_ 3221225472 TractorFrontFogLights "J1939-71";
BA_ "SPN" SG_ 3221225472 TractorFrontFogLights 2388;
BA_ "SigType" SG_ 3221225472 TractorFrontFogLights 4;
BA_ "SAEDocument" SG_ 3221225472 HighBeamHeadLightData "J1939-71";
BA_ "SPN" SG_ 3221225472 HighBeamHeadLightData 2348;
BA_ "SigType" SG_ 3221225472 HighBeamHeadLightData 4;
BA_ "SAEDocument" SG_ 3221225472 LowBeamHeadLightData "J1939-71";
BA_ "SPN" SG_ 3221225472 LowBeamHeadLightData 2350;
BA_ "SigType" SG_ 3221225472 LowBeamHeadLightData 4;
BA_ "SAEDocument" SG_ 3221225472 AltBeamHeadLightData "J1939-71";
BA_ "SPN" SG_ 3221225472 AltBeamHeadLightData 2352;
BA_ "SigType" SG_ 3221225472 AltBeamHeadLightData 4;
BA_ "SAEDocument" SG_ 3221225472 RunningLight "J1939-71";
BA_ "SPN" SG_ 3221225472 RunningLight 2404;
BA_ "SigType" SG_ 3221225472 RunningLight 4;
BA_ "SAEDocument" SG_ 3221225472 VehicleOverspeed "J1939-71";
BA_ "SPN" SG_ 3221225472 VehicleOverspeed 1614;
BA_ "SigType" SG_ 3221225472 VehicleOverspeed 4;
BA_ "SAEDocument" SG_ 3221225472 VehicleMotion "J1939-71";
BA_ "SPN" SG_ 3221225472 VehicleMotion 1611;
BA_ "SigType" SG_ 3221225472 VehicleMotion 4;
BA_ "SAEDocument" SG_ 3221225472 TachographOutputShaftSpeed "J1939-71";
BA_ "SPN" SG_ 3221225472 TachographOutputShaftSpeed 1623;
BA_ "SigType" SG_ 3221225472 TachographOutputShaftSpeed 1;
BA_ "SAEDocument" SG_ 3221225472 DirectionIndicator "J1939-71";
BA_ "SPN" SG_ 3221225472 DirectionIndicator 1619;
BA_ "SigType" SG_ 3221225472 DirectionIndicator 4;
BA_ "SAEDocument" SG_ 3221225472 TachographPerformance "J1939-71";
BA_ "SPN" SG_ 3221225472 TachographPerformance 1620;
BA_ "SigType" SG_ 3221225472 TachographPerformance 5;
BA_ "SAEDocument" SG_ 3221225472 HandlingInformation "J1939-71";
BA_ "SPN" SG_ 3221225472 HandlingInformation 1621;
BA_ "SigType" SG_ 3221225472 HandlingInformation 5;
BA_ "SAEDocument" SG_ 3221225472 SystemEvent "J1939-71";
BA_ "SPN" SG_ 3221225472 SystemEvent 1622;
BA_ "SigType" SG_ 3221225472 SystemEvent 5;
BA_ "SAEDocument" SG_ 3221225472 DriverCardDriver2 "J1939-71";
BA_ "SPN" SG_ 3221225472 DriverCardDriver2 1616;
BA_ "SigType" SG_ 3221225472 DriverCardDriver2 4;
BA_ "SAEDocument" SG_ 3221225472 Driver2TimeRelatedStates "J1939-71";
BA_ "SPN" SG_ 3221225472 Driver2TimeRelatedStates 1618;
BA_ "SAEDocument" SG_ 3221225472 DriverCardDriver1 "J1939-71";
BA_ "SPN" SG_ 3221225472 DriverCardDriver1 1615;
BA_ "SigType" SG_ 3221225472 DriverCardDriver1 4;
BA_ "SAEDocument" SG_ 3221225472 Driver1TimeRelatedStates "J1939-71";
BA_ "SPN" SG_ 3221225472 Driver1TimeRelatedStates 1617;
BA_ "SAEDocument" SG_ 3221225472 Driver2WorkingState "J1939-71";
BA_ "SPN" SG_ 3221225472 Driver2WorkingState 1613;
BA_ "SAEDocument" SG_ 3221225472 Driver1WorkingState "J1939-71";
BA_ "SPN" SG_ 3221225472 Driver1WorkingState 1612;
BA_ "SAEDocument" SG_ 3221225472 RearWasherFunction "J1939-71";
BA_ "SPN" SG_ 3221225472 RearWasherFunction 2868;
BA_ "SAEDocument" SG_ 3221225472 FrontOperatorWasherSwitch "J1939-71";
BA_ "SPN" SG_ 3221225472 FrontOperatorWasherSwitch 2866;
BA_ "SAEDocument" SG_ 3221225472 FrontNonoperatorWasherSwitch "J1939-71";
BA_ "SPN" SG_ 3221225472 FrontNonoperatorWasherSwitch 2867;
BA_ "SAEDocument" SG_ 3221225472 RearWiperDelayCtrl "J1939-71";
BA_ "SPN" SG_ 3221225472 RearWiperDelayCtrl 2871;
BA_ "SigType" SG_ 3221225472 RearWiperDelayCtrl 1;
BA_ "SAEDocument" SG_ 3221225472 FrontNonoperatorWiperDelayCtrl "J1939-71";
BA_ "SPN" SG_ 3221225472 FrontNonoperatorWiperDelayCtrl 2870;
BA_ "SigType" SG_ 3221225472 FrontNonoperatorWiperDelayCtrl 1;
BA_ "SAEDocument" SG_ 3221225472 FrontOperatorWiperDelayCtrl "J1939-71";
BA_ "SPN" SG_ 3221225472 FrontOperatorWiperDelayCtrl 2869;
BA_ "SigType" SG_ 3221225472 FrontOperatorWiperDelayCtrl 1;
BA_ "SAEDocument" SG_ 3221225472 RearWiperSwitch "J1939-71";
BA_ "SPN" SG_ 3221225472 RearWiperSwitch 2865;
BA_ "SAEDocument" SG_ 3221225472 FrontOperatorWiperSwitch "J1939-71";
BA_ "SPN" SG_ 3221225472 FrontOperatorWiperSwitch 2863;
BA_ "SAEDocument" SG_ 3221225472 FrontNonoperatorWiperSwitch "J1939-71";
BA_ "SPN" SG_ 3221225472 FrontNonoperatorWiperSwitch 2864;
BA_ "SAEDocument" SG_ 3221225472 OprtorsDesiredDelayedLampOffTime "J1939-71";
BA_ "SPN" SG_ 3221225472 OprtorsDesiredDelayedLampOffTime 2877;
BA_ "SigType" SG_ 3221225472 OprtorsDesiredDelayedLampOffTime 1;
BA_ "SAEDocument" SG_ 3221225472 OperatorsDesiredBacklight "J1939-71";
BA_ "SPN" SG_ 3221225472 OperatorsDesiredBacklight 2878;
BA_ "SigType" SG_ 3221225472 OperatorsDesiredBacklight 1;
BA_ "SAEDocument" SG_ 3221225472 HighLowBeamSwitch "J1939-71";
BA_ "SPN" SG_ 3221225472 HighLowBeamSwitch 2874;
BA_ "SigType" SG_ 3221225472 HighLowBeamSwitch 4;
BA_ "SAEDocument" SG_ 3221225472 HazardLightSwitch "J1939-71";
BA_ "SPN" SG_ 3221225472 HazardLightSwitch 2875;
BA_ "SigType" SG_ 3221225472 HazardLightSwitch 4;
BA_ "SAEDocument" SG_ 3221225472 TurnSignalSwitch "J1939-71";
BA_ "SPN" SG_ 3221225472 TurnSignalSwitch 2876;
BA_ "SAEDocument" SG_ 3221225472 MainLightSwitch "J1939-71";
BA_ "SPN" SG_ 3221225472 MainLightSwitch 2872;
BA_ "SAEDocument" SG_ 3221225472 WorkLightSwitch "J1939-71";
BA_ "SPN" SG_ 3221225472 WorkLightSwitch 2873;
BA_ "SAEDocument" SG_ 3221225472 LaneDepartureImminentLeftSide "J1939-71";
BA_ "SPN" SG_ 3221225472 LaneDepartureImminentLeftSide 1700;
BA_ "SigType" SG_ 3221225472 LaneDepartureImminentLeftSide 5;
BA_ "SAEDocument" SG_ 3221225472 LaneDepartureImminentRightSide "J1939-71";
BA_ "SPN" SG_ 3221225472 LaneDepartureImminentRightSide 1701;
BA_ "SigType" SG_ 3221225472 LaneDepartureImminentRightSide 5;
BA_ "SAEDocument" SG_ 3221225472 LaneDepartureRight "J1939-71";
BA_ "SPN" SG_ 3221225472 LaneDepartureRight 3566;
BA_ "SigType" SG_ 3221225472 LaneDepartureRight 5;
BA_ "SAEDocument" SG_ 3221225472 LaneDepartureLeft "J1939-71";
BA_ "SPN" SG_ 3221225472 LaneDepartureLeft 3565;
BA_ "SigType" SG_ 3221225472 LaneDepartureLeft 5;
BA_ "SAEDocument" SG_ 3221225472 TransCurrentRange "J1939-71";
BA_ "SPN" SG_ 3221225472 TransCurrentRange 163;
BA_ "SAEDocument" SG_ 3221225472 TransRequestedRange "J1939-71";
BA_ "SPN" SG_ 3221225472 TransRequestedRange 162;
BA_ "SAEDocument" SG_ 3221225472 TransCurrentGear "J1939-71";
BA_ "SPN" SG_ 3221225472 TransCurrentGear 523;
BA_ "SigType" SG_ 3221225472 TransCurrentGear 1;
BA_ "SAEDocument" SG_ 3221225472 TransActualGearRatio "J1939-71";
BA_ "SPN" SG_ 3221225472 TransActualGearRatio 526;
BA_ "SigType" SG_ 3221225472 TransActualGearRatio 1;
BA_ "SAEDocument" SG_ 3221225472 TransSelectedGear "J1939-71";
BA_ "SPN" SG_ 3221225472 TransSelectedGear 524;
BA_ "SAEDocument" SG_ 3221225472 ActlMxAvlblRetarderPercentTorque "J1939-71";
BA_ "SPN" SG_ 3221225472 ActlMxAvlblRetarderPercentTorque 1717;
BA_ "SigType" SG_ 3221225472 ActlMxAvlblRetarderPercentTorque 1;
BA_ "SAEDocument" SG_ 3221225472 RetarderSelectionNonengine "J1939-71";
BA_ "SPN" SG_ 3221225472 RetarderSelectionNonengine 1716;
BA_ "SigType" SG_ 3221225472 RetarderSelectionNonengine 1;
BA_ "SAEDocument" SG_ 3221225472 DrvrsDemandRetarderPercentTorque "J1939-71";
BA_ "SPN" SG_ 3221225472 DrvrsDemandRetarderPercentTorque 1715;
BA_ "SAEDocument" SG_ 3221225472 SrcAddrssOfCntrllngDvcFrRtrdrCtr "J1939-71";
BA_ "SPN" SG_ 3221225472 SrcAddrssOfCntrllngDvcFrRtrdrCtr 1480;
BA_ "SAEDocument" SG_ 3221225472 RetarderRoadSpeedExceededStatus "J1939-71";
BA_ "SPN" SG_ 3221225472 RetarderRoadSpeedExceededStatus 4234;
BA_ "SigType" SG_ 3221225472 RetarderRoadSpeedExceededStatus 5;
BA_ "SAEDocument" SG_ 3221225472 RetarderRoadSpeedLimitSwitch "J1939-71";
BA_ "SPN" SG_ 3221225472 RetarderRoadSpeedLimitSwitch 4233;
BA_ "SigType" SG_ 3221225472 RetarderRoadSpeedLimitSwitch 4;
BA_ "SAEDocument" SG_ 3221225472 RetarderRequestingBrakeLight "J1939-71";
BA_ "SPN" SG_ 3221225472 RetarderRequestingBrakeLight 1667;
BA_ "SigType" SG_ 3221225472 RetarderRequestingBrakeLight 5;
BA_ "SAEDocument" SG_ 3221225472 EngCoolantLoadIncrease "J1939-71";
BA_ "SPN" SG_ 3221225472 EngCoolantLoadIncrease 1082;
BA_ "SigType" SG_ 3221225472 EngCoolantLoadIncrease 5;
BA_ "SAEDocument" SG_ 3221225472 IntendedRetarderPercentTorque "J1939-71";
BA_ "SPN" SG_ 3221225472 IntendedRetarderPercentTorque 1085;
BA_ "SAEDocument" SG_ 3221225472 ActualRetarderPercentTorque "J1939-71";
BA_ "SPN" SG_ 3221225472 ActualRetarderPercentTorque 520;
BA_ "SigType" SG_ 3221225472 ActualRetarderPercentTorque 1;
BA_ "SAEDocument" SG_ 3221225472 RetarderEnableShiftAssistSwitch "J1939-71";
BA_ "SPN" SG_ 3221225472 RetarderEnableShiftAssistSwitch 572;
BA_ "SigType" SG_ 3221225472 RetarderEnableShiftAssistSwitch 4;
BA_ "SAEDocument" SG_ 3221225472 RetarderEnableBrakeAssistSwitch "J1939-71";
BA_ "SPN" SG_ 3221225472 RetarderEnableBrakeAssistSwitch 571;
BA_ "SigType" SG_ 3221225472 RetarderEnableBrakeAssistSwitch 4;
BA_ "SAEDocument" SG_ 3221225472 RetarderTorqueMode "J1939-71";
BA_ "SPN" SG_ 3221225472 RetarderTorqueMode 900;
BA_ "SAEDocument" SG_ 3221225472 EstPumpingPercentTorque "J1939-71";
BA_ "SPN" SG_ 3221225472 EstPumpingPercentTorque 5398;
BA_ "SigType" SG_ 3221225472 EstPumpingPercentTorque 1;
BA_ "SAEDocument" SG_ 3221225472 ActlMaxAvailableEngPercentTorque "J1939-71";
BA_ "SPN" SG_ 3221225472 ActlMaxAvailableEngPercentTorque 3357;
BA_ "SigType" SG_ 3221225472 ActlMaxAvailableEngPercentTorque 1;
BA_ "SAEDocument" SG_ 3221225472 SCRThermalManagementActive "J1939-71";
BA_ "SPN" SG_ 3221225472 SCRThermalManagementActive 5400;
BA_ "SigType" SG_ 3221225472 SCRThermalManagementActive 5;
BA_ "SAEDocument" SG_ 3221225472 DPFThermalManagementActive "J1939-71";
BA_ "SPN" SG_ 3221225472 DPFThermalManagementActive 5399;
BA_ "SigType" SG_ 3221225472 DPFThermalManagementActive 5;
BA_ "SAEDocument" SG_ 3221225472 MmntaryEngMaxPowerEnableFeedback "J1939-71";
BA_ "SPN" SG_ 3221225472 MmntaryEngMaxPowerEnableFeedback 5021;
BA_ "SigType" SG_ 3221225472 MmntaryEngMaxPowerEnableFeedback 5;
BA_ "SAEDocument" SG_ 3221225472 VhcleAccelerationRateLimitStatus "J1939-71";
BA_ "SPN" SG_ 3221225472 VhcleAccelerationRateLimitStatus 2979;
BA_ "SigType" SG_ 3221225472 VhcleAccelerationRateLimitStatus 5;
BA_ "SAEDocument" SG_ 3221225472 AccelPedalPos2 "J1939-71";
BA_ "SPN" SG_ 3221225472 AccelPedalPos2 29;
BA_ "SigType" SG_ 3221225472 AccelPedalPos2 1;
BA_ "SAEDocument" SG_ 3221225472 RemoteAccelPedalPos "J1939-71";
BA_ "SPN" SG_ 3221225472 RemoteAccelPedalPos 974;
BA_ "SigType" SG_ 3221225472 RemoteAccelPedalPos 1;
BA_ "SAEDocument" SG_ 3221225472 AccelPedal2LowIdleSwitch "J1939-71";
BA_ "SPN" SG_ 3221225472 AccelPedal2LowIdleSwitch 2970;
BA_ "SigType" SG_ 3221225472 AccelPedal2LowIdleSwitch 4;
BA_ "SAEDocument" SG_ 3221225472 RoadSpeedLimitStatus "J1939-71";
BA_ "SPN" SG_ 3221225472 RoadSpeedLimitStatus 1437;
BA_ "SigType" SG_ 3221225472 RoadSpeedLimitStatus 5;
BA_ "SAEDocument" SG_ 3221225472 AccelPedalKickdownSwitch "J1939-71";
BA_ "SPN" SG_ 3221225472 AccelPedalKickdownSwitch 559;
BA_ "SigType" SG_ 3221225472 AccelPedalKickdownSwitch 4;
BA_ "SAEDocument" SG_ 3221225472 AccelPedal1LowIdleSwitch "J1939-71";
BA_ "SPN" SG_ 3221225472 AccelPedal1LowIdleSwitch 558;
BA_ "SigType" SG_ 3221225472 AccelPedal1LowIdleSwitch 4;
BA_ "SAEDocument" SG_ 3221225472 EngShutdownOverrideSwitch "J1939-71";
BA_ "SPN" SG_ 3221225472 EngShutdownOverrideSwitch 1237;
BA_ "SigType" SG_ 3221225472 EngShutdownOverrideSwitch 4;
BA_ "SAEDocument" SG_ 3221225472 EngTestModeSwitch "J1939-71";
BA_ "SPN" SG_ 3221225472 EngTestModeSwitch 966;
BA_ "SigType" SG_ 3221225472 EngTestModeSwitch 4;
BA_ "SAEDocument" SG_ 3221225472 EngIdleDecrementSwitch "J1939-71";
BA_ "SPN" SG_ 3221225472 EngIdleDecrementSwitch 967;
BA_ "SigType" SG_ 3221225472 EngIdleDecrementSwitch 4;
BA_ "SAEDocument" SG_ 3221225472 EngIdleIncrementSwitch "J1939-71";
BA_ "SPN" SG_ 3221225472 EngIdleIncrementSwitch 968;
BA_ "SigType" SG_ 3221225472 EngIdleIncrementSwitch 4;
BA_ "SAEDocument" SG_ 3221225472 CruiseCtrlStates "J1939-71";
BA_ "SPN" SG_ 3221225472 CruiseCtrlStates 527;
BA_ "SAEDocument" SG_ 3221225472 PTOGovernorState "J1939-71";
BA_ "SPN" SG_ 3221225472 PTOGovernorState 976;
BA_ "SAEDocument" SG_ 3221225472 CruiseCtrlSetSpeed "J1939-71";
BA_ "SPN" SG_ 3221225472 CruiseCtrlSetSpeed 86;
BA_ "SigType" SG_ 3221225472 CruiseCtrlSetSpeed 1;
BA_ "SAEDocument" SG_ 3221225472 CruiseCtrlAccelerateSwitch "J1939-71";
BA_ "SPN" SG_ 3221225472 CruiseCtrlAccelerateSwitch 602;
BA_ "SigType" SG_ 3221225472 CruiseCtrlAccelerateSwitch 4;
BA_ "SAEDocument" SG_ 3221225472 CruiseCtrlResumeSwitch "J1939-71";
BA_ "SPN" SG_ 3221225472 CruiseCtrlResumeSwitch 601;
BA_ "SigType" SG_ 3221225472 CruiseCtrlResumeSwitch 4;
BA_ "SAEDocument" SG_ 3221225472 CruiseCtrlCoastSwitch "J1939-71";
BA_ "SPN" SG_ 3221225472 CruiseCtrlCoastSwitch 600;
BA_ "SigType" SG_ 3221225472 CruiseCtrlCoastSwitch 4;
BA_ "SAEDocument" SG_ 3221225472 CruiseCtrlSetSwitch "J1939-71";
BA_ "SPN" SG_ 3221225472 CruiseCtrlSetSwitch 599;
BA_ "SigType" SG_ 3221225472 CruiseCtrlSetSwitch 4;
BA_ "SAEDocument" SG_ 3221225472 ClutchSwitch "J1939-71";
BA_ "SPN" SG_ 3221225472 ClutchSwitch 598;
BA_ "SigType" SG_ 3221225472 ClutchSwitch 4;
BA_ "SAEDocument" SG_ 3221225472 BrakeSwitch "J1939-71";
BA_ "SPN" SG_ 3221225472 BrakeSwitch 597;
BA_ "SigType" SG_ 3221225472 BrakeSwitch 4;
BA_ "SAEDocument" SG_ 3221225472 CruiseCtrlEnableSwitch "J1939-71";
BA_ "SPN" SG_ 3221225472 CruiseCtrlEnableSwitch 596;
BA_ "SigType" SG_ 3221225472 CruiseCtrlEnableSwitch 4;
BA_ "SAEDocument" SG_ 3221225472 CruiseCtrlActive "J1939-71";
BA_ "SPN" SG_ 3221225472 CruiseCtrlActive 595;
BA_ "SigType" SG_ 3221225472 CruiseCtrlActive 4;
BA_ "SAEDocument" SG_ 3221225472 ParkBrakeReleaseInhibitRq "J1939-71";
BA_ "SPN" SG_ 3221225472 ParkBrakeReleaseInhibitRq 3807;
BA_ "SigType" SG_ 3221225472 ParkBrakeReleaseInhibitRq 5;
BA_ "SAEDocument" SG_ 3221225472 CruiseCtrlPauseSwitch "J1939-71";
BA_ "SPN" SG_ 3221225472 CruiseCtrlPauseSwitch 1633;
BA_ "SigType" SG_ 3221225472 CruiseCtrlPauseSwitch 4;
BA_ "SAEDocument" SG_ 3221225472 ParkingBrakeSwitch "J1939-71";
BA_ "SPN" SG_ 3221225472 ParkingBrakeSwitch 70;
BA_ "SigType" SG_ 3221225472 ParkingBrakeSwitch 4;
BA_ "SAEDocument" SG_ 3221225472 TwoSpeedAxleSwitch "J1939-71";
BA_ "SPN" SG_ 3221225472 TwoSpeedAxleSwitch 69;
BA_ "SigType" SG_ 3221225472 TwoSpeedAxleSwitch 4;
BA_ "SAEDocument" SG_ 2566799614 LeftTurnSignalLights "J1939-71";
BA_ "SPN" SG_ 2566799614 LeftTurnSignalLights 2368;
BA_ "SigType" SG_ 2566799614 LeftTurnSignalLights 4;
BA_ "SAEDocument" SG_ 2566799614 RightTurnSignalLights "J1939-71";
BA_ "SPN" SG_ 2566799614 RightTurnSignalLights 2370;
BA_ "SigType" SG_ 2566799614 RightTurnSignalLights 4;
BA_ "SAEDocument" SG_ 2565865739 BrakePedalPos "J1939-71";
BA_ "SPN" SG_ 2565865739 BrakePedalPos 521;
BA_ "SigType" SG_ 2565865739 BrakePedalPos 1;
BA_ "SAEDocument" SG_ 2565865739 EBSBrakeSwitch "J1939-71";
BA_ "SPN" SG_ 2565865739 EBSBrakeSwitch 1121;
BA_ "SigType" SG_ 2565865739 EBSBrakeSwitch 4;
BA_ "SAEDocument" SG_ 2364539687 AccelPedalPos1 "J1939-71";
BA_ "SPN" SG_ 2364539687 AccelPedalPos1 91;
BA_ "SigType" SG_ 2364539687 AccelPedalPos1 1;
BA_ "SAEDocument" SG_ 2298375691 RearAxleRightWheelSpeed "J1939-71";
BA_ "SPN" SG_ 2298375691 RearAxleRightWheelSpeed 1595;
BA_ "SigType" SG_ 2298375691 RearAxleRightWheelSpeed 1;
BA_ "SAEDocument" SG_ 2298375691 RearAxleLeftWheelSpeed "J1939-71";
BA_ "SPN" SG_ 2298375691 RearAxleLeftWheelSpeed 1594;
BA_ "SigType" SG_ 2298375691 RearAxleLeftWheelSpeed 1;
BA_ "SAEDocument" SG_ 2298375691 FrontAxleRightWheelSpeed "J1939-71";
BA_ "SPN" SG_ 2298375691 FrontAxleRightWheelSpeed 1593;
BA_ "SigType" SG_ 2298375691 FrontAxleRightWheelSpeed 1;
BA_ "SAEDocument" SG_ 2298375691 FrontAxleLeftWheelSpeed "J1939-71";
BA_ "SPN" SG_ 2298375691 FrontAxleLeftWheelSpeed 1592;
BA_ "SigType" SG_ 2298375691 FrontAxleLeftWheelSpeed 1;
BA_ "SAEDocument" SG_ 2566831883 FrontAxleSpeed "J1939-71";
BA_ "SPN" SG_ 2566831883 FrontAxleSpeed 904;
BA_ "SigType" SG_ 2566831883 FrontAxleSpeed 1;
BA_ "SAEDocument" SG_ 2565867787 LongitudinalAcceleration "J1939-71";
BA_ "SPN" SG_ 2565867787 LongitudinalAcceleration 1810;
BA_ "SigType" SG_ 2565867787 LongitudinalAcceleration 1;
BA_ "SAEDocument" SG_ 2565867787 LateralAcceleration "J1939-71";
BA_ "SPN" SG_ 2565867787 LateralAcceleration 1809;
BA_ "SigType" SG_ 2565867787 LateralAcceleration 1;
BA_ "SAEDocument" SG_ 2565867787 YawRate "J1939-71";
BA_ "SPN" SG_ 2565867787 YawRate 1808;
BA_ "SigType" SG_ 2565867787 YawRate 1;
BA_ "SAEDocument" SG_ 2565867787 SteerWheelAngleSensorType "J1939-71";
BA_ "SPN" SG_ 2565867787 SteerWheelAngleSensorType 1812;
BA_ "SigType" SG_ 2565867787 SteerWheelAngleSensorType 5;
BA_ "SAEDocument" SG_ 2565867787 SteerWheelTurnCounter "J1939-71";
BA_ "SPN" SG_ 2565867787 SteerWheelTurnCounter 1811;
BA_ "SAEDocument" SG_ 2565867787 SteerWheelAngle "J1939-71";
BA_ "SPN" SG_ 2565867787 SteerWheelAngle 1807;
BA_ "SigType" SG_ 2565867787 SteerWheelAngle 1;
BA_ "SAEDocument" SG_ 2365484055 TachographVehicleSpeed "J1939-71";
BA_ "SPN" SG_ 2365484055 TachographVehicleSpeed 1624;
BA_ "SigType" SG_ 2365484055 TachographVehicleSpeed 1;
VAL_ 3221225472 AuxI_O62 3 "Not Available or Take No Action depending on application" 2 "Error Indicator or Not Used  depending on application" 1 "Auxiliary channel on" 0 "Auxiliary channel off" ;
VAL_ 3221225472 AuxI_O63 3 "Not Available or Take No Action depending on application" 2 "Error Indicator or Not Used  depending on application" 1 "Auxiliary channel on" 0 "Auxiliary channel off" ;
VAL_ 3221225472 AuxI_O64 3 "Not Available or Take No Action depending on application" 2 "Error Indicator or Not Used  depending on application" 1 "Auxiliary channel on" 0 "Auxiliary channel off" ;
VAL_ 3221225472 AuxI_O57 3 "Not Available or Take No Action depending on application" 2 "Error Indicator or Not Used  depending on application" 1 "Auxiliary channel on" 0 "Auxiliary channel off" ;
VAL_ 3221225472 AuxI_O58 3 "Not Available or Take No Action depending on application" 2 "Error Indicator or Not Used  depending on application" 1 "Auxiliary channel on" 0 "Auxiliary channel off" ;
VAL_ 3221225472 AuxI_O59 3 "Not Available or Take No Action depending on application" 2 "Error Indicator or Not Used  depending on application" 1 "Auxiliary channel on" 0 "Auxiliary channel off" ;
VAL_ 3221225472 AuxI_O60 3 "Not Available or Take No Action depending on application" 2 "Error Indicator or Not Used  depending on application" 1 "Auxiliary channel on" 0 "Auxiliary channel off" ;
VAL_ 3221225472 AuxI_O53 3 "Not Available or Take No Action depending on application" 2 "Error Indicator or Not Used  depending on application" 1 "Auxiliary channel on" 0 "Auxiliary channel off" ;
VAL_ 3221225472 AuxI_O54 3 "Not Available or Take No Action depending on application" 2 "Error Indicator or Not Used  depending on application" 1 "Auxiliary channel on" 0 "Auxiliary channel off" ;
VAL_ 3221225472 AuxI_O55 3 "Not Available or Take No Action depending on application" 2 "Error Indicator or Not Used  depending on application" 1 "Auxiliary channel on" 0 "Auxiliary channel off" ;
VAL_ 3221225472 AuxI_O56 3 "Not Available or Take No Action depending on application" 2 "Error Indicator or Not Used  depending on application" 1 "Auxiliary channel on" 0 "Auxiliary channel off" ;
VAL_ 3221225472 AuxI_O49 3 "Not Available or Take No Action depending on application" 2 "Error Indicator or Not Used  depending on application" 1 "Auxiliary channel on" 0 "Auxiliary channel off" ;
VAL_ 3221225472 AuxI_O50 3 "Not Available or Take No Action depending on application" 2 "Error Indicator or Not Used  depending on application" 1 "Auxiliary channel on" 0 "Auxiliary channel off" ;
VAL_ 3221225472 AuxI_O51 3 "Not Available or Take No Action depending on application" 2 "Error Indicator or Not Used  depending on application" 1 "Auxiliary channel on" 0 "Auxiliary channel off" ;
VAL_ 3221225472 AuxI_O52 3 "Not Available or Take No Action depending on application" 2 "Error Indicator or Not Used  depending on application" 1 "Auxiliary channel on" 0 "Auxiliary channel off" ;
VAL_ 3221225472 AuxI_O109 3 "Not Available or Take No Action depending on application" 2 "Error Indicator or Not Used  depending on application" 1 "Auxiliary channel on" 0 "Auxiliary channel off" ;
VAL_ 3221225472 AuxI_O110 3 "Not Available or Take No Action depending on application" 2 "Error Indicator or Not Used  depending on application" 1 "Auxiliary channel on" 0 "Auxiliary channel off" ;
VAL_ 3221225472 AuxI_O111 3 "Not Available or Take No Action depending on application" 2 "Error Indicator or Not Used  depending on application" 1 "Auxiliary channel on" 0 "Auxiliary channel off" ;
VAL_ 3221225472 AuxI_O112 3 "Not Available or Take No Action depending on application" 2 "Error Indicator or Not Used  depending on application" 1 "Auxiliary channel on" 0 "Auxiliary channel off" ;
VAL_ 3221225472 AuxI_O105 3 "Not Available or Take No Action depending on application" 2 "Error Indicator or Not Used  depending on application" 1 "Auxiliary channel on" 0 "Auxiliary channel off" ;
VAL_ 3221225472 AuxI_O106 3 "Not Available or Take No Action depending on application" 2 "Error Indicator or Not Used  depending on application" 1 "Auxiliary channel on" 0 "Auxiliary channel off" ;
VAL_ 3221225472 AuxI_O107 3 "Not Available or Take No Action depending on application" 2 "Error Indicator or Not Used  depending on application" 1 "Auxiliary channel on" 0 "Auxiliary channel off" ;
VAL_ 3221225472 AuxI_O108 3 "Not Available or Take No Action depending on application" 2 "Error Indicator or Not Used  depending on application" 1 "Auxiliary channel on" 0 "Auxiliary channel off" ;
VAL_ 3221225472 AuxI_O101 2 "Error Indicator or Not Used  depending on application" 1 "Auxiliary channel on" 0 "Auxiliary channel off" 3 "Not Available or Take No Action depending on application" ;
VAL_ 3221225472 AuxI_O102 3 "Not Available or Take No Action depending on application" 2 "Error Indicator or Not Used  depending on application" 1 "Auxiliary channel on" 0 "Auxiliary channel off" ;
VAL_ 3221225472 AuxI_O103 3 "Not Available or Take No Action depending on application" 2 "Error Indicator or Not Used  depending on application" 1 "Auxiliary channel on" 0 "Auxiliary channel off" ;
VAL_ 3221225472 AuxI_O104 3 "Not Available or Take No Action depending on application" 2 "Error Indicator or Not Used  depending on application" 1 "Auxiliary channel on" 0 "Auxiliary channel off" ;
VAL_ 3221225472 AuxI_O97 3 "Not Available or Take No Action depending on application" 2 "Error Indicator or Not Used  depending on application" 1 "Auxiliary channel on" 0 "Auxiliary channel off" ;
VAL_ 3221225472 AuxI_O98 3 "Not Available or Take No Action depending on application" 2 "Error Indicator or Not Used  depending on application" 1 "Auxiliary channel on" 0 "Auxiliary channel off" ;
VAL_ 3221225472 AuxI_O99 3 "Not Available or Take No Action depending on application" 2 "Error Indicator or Not Used  depending on application" 1 "Auxiliary channel on" 0 "Auxiliary channel off" ;
VAL_ 3221225472 AuxI_O100 3 "Not Available or Take No Action depending on application" 2 "Error Indicator or Not Used  depending on application" 1 "Auxiliary channel on" 0 "Auxiliary channel off" ;
VAL_ 3221225472 AuxI_O93 3 "Not Available or Take No Action depending on application" 2 "Error Indicator or Not Used  depending on application" 1 "Auxiliary channel on" 0 "Auxiliary channel off" ;
VAL_ 3221225472 AuxI_O94 3 "Not Available or Take No Action depending on application" 2 "Error Indicator or Not Used  depending on application" 1 "Auxiliary channel on" 0 "Auxiliary channel off" ;
VAL_ 3221225472 AuxI_O95 3 "Not Available or Take No Action depending on application" 2 "Error Indicator or Not Used  depending on application" 1 "Auxiliary channel on" 0 "Auxiliary channel off" ;
VAL_ 3221225472 AuxI_O96 3 "Not Available or Take No Action depending on application" 2 "Error Indicator or Not Used  depending on application" 1 "Auxiliary channel on" 0 "Auxiliary channel off" ;
VAL_ 3221225472 AuxI_O89 3 "Not Available or Take No Action depending on application" 2 "Error Indicator or Not Used  depending on application" 1 "Auxiliary channel on" 0 "Auxiliary channel off" ;
VAL_ 3221225472 AuxI_O90 3 "Not Available or Take No Action depending on application" 2 "Error Indicator or Not Used  depending on application" 1 "Auxiliary channel on" 0 "Auxiliary channel off" ;
VAL_ 3221225472 AuxI_O91 3 "Not Available or Take No Action depending on application" 2 "Error Indicator or Not Used  depending on application" 1 "Auxiliary channel on" 0 "Auxiliary channel off" ;
VAL_ 3221225472 AuxI_O92 3 "Not Available or Take No Action depending on application" 2 "Error Indicator or Not Used  depending on application" 1 "Auxiliary channel on" 0 "Auxiliary channel off" ;
VAL_ 3221225472 AuxI_O85 3 "Not Available or Take No Action depending on application" 2 "Error Indicator or Not Used  depending on application" 1 "Auxiliary channel on" 0 "Auxiliary channel off" ;
VAL_ 3221225472 AuxI_O86 3 "Not Available or Take No Action depending on application" 2 "Error Indicator or Not Used  depending on application" 1 "Auxiliary channel on" 0 "Auxiliary channel off" ;
VAL_ 3221225472 AuxI_O87 3 "Not Available or Take No Action depending on application" 2 "Error Indicator or Not Used  depending on application" 1 "Auxiliary channel on" 0 "Auxiliary channel off" ;
VAL_ 3221225472 AuxI_O88 3 "Not Available or Take No Action depending on application" 2 "Error Indicator or Not Used  depending on application" 1 "Auxiliary channel on" 0 "Auxiliary channel off" ;
VAL_ 3221225472 AuxI_O81 3 "Not Available or Take No Action depending on application" 2 "Error Indicator or Not Used  depending on application" 1 "Auxiliary channel on" 0 "Auxiliary channel off" ;
VAL_ 3221225472 AuxI_O82 3 "Not Available or Take No Action depending on application" 2 "Error Indicator or Not Used  depending on application" 1 "Auxiliary channel on" 0 "Auxiliary channel off" ;
VAL_ 3221225472 AuxI_O83 3 "Not Available or Take No Action depending on application" 2 "Error Indicator or Not Used  depending on application" 1 "Auxiliary channel on" 0 "Auxiliary channel off" ;
VAL_ 3221225472 AuxI_O84 3 "Not Available or Take No Action depending on application" 2 "Error Indicator or Not Used  depending on application" 1 "Auxiliary channel on" 0 "Auxiliary channel off" ;
VAL_ 3221225472 TrailerBrakeStrokeAxle5Right 4 "Reserved" 7 "Not available" 6 "Sensor error" 5 "Reserved" 3 "Dragging brake" 2 "Overstroke" 1 "Nonfunctioning" 0 "OK Normal operation" ;
VAL_ 3221225472 TrailerBrakeStrokeAxle5Left 4 "Reserved" 7 "Not available" 6 "Sensor error" 5 "Reserved" 3 "Dragging brake" 2 "Overstroke" 1 "Nonfunctioning" 0 "OK Normal operation" ;
VAL_ 3221225472 TrailerBrakeStrokeAxle4Right 4 "Reserved" 7 "Not available" 6 "Sensor error" 5 "Reserved" 3 "Dragging brake" 2 "Overstroke" 1 "Nonfunctioning" 0 "OK Normal operation" ;
VAL_ 3221225472 TrailerBrakeStrokeAxle4Left 4 "Reserved" 7 "Not available" 6 "Sensor error" 5 "Reserved" 3 "Dragging brake" 2 "Overstroke" 1 "Nonfunctioning" 0 "OK Normal operation" ;
VAL_ 3221225472 TrailerBrakeStrokeAxle3Right 4 "Reserved" 7 "Not available" 6 "Sensor error" 5 "Reserved" 3 "Dragging brake" 2 "Overstroke" 1 "Nonfunctioning" 0 "OK Normal operation" ;
VAL_ 3221225472 TrailerBrakeStrokeAxle3Left 4 "Reserved" 7 "Not available" 6 "Sensor error" 5 "Reserved" 3 "Dragging brake" 2 "Overstroke" 1 "Nonfunctioning" 0 "OK Normal operation" ;
VAL_ 3221225472 TrailerBrakeStrokeAxle2Right 4 "Reserved" 7 "Not available" 6 "Sensor error" 5 "Reserved" 3 "Dragging brake" 2 "Overstroke" 1 "Nonfunctioning" 0 "OK Normal operation" ;
VAL_ 3221225472 TrailerBrakeStrokeAxle2Left 4 "Reserved" 7 "Not available" 6 "Sensor error" 5 "Reserved" 3 "Dragging brake" 2 "Overstroke" 1 "Nonfunctioning" 0 "OK Normal operation" ;
VAL_ 3221225472 TrailerBrakeStrokeAxle1Right 4 "Reserved" 7 "Not available" 6 "Sensor error" 5 "Reserved" 3 "Dragging brake" 2 "Overstroke" 1 "Nonfunctioning" 0 "OK Normal operation" ;
VAL_ 3221225472 TrailerBrakeStrokeAxle1Left 4 "Reserved" 7 "Not available" 6 "Sensor error" 5 "Reserved" 3 "Dragging brake" 2 "Overstroke" 1 "Nonfunctioning" 0 "OK Normal operation" ;
VAL_ 3221225472 TractorBrakeStrokeAxle5Right 4 "Reserved" 7 "Not available" 6 "Sensor error" 5 "Reserved" 3 "Dragging brake" 2 "Overstroke" 1 "Nonfunctioning" 0 "OK Normal operation" ;
VAL_ 3221225472 TractorBrakeStrokeAxle5Left 4 "Reserved" 7 "Not available" 6 "Sensor error" 5 "Reserved" 3 "Dragging brake" 2 "Overstroke" 1 "Nonfunctioning" 0 "OK Normal operation" ;
VAL_ 3221225472 TractorBrakeStrokeAxle4Right 4 "Reserved" 7 "Not available" 6 "Sensor error" 5 "Reserved" 3 "Dragging brake" 2 "Overstroke" 1 "Nonfunctioning" 0 "OK Normal operation" ;
VAL_ 3221225472 TractorBrakeStrokeAxle4Left 4 "Reserved" 7 "Not available" 6 "Sensor error" 5 "Reserved" 3 "Dragging brake" 2 "Overstroke" 1 "Nonfunctioning" 0 "OK Normal operation" ;
VAL_ 3221225472 TractorBrakeStrokeAxle3Right 4 "Reserved" 7 "Not available" 6 "Sensor error" 5 "Reserved" 3 "Dragging brake" 2 "Overstroke" 1 "Nonfunctioning" 0 "OK Normal operation" ;
VAL_ 3221225472 TractorBrakeStrokeAxle3Left 4 "Reserved" 7 "Not available" 6 "Sensor error" 5 "Reserved" 3 "Dragging brake" 2 "Overstroke" 1 "Nonfunctioning" 0 "OK Normal operation" ;
VAL_ 3221225472 TractorBrakeStrokeAxle2Right 4 "Reserved" 7 "Not available" 6 "Sensor error" 5 "Reserved" 3 "Dragging brake" 2 "Overstroke" 1 "Nonfunctioning" 0 "OK Normal operation" ;
VAL_ 3221225472 TractorBrakeStrokeAxle2Left 4 "Reserved" 7 "Not available" 6 "Sensor error" 5 "Reserved" 3 "Dragging brake" 2 "Overstroke" 1 "Nonfunctioning" 0 "OK Normal operation" ;
VAL_ 3221225472 TractorBrakeStrokeAxle1Right 4 "Reserved" 7 "Not available" 6 "Sensor error" 5 "Reserved" 3 "Dragging brake" 2 "Overstroke" 1 "Nonfunctioning" 0 "OK Normal operation" ;
VAL_ 3221225472 TractorBrakeStrokeAxle1Left 4 "Reserved" 7 "Not available" 6 "Sensor error" 5 "Reserved" 3 "Dragging brake" 2 "Overstroke" 1 "Nonfunctioning" 0 "OK Normal operation" ;
VAL_ 3221225472 AirCompressorStatus 3 "Not available" 2 "Error indicator" 1 "Compressor active" 0 "Compressor not active" ;
VAL_ 3221225472 RequestedACCDistanceMode 7 "not available" 6 "error condition" 5 "not defined" 4 "Requested ACC Distance Mode 5 shortest distance" 3 "Requested ACC Distance Mode 4" 2 "Requested ACC Distance Mode 3" 1 "Requested ACC Distance Mode 2" 0 "Requested ACC Distance Mode 1 largest distance" ;
VAL_ 3221225472 ACCUsageDemand 3 "dont care" 2 "reserved" 1 "driver demand for using ACC distance keeping control" 0 "driver demand for not using ACC distance keeping control" ;
VAL_ 3221225472 ForwardCollisionWarning 3 "not available" 2 "Error indicator" 1 "Collision is imminent" 0 "No warning" ;
VAL_ 3221225472 ACCDistanceAlertSignal 3 "Take no action" 2 "Reserved" 1 "ACC DAS Active" 0 "ACC DAS Not Active" ;
VAL_ 3221225472 ACCSystemShutoffWarning 3 "Take no action" 2 "Reserved" 1 "ACC SSOW Active" 0 "ACC SSOW Not Active" ;
VAL_ 3221225472 ACCTargetDetected 3 "Take no action" 2 "Reserved" 1 "Target detected" 0 "No targets detected" ;
VAL_ 3221225472 AdptiveCruiseCtrlSetDistanceMode 7 "Not available/not valid" 6 "Error condition" 5 "Conventional cruise control mode" 4 "ACC Distance mode 5 shortest distance" 3 "ACC Distance mode 4" 2 "ACC Distance mode 3" 1 "ACC Distance mode 2" 0 "ACC Distance mode 1 largest distance" ;
VAL_ 3221225472 AdaptiveCruiseCtrlMode 7 "Not available/not valid" 6 "Disabled or error condition" 5 "Finish mode" 4 "Hold mode" 3 "Overtake mode" 2 "Distance control active" 1 "Speed control active" 0 "Off Standby enabled ready for activation" ;
VAL_ 3221225472 Status2OfDoors 3 "not available" 2 "error" 1 "at least 1 bus door enabled" 0 "all bus doors are disabled" ;
VAL_ 3221225472 Ramp_WheelChairLiftPos 3 "Not available" 2 "Error" 1 "Outside bus" 0 "Inside bus" ;
VAL_ 3221225472 PosOfDoors 15 "Not available" 14 "Error" 2 "All doors closed" 1 "Closing last door" 0 "At least 1 door is open" ;
VAL_ 3221225472 FifthWheelRollWarningIndicator 3 "Not Available" 2 "error" 1 "Limit exceeded" 0 "Limit not exceeded" ;
VAL_ 3221225472 FifthWheelSliderLockIndicator 3 "Not Available" 2 "Error" 1 "Locked" 0 "Not Locked" ;
VAL_ 3221225472 FfthWhlLockCoupleStatusIndicator 3 "Not Available" 2 "Error" 1 "Successful couple detected" 0 "Incomplete or bad couple truck should not be moved" ;
VAL_ 3221225472 FfthWhlLckReadyToCoupleIndicator 3 "Not Available" 2 "Error" 1 "Lock open ready to couple" 0 "Lock not open not ready to couple" ;
VAL_ 3221225472 FifthWheelErrorStatus 13 "13  Not Used" 12 "12  Not Used" 11 "11  Not Used" 10 "10  Not Used" 4 "4  Not Used" 3 "3  Not Used" 15 "15  Not available" 9 "9  Kingpin / Lock Open Handle Pulled" 8 "8  Kingpin Missing More Than 5 Seconds" 7 "7  Coupling Timing Error" 6 "6  Coupling Sequence Error / Kingpin" 5 "5  Coupling Sequence Error" 14 "14  Not Used" 2 "2  Kingpin / Locks Open at Startup" 1 "1  Locks Closed / No Kingpin at Startup" 0 "0  Improper Couple" ;
VAL_ 3221225472 TransOilLevelMeasurementStatus 15 "Not available" 14 "Error" 13 "Conditions not valid  Other" 12 "Not defined" 9 "Conditions not valid  No request for reading" 8 "Conditions not valid  Engine speed too high" 7 "Conditions not valid  Engine speed too low" 6 "Conditions not valid  Vehicle not level" 5 "Conditions not valid  Vehicle moving output shaft speed too high" 4 "Conditions not valid  Transmission fluid temperature too high" 3 "Conditions not valid  Transmission fluid temperature too low" 2 "Conditions not valid  Transmission in gear" 1 "Conditions not valid  Settling timer still counting down" 0 "Conditions valid for transmission oil level measurement" 11 "Not defined" 10 "Not defined" ;
VAL_ 3221225472 TransOilLevelCountdownTimer 15 "Not Available" 14 "Error" 13 "Thirteen minutes" 12 "Twelve minutes" 11 "Eleven minutes" 10 "Ten minutes" 9 "Nine minutes" 8 "Eight minutes" 7 "Seven minutes" 6 "Six minutes" 5 "Five minutes" 4 "Four minutes" 3 "Three minutes" 2 "Two minutes" 1 "One minute" 0 "less than 1 minute" ;
VAL_ 3221225472 VoltageRegulatorEnabled 3 "NotAvailable" 2 "Error" 1 "RegulatingVoltage" 0 "NtRegulatingVoltageUnitDisabled" ;
VAL_ 3221225472 VoltageRegulatorSoftStartState 3 "NotAvailable" 2 "Error" 1 "SoftStartIsActive" 0 "SoftStartIsInactive" ;
VAL_ 3221225472 VltgRgltrUndrfrqncyCmpnstnEnbld 3 "NotAvailable" 2 "Error" 1 "UndrfrquencyCompensationEnabled" 0 "UndrfrqencyCompensationDisabled" ;
VAL_ 3221225472 VltgRgltrVAr_PwrFctrOprtingMode 7 "NotAvailable" 6 "Error" 5 "Reserved" 2 "VArRegulationEnabled" 1 "PowerFactorRegulationEnabled" 0 "VAr_PwrFactorRegulationDisabled" ;
VAL_ 3221225472 VltgRglatorLoadCompensationMode 7 "NotAvailable" 6 "Error" 5 "Reserved" 2 "IRLineDropCompensationEnabled" 1 "VoltageDroopCompensationEnabled" 0 "LoadCompensationDisabled" ;
VAL_ 3221225472 RunningLightCmd 3 "Dont Care" 2 "Reserved" 1 "Activate" 0 "Deactivate" ;
VAL_ 3221225472 AltBeamHeadLightCmd 3 "Dont Care" 2 "Reserved" 1 "Activate" 0 "Deactivate" ;
VAL_ 3221225472 LowBeamHeadLightCmd 3 "Dont Care" 2 "Reserved" 1 "Activate" 0 "Deactivate" ;
VAL_ 3221225472 HighBeamHeadLightCmd 3 "Dont Care" 2 "Reserved" 1 "Activate" 0 "Deactivate" ;
VAL_ 3221225472 TractorFrontFogLightsCmd 3 "Dont Care" 2 "Reserved" 1 "Activate" 0 "Deactivate" ;
VAL_ 3221225472 RotatingBeaconLightCmd 3 "Dont Care" 2 "Reserved" 1 "Activate" 0 "Deactivate" ;
VAL_ 3221225472 RightTurnSignalLightsCmd 3 "Dont Care" 2 "Reserved" 1 "Activate" 0 "Deactivate" ;
VAL_ 3221225472 LeftTurnSignalLightsCmd 3 "Dont Care" 2 "Reserved" 1 "Activate" 0 "Deactivate" ;
VAL_ 3221225472 BackUpLightAndAlarmHornCmd 3 "Dont Care" 2 "Reserved" 1 "Activate" 0 "Deactivate" ;
VAL_ 3221225472 CenterStopLightCmd 3 "Dont Care" 2 "Reserved" 1 "Activate" 0 "Deactivate" ;
VAL_ 3221225472 RightStopLightCmd 3 "Dont Care" 2 "Reserved" 1 "Activate" 0 "Deactivate" ;
VAL_ 3221225472 LeftStopLightCmd 3 "Dont Care" 2 "Reserved" 1 "Activate" 0 "Deactivate" ;
VAL_ 3221225472 ImplementClearanceLightCmd 3 "Dont Care" 2 "Reserved" 1 "Activate" 0 "Deactivate" ;
VAL_ 3221225472 TractorClearanceLightCmd 3 "Dont Care" 2 "Reserved" 1 "Activate" 0 "Deactivate" ;
VAL_ 3221225472 ImplementMarkerLightCmd 3 "Dont Care" 2 "Reserved" 1 "Activate" 0 "Deactivate" ;
VAL_ 3221225472 TractorMarkerLightCmd 3 "Dont Care" 2 "Reserved" 1 "Activate" 0 "Deactivate" ;
VAL_ 3221225472 RearFogLightCmd 3 "Dont Care" 2 "Reserved" 1 "Activate" 0 "Deactivate" ;
VAL_ 3221225472 TrctrUndrsdeMountedWorkLightsCmd 3 "Dont Care" 2 "Reserved" 1 "Activate" 0 "Deactivate" ;
VAL_ 3221225472 TrctrRearLowMountedWorkLightsCmd 3 "Dont Care" 2 "Reserved" 1 "Activate" 0 "Deactivate" ;
VAL_ 3221225472 TrctrRarHighMountedWorkLightsCmd 3 "Dont Care" 2 "Reserved" 1 "Activate" 0 "Deactivate" ;
VAL_ 3221225472 TrctrSideLowMountedWorkLightsCmd 3 "Dont Care" 2 "Reserved" 1 "Activate" 0 "Deactivate" ;
VAL_ 3221225472 TrctrSdeHighMountedWorkLightsCmd 3 "Dont Care" 2 "Reserved" 1 "Activate" 0 "Deactivate" ;
VAL_ 3221225472 TrctrFrntLowMountedWorkLightsCmd 3 "Dont Care" 2 "Reserved" 1 "Activate" 0 "Deactivate" ;
VAL_ 3221225472 TrctrFrntHghMountedWorkLightsCmd 3 "Dont Care" 2 "Reserved" 1 "Activate" 0 "Deactivate" ;
VAL_ 3221225472 ImplementOEMOption2LightCmd 3 "Dont Care" 2 "Reserved" 1 "Activate" 0 "Deactivate" ;
VAL_ 3221225472 ImplementOEMOption1LightCmd 3 "Dont Care" 2 "Reserved" 1 "Activate" 0 "Deactivate" ;
VAL_ 3221225472 ImplementRightFacingWorkLightCmd 3 "Dont Care" 2 "Reserved" 1 "Activate" 0 "Deactivate" ;
VAL_ 3221225472 ImplementLeftFacingWorkLightCmd 3 "Dont Care" 2 "Reserved" 1 "Activate" 0 "Deactivate" ;
VAL_ 3221225472 LightingDataRqCmd 3 "Dont Care" 2 "Reserved" 1 "Activate" 0 "Deactivate" ;
VAL_ 3221225472 ImplmentRightForwardWorkLightCmd 3 "Dont Care" 2 "Reserved" 1 "Activate" 0 "Deactivate" ;
VAL_ 3221225472 ImplementLeftForwardWorkLightCmd 3 "Dont Care" 2 "Reserved" 1 "Activate" 0 "Deactivate" ;
VAL_ 3221225472 ImplementRearWorkLightCmd 3 "Dont Care" 2 "Reserved" 1 "Activate" 0 "Deactivate" ;
VAL_ 3221225472 StatusOfSteerAxle 15 "Not available" 5 "Axle steering in special mode diagnosis calibration mode" 4 "Axle not active because of an error adhesion steering" 3 "Axle centered because of an error" 2 "Axle centered" 1 "Axle steering active" 0 "Axle steering not active adhesion steering" ;
VAL_ 3221225472 SteerableLiftAxleLoweringInhibit 3 "Not available" 2 "Reserved" 1 "Lowering inhibited" 0 "Lowering allowed" ;
VAL_ 3221225472 SteerType 15 "Not Available" 1 "Auxiliary steering equipment" 0 "Main steering system" ;
VAL_ 3221225472 TypeOfSteerForces 15 "Not Available" 3 "Self tracking steering equipment" 2 "Full power steering equipment" 1 "Power assisted steering equipment" 0 "Manual steering equipment" ;
VAL_ 3221225472 TypeOfSteerTrans 15 "Not available" 3 "Hybrid steering transmission" 2 "Purely electric steering transmission" 1 "Purely hydraulic steering transmission" 0 "Purely mechanical steering transmission" ;
VAL_ 3221225472 ASREngCtrlActive 3 "Not available" 2 "Reserved" 1 "ASR engine control active" 0 "ASR engine control passive but installed" ;
VAL_ 3221225472 ASRBrakeCtrlActive 3 "Not available" 2 "Reserved" 1 "ASR brake control active" 0 "ASR brake control passive but installed" ;
VAL_ 3221225472 AntiLockBrakingActive 3 "Not available" 2 "Reserved" 1 "ABS active" 0 "ABS passive but installed" ;
VAL_ 3221225472 ABSOffroadSwitch 3 "Not available" 2 "Error" 1 "ABS offroad switch active" 0 "ABS offroad switch passive" ;
VAL_ 3221225472 ASROffroadSwitch 2 "Error" 1 "ASR offroad switch active" 0 "ASR offroad switch passive" 3 "Not available" ;
VAL_ 3221225472 ASRHillHolderSwitch 3 "Not available" 2 "Error" 1 "ASR hill holder switch active" 0 "ASR hill holder switch passive" ;
VAL_ 3221225472 TractionCtrlOverrideSwitch 3 "Not available or not installed" 2 "Error" 1 "On" 0 "Off" ;
VAL_ 3221225472 AccelInterlockSwitch 3 "Not available" 2 "Error" 1 "On" 0 "Off" ;
VAL_ 3221225472 EngDerateSwitch 3 "Not available" 2 "Error" 1 "On" 0 "Off" ;
VAL_ 3221225472 EngAuxShutdownSwitch 3 "Not available" 2 "Error" 1 "On" 0 "Off" ;
VAL_ 3221225472 RemoteAccelEnableSwitch 3 "Not available" 2 "Error" 1 "On" 0 "Off" ;
VAL_ 3221225472 ABSFullyOperational 3 "Not available" 2 "Reserved" 1 "Fully Operational" 0 "Not Fully Operational" ;
VAL_ 3221225472 EBSRedWarningSignal 3 "Take no action" 2 "Reserved" 1 "On" 0 "Off" ;
VAL_ 3221225472 ABS_EBSAmberWarningSignal 3 "Take no action" 2 "Reserved" 1 "On" 0 "Off" ;
VAL_ 3221225472 ATC_ASRInformationSignal 3 "Take no action" 2 "Reserved" 1 "On" 0 "Off" ;
VAL_ 3221225472 HaltBrakeSwitch 3 "Not available" 2 "Error" 1 "Halt brake switch active" 0 "Halt brake switch passive" ;
VAL_ 3221225472 TrailerABSStatus 3 "Trailer ABS Status Information Not Available or Parameter Not Supported" 2 "Reserved" 1 "Trailer ABS Active" 0 "Trailer ABS Status Information Available But Not Active" ;
VAL_ 3221225472 TrctrMntdTrailerABSWarningSignal 3 "Take no action" 2 "Reserved" 1 "On" 0 "Off" ;
VAL_ 3221225472 ImplementRearWorkLight 3 "Not Available" 2 "Fault Detected" 1 "Activated" 0 "Deactivated" ;
VAL_ 3221225472 ImplementLeftForwardWorkLight 3 "Not Available" 2 "Fault Detected" 1 "Activated" 0 "Deactivated" ;
VAL_ 3221225472 ImplementRightForwardWorkLight 3 "Not Available" 2 "Fault Detected" 1 "Activated" 0 "Deactivated" ;
VAL_ 3221225472 ImplementLeftFacingWorkLight 3 "Not Available" 2 "Fault Detected" 1 "Activate" 0 "Deactivate" ;
VAL_ 3221225472 ImplementRightFacingWorkLight 3 "Not Available" 2 "Fault Detected" 1 "Activated" 0 "Deactivated" ;
VAL_ 3221225472 ImplementOEMOption1Light 3 "Not Available" 2 "Fault Detected" 1 "Activated" 0 "Deactivated" ;
VAL_ 3221225472 ImplementOEMOption2Light 3 "Not Available" 2 "Fault Detected" 1 "Activated" 0 "Deactivated" ;
VAL_ 3221225472 TrctorFrontHighMountedWorkLights 3 "Not Available" 2 "Fault Detected" 1 "Activated" 0 "Deactivated" ;
VAL_ 3221225472 TractorFrontLowMountedWorkLights 3 "Not Available" 2 "Fault Detected" 1 "Activated" 0 "Deactivated" ;
VAL_ 3221225472 TractorSideHighMountedWorkLights 3 "Not Available" 2 "Fault Detected" 1 "Activated" 0 "Deactivated" ;
VAL_ 3221225472 TractorSideLowMountedWorkLights 3 "Not Available" 2 "Fault Detected" 1 "Activated" 0 "Deactivated" ;
VAL_ 3221225472 TractorRearHighMountedWorkLights 3 "Not Available" 2 "Fault Detected" 1 "Activated" 0 "Deactivated" ;
VAL_ 3221225472 TractorRearLowMountedWorkLights 3 "Not Available" 2 "Fault Detected" 1 "Activated" 0 "Deactivated" ;
VAL_ 3221225472 TrctorUndersideMountedWorkLights 3 "Not Available" 2 "Fault Detected" 1 "Activated" 0 "Deactivated" ;
VAL_ 3221225472 RearFogLights 3 "Not Available" 2 "Fault Detected" 1 "Activated" 0 "Deactivated" ;
VAL_ 3221225472 TractorMarkerLight 3 "Not Available" 2 "Fault Detected" 1 "Activated" 0 "Deactivated" ;
VAL_ 3221225472 ImplementMarkerLight 3 "Not Available" 2 "Fault Detected" 1 "Activated" 0 "Deactivated" ;
VAL_ 3221225472 TractorClearanceLight 3 "Not Available" 2 "Fault Detected" 1 "Activated" 0 "Deactivated" ;
VAL_ 3221225472 ImplementClearanceLight 3 "Not Available" 2 "Fault Detected" 1 "Activated" 0 "Deactivated" ;
VAL_ 3221225472 LeftStopLight 3 "Not Available" 2 "Fault Detected" 1 "Activated" 0 "Deactivated" ;
VAL_ 3221225472 RightStopLight 3 "Not Available" 2 "Fault Detected" 1 "Activated" 0 "Deactivated" ;
VAL_ 3221225472 CenterStopLight 3 "Not Available" 2 "Fault Detected" 1 "Activated" 0 "Deactivated" ;
VAL_ 3221225472 BackUpLightAndAlarmHorn 3 "Not Available" 2 "Fault Detected" 1 "Activated" 0 "Deactivated" ;
VAL_ 3221225472 RotatingBeaconLight 3 "Not Available" 2 "Fault Detected" 1 "Activated" 0 "Deactivated" ;
VAL_ 3221225472 TractorFrontFogLights 3 "Not Available" 2 "Fault Detected" 1 "Activated" 0 "Deactivated" ;
VAL_ 3221225472 HighBeamHeadLightData 3 "Not Available" 2 "Fault Detected" 1 "Activated" 0 "Deactivated" ;
VAL_ 3221225472 LowBeamHeadLightData 3 "Not Available" 2 "Fault Detected" 1 "Activated" 0 "Deactivated" ;
VAL_ 3221225472 AltBeamHeadLightData 3 "Not Available" 2 "Fault Detected" 1 "Activated" 0 "Deactivated" ;
VAL_ 3221225472 RunningLight 3 "Not Available" 2 "Fault Detected" 1 "Activated" 0 "Deactivated" ;
VAL_ 3221225472 VehicleOverspeed 3 "Not available" 2 "Error" 1 "Overspeed" 0 "No overspeed" ;
VAL_ 3221225472 VehicleMotion 3 "Not available" 2 "Error" 1 "Vehicle motion detected" 0 "Vehicle motion not detected" ;
VAL_ 3221225472 DirectionIndicator 3 "Not available" 2 "Error" 1 "Reverse" 0 "Forward" ;
VAL_ 3221225472 TachographPerformance 3 "Not available" 2 "Error" 1 "Performance analysis" 0 "Normal performance" ;
VAL_ 3221225472 HandlingInformation 3 "Not available" 2 "Error" 1 "Handling information" 0 "No handling information" ;
VAL_ 3221225472 SystemEvent 3 "Not available" 2 "Error" 1 "Tachograph event" 0 "No tachograph event" ;
VAL_ 3221225472 DriverCardDriver2 3 "Not available" 2 "Error" 1 "Driver card present" 0 "Driver card not present" ;
VAL_ 3221225472 Driver2TimeRelatedStates 15 "Not available" 14 "Error" 13 "Other" 6 "Limit 6  16 h reached" 5 "Limit 5  15 min before 16 h not having 8h rest during the last 24h" 4 "Limit 4  9 h reached" 3 "Limit 3  15 min before 9 h" 2 "Limit 2  4  h reached" 1 "Limit 1  15 min before 4  h" 0 "Normal/No limits reached" ;
VAL_ 3221225472 DriverCardDriver1 3 "Not available" 2 "Error" 1 "Driver card present" 0 "Driver card not present" ;
VAL_ 3221225472 Driver1TimeRelatedStates 15 "Not available" 14 "Error" 13 "Other" 6 "Limit 6  16 h reached" 5 "Limit 5  15 min before 16 h not having 8h rest during the last 24h" 4 "Limit 4  9 h reached" 3 "Limit 3  15 min before 9 h" 2 "Limit 2  4  h reached" 1 "Limit 1  15 min before 4  h" 0 "Normal/No limits reached" ;
VAL_ 3221225472 Driver2WorkingState 7 "Not available" 6 "Error" 3 "Drive  behind wheel" 2 "Work  loading unloading working in an office" 1 "Driver available  short break" 0 "Rest  sleeping" ;
VAL_ 3221225472 Driver1WorkingState 7 "Not available" 6 "Error" 3 "Drive  behind wheel" 2 "Work  loading unloading working in an office" 1 "Driver available  short break" 0 "Rest  sleeping" ;
VAL_ 3221225472 RearWasherFunction 7 "Not available do not change" 4 "110 Reserved" 3 "High" 2 "Medium" 1 "Low" 0 "Off" ;
VAL_ 3221225472 FrontOperatorWasherSwitch 7 "Not available do not change" 4 "110 Reserved" 3 "High" 2 "Medium" 1 "Low" 0 "Off" ;
VAL_ 3221225472 FrontNonoperatorWasherSwitch 7 "Not available do not change" 4 "110 Reserved" 3 "High" 2 "Medium" 1 "Low" 0 "Off" ;
VAL_ 3221225472 RearWiperSwitch 7 "1110 Reserved" 6 "Mist position where external sensor controls wiper rate" 5 "Delayed 2 used for the second delay choice when the wiper switch position controls the delay" 4 "Delayed 1 used for the first delay choice when the wiper switch position controls the delay" 2 "Medium" 15 "Not available do not change" 3 "High" 1 "Low" 0 "Off" ;
VAL_ 3221225472 FrontOperatorWiperSwitch 7 "1110 Reserved" 6 "Mist position where external sensor controls wiper rate" 5 "Delayed 2 used for the second delay choice when the wiper switch position controls the delay" 4 "Delayed 1 used for the first delay choice when the wiper switch position controls the delay" 2 "Medium" 15 "Not available do not change" 3 "High" 1 "Low" 0 "Off" ;
VAL_ 3221225472 FrontNonoperatorWiperSwitch 15 "Not available do not change" 7 "1110 Reserved" 6 "Mist position where external sensor controls wiper rate" 5 "Delayed 2 used for the second delay choice when the wiper switch position controls the delay" 4 "Delayed 1 used for the first delay choice when the wiper switch position controls the delay" 3 "High" 2 "Medium" 1 "Low" 0 "Off" ;
VAL_ 3221225472 HighLowBeamSwitch 3 "Not available do not change" 2 "Error" 1 "High Beam Selected" 0 "Low Beam Selected" ;
VAL_ 3221225472 HazardLightSwitch 3 "Not available do not change" 2 "Error" 1 "Hazard Lamps to be Flashing" 0 "Hazard Lamps to be Off" ;
VAL_ 3221225472 TurnSignalSwitch 2 "Right turn to be Flashing" 15 "Not available do not change" 14 "Error to include both left and right selected simultaneously" 3 "1101 Reserved" 1 "Left Turn to be Flashing" 0 "No Turn being signaled" ;
VAL_ 3221225472 MainLightSwitch 9 "1101 Reserved" 8 "Delayed Off  The position by which the operator selects that a certain set of lamps are to come On and then are to" 4 "0111 Reserved" 2 "Headlight On  The position by which the operator selects that the headlamps are to be on" 15 "Not available do not change" 14 "Error" 3 "Headlight and Park On  The position by which the operator selects that Both the Headlamps and the Park lamps" 1 "Park On  The position by which the operator selects that the park lamps are to be on" 0 "Off  The position by which the operator selects that none of the lamps are to be on" ;
VAL_ 3221225472 WorkLightSwitch 4 "Work Light Combination 4 On  The position by which the operator selects that the lamps in the combination" 2 "Work Light Combination 2 On  The position by which the operator selects that the lamps in the combination" 15 "Not available do not change" 14 "Error" 3 "Work Light Combination 3 On  The position by which the operator selects that the lamps in the combination" 1 "Work Light Combination 1 On  The position by which the operator selects that the lamps in the combination" 0 "Off  The position by which the operator selects that none of the work lamps are to be on" ;
VAL_ 3221225472 LaneDepartureImminentLeftSide 3 "Not used" 2 "Reserved" 1 "Imminent" 0 "Not imminent" ;
VAL_ 3221225472 LaneDepartureImminentRightSide 3 "Not Used" 2 "Reserved" 1 "Imminent" 0 "Not imminent" ;
VAL_ 3221225472 LaneDepartureRight 3 "Take no action" 2 "Reserved" 1 "Middle of the vehicle departs the lane to the right side" 0 "Middle of the vehicle does not depart the lane to the right side" ;
VAL_ 3221225472 LaneDepartureLeft 3 "Take no action" 2 "Reserved" 1 "Middle of the vehicle departs the lane to the left side" 0 "Middle of the vehicle does not depart the lane to the left side" ;
VAL_ 3221225472 RetarderRoadSpeedExceededStatus 3 "Dont care/Take no action" 2 "Reserved" 1 "Road speed is above threshold and retarder is allowed to be activated" 0 "Road speed is below threshold" ;
VAL_ 3221225472 RetarderRoadSpeedLimitSwitch 3 "Not Available" 2 "Error Indicator" 1 "Road speed limiting by retarder is enabled The road speed that the retarder will limit will be determined when the" 0 "Road speed limiting by retarder is disabled" ;
VAL_ 3221225472 RetarderRequestingBrakeLight 3 "Not available/Take no action" 2 "Reserved" 1 "Retarder is requesting that the brake lights are illuminated" 0 "Retarder is not requesting that the brake lights are illuminated" ;
VAL_ 3221225472 EngCoolantLoadIncrease 3 "Not available" 2 "Error" 1 "Coolant load increase possible" 0 "No coolant load increase" ;
VAL_ 3221225472 RetarderEnableShiftAssistSwitch 3 "Not available" 2 "Error" 1 "Retarder  shift assist enabled" 0 "Retarder  shift assist disabled" ;
VAL_ 3221225472 RetarderEnableBrakeAssistSwitch 3 "Not available" 2 "Error" 1 "Retarder  brake assist enabled" 0 "Retarder  brake assist disabled" ;
VAL_ 3221225472 SCRThermalManagementActive 3 "Dont care" 2 "Reserved" 1 "SCR Thermal Management is active" 0 "SCR Thermal Management is not active" ;
VAL_ 3221225472 DPFThermalManagementActive 3 "Dont care" 2 "Reserved" 1 "DPF Thermal Management is active" 0 "DPF Thermal Management is not active" ;
VAL_ 3221225472 MmntaryEngMaxPowerEnableFeedback 3 "dont care" 2 "reserved" 1 "supported" 0 "disabled" ;
VAL_ 3221225472 VhcleAccelerationRateLimitStatus 3 "Not available" 2 "Reserved" 1 "Limit active" 0 "Limit not active" ;
VAL_ 3221225472 AccelPedal2LowIdleSwitch 3 "Not available" 2 "Error" 1 "Accelerator pedal 2 in low idle condition" 0 "Accelerator pedal 2 not in low idle condition" ;
VAL_ 3221225472 RoadSpeedLimitStatus 3 "Not available" 2 "Error" 1 "Not Active" 0 "Active" ;
VAL_ 3221225472 AccelPedalKickdownSwitch 3 "Not available" 2 "Error" 1 "Kickdown active" 0 "Kickdown passive" ;
VAL_ 3221225472 AccelPedal1LowIdleSwitch 3 "Not available" 2 "Error" 1 "Accelerator pedal 1 in low idle condition" 0 "Accelerator pedal 1 not in low idle condition" ;
VAL_ 3221225472 EngShutdownOverrideSwitch 3 "Not available" 2 "Error" 1 "On" 0 "Off" ;
VAL_ 3221225472 EngTestModeSwitch 3 "Not available" 2 "Error" 1 "On" 0 "Off" ;
VAL_ 3221225472 EngIdleDecrementSwitch 3 "Not available" 2 "Error" 1 "On" 0 "Off" ;
VAL_ 3221225472 EngIdleIncrementSwitch 3 "Not available" 2 "Error" 1 "On" 0 "Off" ;
VAL_ 3221225472 CruiseCtrlStates 7 "Not available" 6 "Accelerator Override" 5 "Set" 4 "Resume" 3 "Decelerate" 2 "Accelerate" 1 "Hold" 0 "Off/Disabled" ;
VAL_ 3221225472 PTOGovernorState 31 "Not available" 19 "PTO set speed memory 2" 18 "PTO set speed memory 1" 17 "Preprogrammed set speed 8" 16 "Preprogrammed set speed 7" 15 "Preprogrammed set speed 6" 14 "Preprogrammed set speed 5" 13 "Preprogrammed set speed 4" 12 "Preprogrammed set speed 3" 11 "Preprogrammed set speed 2" 10 "Preprogrammed set speed 1" 9 "Accelerator Override" 8 "Accelerate" 7 "Resume" 6 "Decelerate/Coast" 5 "Set" 4 "Remote Standby" 3 "Standby" 2 "Remote Hold" 1 "Hold" 0 "Off/Disabled" ;
VAL_ 3221225472 CruiseCtrlAccelerateSwitch 3 "Not available" 2 "Error" 1 "Cruise control activator in position accelerate" 0 "Cruise control activator not in the position accelerate" ;
VAL_ 3221225472 CruiseCtrlResumeSwitch 3 "Not available" 2 "Error" 1 "Cruise control activator in position resume" 0 "Cruise control activator not in the position resume" ;
VAL_ 3221225472 CruiseCtrlCoastSwitch 3 "Not available" 2 "Error" 1 "Cruise control activator in position coast" 0 "Cruise control activator not in the position coast" ;
VAL_ 3221225472 CruiseCtrlSetSwitch 3 "Not available" 2 "Error" 1 "Cruise control activator in position set" 0 "Cruise control activator not in the position set" ;
VAL_ 3221225472 ClutchSwitch 3 "Not available" 2 "Error" 1 "Clutch pedal depressed" 0 "Clutch pedal released" ;
VAL_ 3221225472 BrakeSwitch 3 "Not Available" 2 "Error" 1 "Brake pedal depressed" 0 "Brake pedal released" ;
VAL_ 3221225472 CruiseCtrlEnableSwitch 3 "Not available" 2 "Error" 1 "Cruise control enabled" 0 "Cruise control disabled" ;
VAL_ 3221225472 CruiseCtrlActive 3 "Not available" 2 "Error" 1 "Cruise control switched on" 0 "Cruise control switched off" ;
VAL_ 3221225472 ParkBrakeReleaseInhibitRq 3 "Unavailable" 2 "SAEReserved" 1 "ParkBrakeReleaseInhibitRqed" 0 "ParkBrakeReleaseInhibitNotRqed" ;
VAL_ 3221225472 CruiseCtrlPauseSwitch 3 "Take No Action" 2 "Error Indicator" 1 "On" 0 "Off" ;
VAL_ 3221225472 ParkingBrakeSwitch 3 "Not available" 2 "Error" 1 "Parking brake set" 0 "Parking brake not set" ;
VAL_ 3221225472 TwoSpeedAxleSwitch 3 "Not available" 2 "Error" 1 "High speed range" 0 "Low speed range" ;
VAL_ 2566799614 LeftTurnSignalLights 3 "Not Available" 2 "Fault Detected" 1 "Activated" 0 "Deactivated" ;
VAL_ 2566799614 RightTurnSignalLights 3 "Not Available" 2 "Fault Detected" 1 "Activated" 0 "Deactivated" ;
VAL_ 2565865739 EBSBrakeSwitch 3 "Not available" 2 "Error" 1 "Brake pedal is being pressed" 0 "Brake pedal is not being pressed" ;
VAL_ 2565867787 SteerWheelAngleSensorType 3 "Not Available" 2 "Reserved" 1 "Absolute measuring principle" 0 "Relative measuring principle" ;
